VERSION ""

NS_ :

BS_:

BU_: WCM VPM VLM VKM UVM TIM TEST_TOOL_2 TEST_TOOL_1 TCP TCM TCCM3 TCCM STC SRR_SRR SRR_SLR SRR_RR SRR_RF SRR_LR_CR SRR_LF SIB SDM SCL SBZA_R SBZA_L SBM SADS RadioLow RSC RDCM PTM PDR PA NVM MTCM_R MTCM_L MSM_RR MSM_P MSM_LR MSM_D MSB2 MSB1 MRCM_R MRCM_L MFC LRR_HC LRR LIB1 IPC ICS_Info ICCM HVAC_FP_R HVAC_FP_F HUD_CAN HDLM FCM_LC FCM EPS EOCM_HCP2 EOCM_HCP1 EOCM ELM ECP_X1 ECP_MC ECP_E ECM EBCM DMS DEFC DCM CSM CMMb CMMa CGM BSM_MH BSM BCM ARS ARB APA AOS AMP ALC AHS AHL_AFL AGC

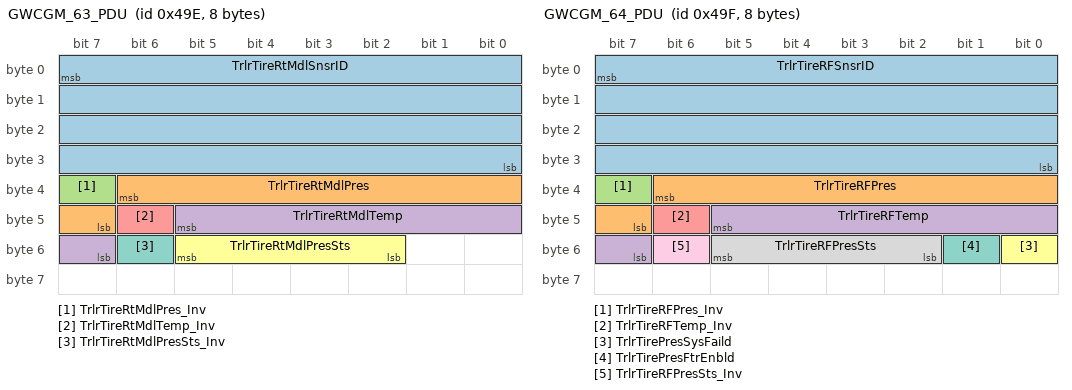
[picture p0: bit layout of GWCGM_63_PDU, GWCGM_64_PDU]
BO_ 1182 GWCGM_63_PDU: 8 CGM
 SG_ TrlrTireRtMdlSnsrID : 7|32@0+ (1,0) [0|4.29497e+009] "" CSM
 SG_ TrlrTireRtMdlPres : 38|8@0+ (4,0) [0|1020] "kPaG" CSM,VKM
 SG_ TrlrTireRtMdlPres_Inv : 39|1@0+ (1,0) [0|1] "" CSM,VKM
 SG_ TrlrTireRtMdlTemp : 45|7@0+ (1,-20) [-20|107] "degC" CSM
 SG_ TrlrTireRtMdlTemp_Inv : 46|1@0+ (1,0) [0|1] "" CSM
 SG_ TrlrTireRtMdlPresSts : 53|4@0+ (1,0) [0|8] "" CSM,VKM
 SG_ TrlrTireRtMdlPresSts_Inv : 54|1@0+ (1,0) [0|1] "" CSM,VKM

BO_ 1183 GWCGM_64_PDU: 8 CGM
 SG_ TrlrTireRFSnsrID : 7|32@0+ (1,0) [0|4.29497e+009] "" CSM
 SG_ TrlrTireRFPres : 38|8@0+ (4,0) [0|1020] "kPaG" CSM,VKM
 SG_ TrlrTireRFPres_Inv : 39|1@0+ (1,0) [0|1] "" CSM,VKM
 SG_ TrlrTireRFTemp : 45|7@0+ (1,-20) [-20|107] "degC" CSM
 SG_ TrlrTireRFTemp_Inv : 46|1@0+ (1,0) [0|1] "" CSM
 SG_ TrlrTirePresSysFaild : 48|1@0+ (1,0) [0|1] "" CSM
 SG_ TrlrTirePresFtrEnbld : 49|1@0+ (1,0) [0|1] "" CSM
 SG_ TrlrTireRFPresSts : 53|4@0+ (1,0) [0|8] "" CSM,VKM
 SG_ TrlrTireRFPresSts_Inv : 54|1@0+ (1,0) [0|1] "" CSM,VKM

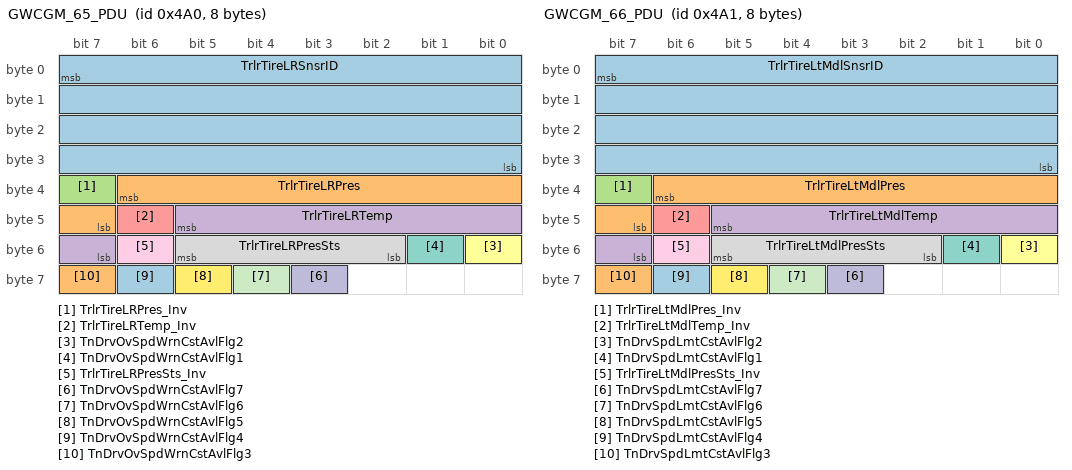
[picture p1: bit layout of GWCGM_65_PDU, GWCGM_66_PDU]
BO_ 1184 GWCGM_65_PDU: 8 CGM
 SG_ TrlrTireLRSnsrID : 7|32@0+ (1,0) [0|4.29497e+009] "" CSM
 SG_ TrlrTireLRPres : 38|8@0+ (4,0) [0|1020] "kPaG" CSM,VKM
 SG_ TrlrTireLRPres_Inv : 39|1@0+ (1,0) [0|1] "" CSM,VKM
 SG_ TrlrTireLRTemp : 45|7@0+ (1,-20) [-20|107] "degC" CSM
 SG_ TrlrTireLRTemp_Inv : 46|1@0+ (1,0) [0|1] "" CSM
 SG_ TnDrvOvSpdWrnCstAvlFlg2 : 48|1@0+ (1,0) [0|1] "" CSM,RadioLow,TCP
 SG_ TnDrvOvSpdWrnCstAvlFlg1 : 49|1@0+ (1,0) [0|1] "" CSM,RadioLow,TCP
 SG_ TrlrTireLRPresSts : 53|4@0+ (1,0) [0|8] "" CSM,VKM
 SG_ TrlrTireLRPresSts_Inv : 54|1@0+ (1,0) [0|1] "" CSM,VKM
 SG_ TnDrvOvSpdWrnCstAvlFlg7 : 59|1@0+ (1,0) [0|1] "" CSM,RadioLow,TCP
 SG_ TnDrvOvSpdWrnCstAvlFlg6 : 60|1@0+ (1,0) [0|1] "" CSM,RadioLow,TCP
 SG_ TnDrvOvSpdWrnCstAvlFlg5 : 61|1@0+ (1,0) [0|1] "" CSM,RadioLow,TCP
 SG_ TnDrvOvSpdWrnCstAvlFlg4 : 62|1@0+ (1,0) [0|1] "" CSM,RadioLow,TCP
 SG_ TnDrvOvSpdWrnCstAvlFlg3 : 63|1@0+ (1,0) [0|1] "" CSM,RadioLow,TCP

BO_ 1185 GWCGM_66_PDU: 8 CGM
 SG_ TrlrTireLtMdlSnsrID : 7|32@0+ (1,0) [0|4.29497e+009] "" CSM
 SG_ TrlrTireLtMdlPres : 38|8@0+ (4,0) [0|1020] "kPaG" CSM,VKM
 SG_ TrlrTireLtMdlPres_Inv : 39|1@0+ (1,0) [0|1] "" CSM,VKM
 SG_ TrlrTireLtMdlTemp : 45|7@0+ (1,-20) [-20|107] "degC" CSM
 SG_ TrlrTireLtMdlTemp_Inv : 46|1@0+ (1,0) [0|1] "" CSM
 SG_ TnDrvSpdLmtCstAvlFlg2 : 48|1@0+ (1,0) [0|1] "" CSM,RadioLow,TCP
 SG_ TnDrvSpdLmtCstAvlFlg1 : 49|1@0+ (1,0) [0|1] "" CSM,RadioLow,TCP
 SG_ TrlrTireLtMdlPresSts : 53|4@0+ (1,0) [0|8] "" CSM,VKM
 SG_ TrlrTireLtMdlPresSts_Inv : 54|1@0+ (1,0) [0|1] "" CSM,VKM
 SG_ TnDrvSpdLmtCstAvlFlg7 : 59|1@0+ (1,0) [0|1] "" CSM,RadioLow
 SG_ TnDrvSpdLmtCstAvlFlg6 : 60|1@0+ (1,0) [0|1] "" CSM,RadioLow,TCP
 SG_ TnDrvSpdLmtCstAvlFlg5 : 61|1@0+ (1,0) [0|1] "" CSM,RadioLow,TCP
 SG_ TnDrvSpdLmtCstAvlFlg4 : 62|1@0+ (1,0) [0|1] "" CSM,RadioLow,TCP
 SG_ TnDrvSpdLmtCstAvlFlg3 : 63|1@0+ (1,0) [0|1] "" CSM,RadioLow,TCP

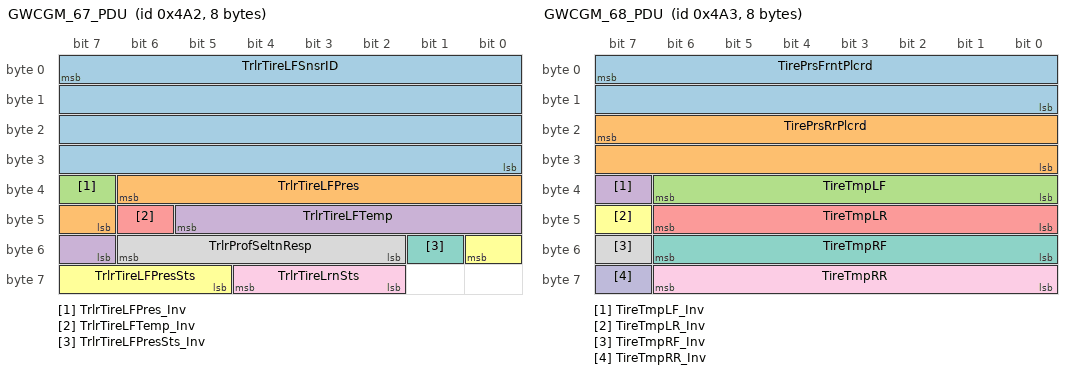
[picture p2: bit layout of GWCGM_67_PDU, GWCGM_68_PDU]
BO_ 1186 GWCGM_67_PDU: 8 CGM
 SG_ TrlrTireLFSnsrID : 7|32@0+ (1,0) [0|4.29497e+009] "" CSM
 SG_ TrlrTireLFPres : 38|8@0+ (4,0) [0|1020] "kPaG" CSM,VKM
 SG_ TrlrTireLFPres_Inv : 39|1@0+ (1,0) [0|1] "" CSM,VKM
 SG_ TrlrTireLFTemp : 45|7@0+ (1,-20) [-20|107] "degC" CSM
 SG_ TrlrTireLFTemp_Inv : 46|1@0+ (1,0) [0|1] "" CSM
 SG_ TrlrTireLFPresSts : 48|4@0+ (1,0) [0|8] "" CSM,VKM
 SG_ TrlrTireLFPresSts_Inv : 49|1@0+ (1,0) [0|1] "" CSM,VKM
 SG_ TrlrProfSeltnResp : 54|5@0+ (1,0) [0|21] "" CSM
 SG_ TrlrTireLrnSts : 60|3@0+ (1,0) [0|4] "" CSM

BO_ 1187 GWCGM_68_PDU: 8 CGM
 SG_ TirePrsFrntPlcrd : 7|16@0+ (0.0625,0) [0|4095.94] "kPaG" TCP
 SG_ TirePrsRrPlcrd : 23|16@0+ (0.0625,0) [0|4095.94] "kPaG" TCP
 SG_ TireTmpLF : 38|7@0+ (1,-20) [-20|107] "deg C" CSM,PDR
 SG_ TireTmpLF_Inv : 39|1@0+ (1,0) [0|1] "" CSM,PDR
 SG_ TireTmpLR : 46|7@0+ (1,-20) [-20|107] "deg C" CSM,PDR
 SG_ TireTmpLR_Inv : 47|1@0+ (1,0) [0|1] "" CSM,PDR
 SG_ TireTmpRF : 54|7@0+ (1,-20) [-20|107] "deg C" CSM,PDR
 SG_ TireTmpRF_Inv : 55|1@0+ (1,0) [0|1] "" CSM,PDR
 SG_ TireTmpRR : 62|7@0+ (1,-20) [-20|107] "deg C" CSM,PDR
 SG_ TireTmpRR_Inv : 63|1@0+ (1,0) [0|1] "" CSM,PDR

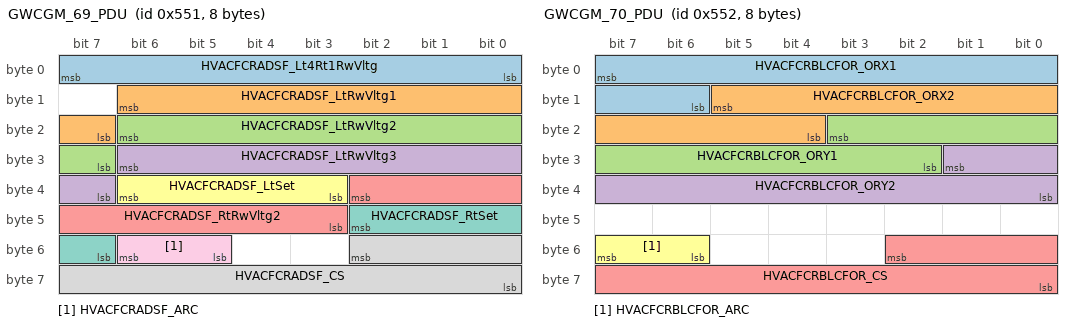
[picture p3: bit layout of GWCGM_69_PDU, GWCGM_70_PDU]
BO_ 1361 GWCGM_69_PDU: 8 HVAC_FP_F
 SG_ HVACFCRADSF_Lt4Rt1RwVltg : 7|8@0+ (0.02,0) [0|5.1] "Volts" Vector__XXX
 SG_ HVACFCRADSF_LtRwVltg1 : 14|8@0+ (0.02,0) [0|5.1] "Volts" Vector__XXX
 SG_ HVACFCRADSF_LtRwVltg2 : 22|8@0+ (0.02,0) [0|5.1] "Volts" Vector__XXX
 SG_ HVACFCRADSF_LtRwVltg3 : 30|8@0+ (0.02,0) [0|5.1] "Volts" Vector__XXX
 SG_ HVACFCRADSF_RtRwVltg2 : 34|8@0+ (0.02,0) [0|5.1] "Volts" Vector__XXX
 SG_ HVACFCRADSF_LtSet : 38|4@0+ (1,0) [0|8] "" Vector__XXX
 SG_ HVACFCRADSF_RtSet : 42|4@0+ (1,0) [0|8] "" Vector__XXX
 SG_ HVACFCRADSF_CS : 50|11@0+ (1,0) [0|2047] "" Vector__XXX
 SG_ HVACFCRADSF_ARC : 54|2@0+ (1,0) [0|3] "Counts" Vector__XXX

BO_ 1362 GWCGM_70_PDU: 8 HVAC_FP_F
 SG_ HVACFCRBLCFOR_ORX1 : 7|10@0+ (1,0) [0|1023] "Counts" Vector__XXX
 SG_ HVACFCRBLCFOR_ORX2 : 13|10@0+ (1,0) [0|1023] "Counts" Vector__XXX
 SG_ HVACFCRBLCFOR_ORY1 : 19|10@0+ (1,0) [0|1023] "Counts" Vector__XXX
 SG_ HVACFCRBLCFOR_ORY2 : 25|10@0+ (1,0) [0|1023] "Counts" Vector__XXX
 SG_ HVACFCRBLCFOR_CS : 50|11@0+ (1,0) [0|2047] "" Vector__XXX
 SG_ HVACFCRBLCFOR_ARC : 55|2@0+ (1,0) [0|3] "Counts" Vector__XXX

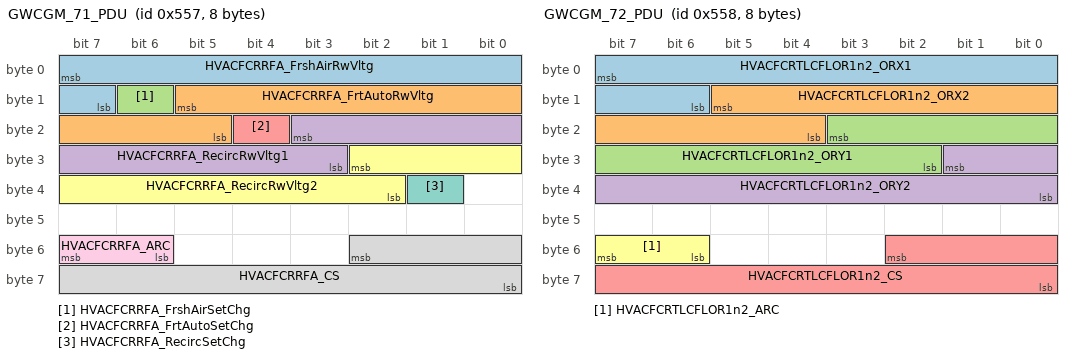
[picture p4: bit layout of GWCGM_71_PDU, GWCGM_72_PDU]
BO_ 1367 GWCGM_71_PDU: 8 HVAC_FP_F
 SG_ HVACFCRRFA_FrshAirRwVltg : 7|9@0+ (0.01,0) [0|5.11] "Volts" Vector__XXX
 SG_ HVACFCRRFA_FrtAutoRwVltg : 13|9@0+ (0.01,0) [0|5.11] "Volts" Vector__XXX
 SG_ HVACFCRRFA_FrshAirSetChg : 14|1@0+ (1,0) [0|1] "" Vector__XXX
 SG_ HVACFCRRFA_RecircRwVltg1 : 19|9@0+ (0.01,0) [0|5.11] "Volts" Vector__XXX
 SG_ HVACFCRRFA_FrtAutoSetChg : 20|1@0+ (1,0) [0|1] "" Vector__XXX
 SG_ HVACFCRRFA_RecircRwVltg2 : 26|9@0+ (0.01,0) [0|5.11] "Volts" Vector__XXX
 SG_ HVACFCRRFA_RecircSetChg : 33|1@0+ (1,0) [0|1] "" Vector__XXX
 SG_ HVACFCRRFA_CS : 50|11@0+ (1,0) [0|2047] "" Vector__XXX
 SG_ HVACFCRRFA_ARC : 55|2@0+ (1,0) [0|3] "Counts" Vector__XXX

BO_ 1368 GWCGM_72_PDU: 8 HVAC_FP_F
 SG_ HVACFCRTLCFLOR1n2_ORX1 : 7|10@0+ (1,0) [0|1023] "Counts" Vector__XXX
 SG_ HVACFCRTLCFLOR1n2_ORX2 : 13|10@0+ (1,0) [0|1023] "Counts" Vector__XXX
 SG_ HVACFCRTLCFLOR1n2_ORY1 : 19|10@0+ (1,0) [0|1023] "Counts" Vector__XXX
 SG_ HVACFCRTLCFLOR1n2_ORY2 : 25|10@0+ (1,0) [0|1023] "Counts" Vector__XXX
 SG_ HVACFCRTLCFLOR1n2_CS : 50|11@0+ (1,0) [0|2047] "" Vector__XXX
 SG_ HVACFCRTLCFLOR1n2_ARC : 55|2@0+ (1,0) [0|3] "Counts" Vector__XXX

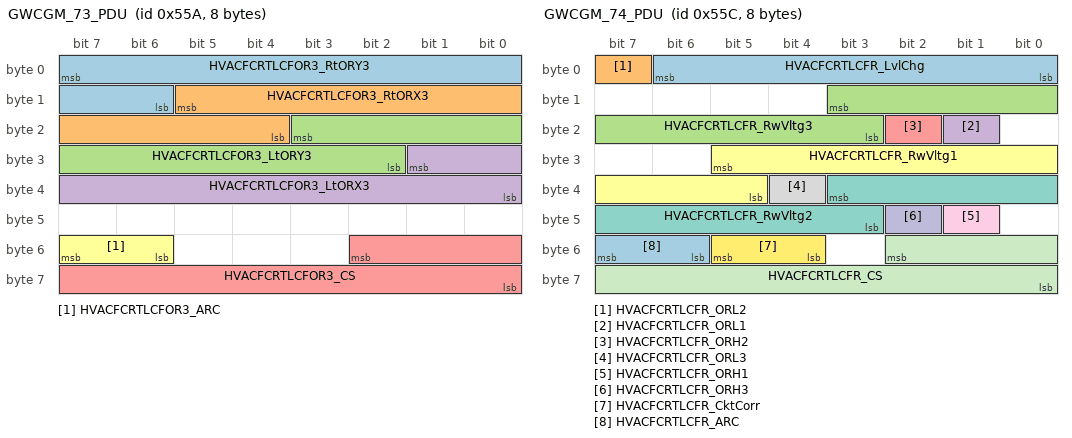
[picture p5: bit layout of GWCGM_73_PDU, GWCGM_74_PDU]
BO_ 1370 GWCGM_73_PDU: 8 HVAC_FP_F
 SG_ HVACFCRTLCFOR3_RtORY3 : 7|10@0+ (1,0) [0|1023] "Counts" Vector__XXX
 SG_ HVACFCRTLCFOR3_RtORX3 : 13|10@0+ (1,0) [0|1023] "Counts" Vector__XXX
 SG_ HVACFCRTLCFOR3_LtORY3 : 19|10@0+ (1,0) [0|1023] "Counts" Vector__XXX
 SG_ HVACFCRTLCFOR3_LtORX3 : 25|10@0+ (1,0) [0|1023] "Counts" Vector__XXX
 SG_ HVACFCRTLCFOR3_CS : 50|11@0+ (1,0) [0|2047] "" Vector__XXX
 SG_ HVACFCRTLCFOR3_ARC : 55|2@0+ (1,0) [0|3] "" Vector__XXX

BO_ 1372 GWCGM_74_PDU: 8 HVAC_FP_F
 SG_ HVACFCRTLCFR_LvlChg : 6|7@0- (1,0) [-64|63] "Counts" Vector__XXX
 SG_ HVACFCRTLCFR_ORL2 : 7|1@0+ (1,0) [0|1] "" Vector__XXX
 SG_ HVACFCRTLCFR_RwVltg3 : 11|9@0+ (0.01,0) [0|5.11] "Volts" Vector__XXX
 SG_ HVACFCRTLCFR_ORL1 : 17|1@0+ (1,0) [0|1] "" Vector__XXX
 SG_ HVACFCRTLCFR_ORH2 : 18|1@0+ (1,0) [0|1] "" Vector__XXX
 SG_ HVACFCRTLCFR_RwVltg1 : 29|9@0+ (0.01,0) [0|5.11] "Volts" Vector__XXX
 SG_ HVACFCRTLCFR_RwVltg2 : 35|9@0+ (0.01,0) [0|5.11] "Volts" Vector__XXX
 SG_ HVACFCRTLCFR_ORL3 : 36|1@0+ (1,0) [0|1] "" Vector__XXX
 SG_ HVACFCRTLCFR_ORH1 : 41|1@0+ (1,0) [0|1] "" Vector__XXX
 SG_ HVACFCRTLCFR_ORH3 : 42|1@0+ (1,0) [0|1] "" Vector__XXX
 SG_ HVACFCRTLCFR_CS : 50|11@0+ (1,0) [0|2047] "" Vector__XXX
 SG_ HVACFCRTLCFR_CktCorr : 53|2@0+ (1,0) [0|2] "" Vector__XXX
 SG_ HVACFCRTLCFR_ARC : 55|2@0+ (1,0) [0|3] "" Vector__XXX

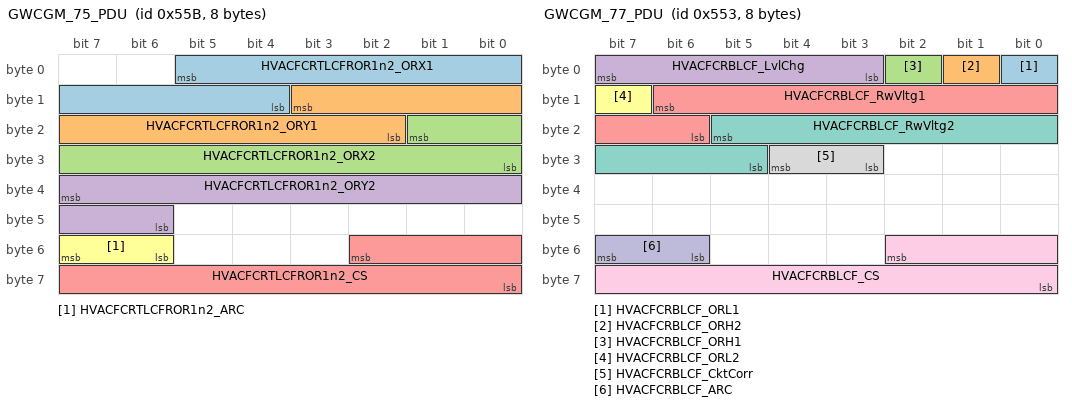
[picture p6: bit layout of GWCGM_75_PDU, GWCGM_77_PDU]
BO_ 1371 GWCGM_75_PDU: 8 HVAC_FP_F
 SG_ HVACFCRTLCFROR1n2_ORX1 : 5|10@0+ (1,0) [0|1023] "Counts" Vector__XXX
 SG_ HVACFCRTLCFROR1n2_ORY1 : 11|10@0+ (1,0) [0|1023] "Counts" Vector__XXX
 SG_ HVACFCRTLCFROR1n2_ORX2 : 17|10@0+ (1,0) [0|1023] "Counts" Vector__XXX
 SG_ HVACFCRTLCFROR1n2_ORY2 : 39|10@0+ (1,0) [0|1023] "Counts" Vector__XXX
 SG_ HVACFCRTLCFROR1n2_CS : 50|11@0+ (1,0) [0|2047] "" Vector__XXX
 SG_ HVACFCRTLCFROR1n2_ARC : 55|2@0+ (1,0) [0|3] "Counts" Vector__XXX

BO_ 1295 GWCGM_76_PDU: 8 HVAC_FP_F
 SG_ HVACFCRACH_CompSetRwVltg : 7|9@0+ (0.01,0) [0|5.11] "Volts" Vector__XXX
 SG_ HVACFCRACH_HtrSetRwVltg : 12|9@0+ (0.01,0) [0|5.11] "Volts" Vector__XXX
 SG_ HVACFCRACH_CompSetChg : 13|1@0+ (1,0) [0|1] "" Vector__XXX
 SG_ HVACFCRACH_HtrSetChg : 14|1@0+ (1,0) [0|1] "" Vector__XXX
 SG_ HVACFCRACH_HtrSet : 17|2@0+ (1,0) [0|2] "" Vector__XXX
 SG_ HVACFCRACH_ARC : 19|2@0+ (1,0) [0|3] "Counts" Vector__XXX
 SG_ HVACFCRL_RwVltg : 31|9@0+ (0.01,0) [0|5.11] "Volts" Vector__XXX
 SG_ RHVSLF_HtdCushBckLvlChgDn : 32|1@0+ (1,0) [0|1] "" Vector__XXX
 SG_ RHVSLF_HtdBckLvlChgDn : 33|1@0+ (1,0) [0|1] "" Vector__XXX
 SG_ RHVSLF_VntLvlChgUp : 34|1@0+ (1,0) [0|1] "" Vector__XXX
 SG_ RHVSLF_VntLvlChgDn : 35|1@0+ (1,0) [0|1] "" Vector__XXX
 SG_ RHVSLF_HtdCushBckLvlChgUp : 36|1@0+ (1,0) [0|1] "" Vector__XXX
 SG_ RHVSLF_HtdBckLvlChgUp : 37|1@0+ (1,0) [0|1] "" Vector__XXX
 SG_ HVACFCRL_SetChg : 38|1@0+ (1,0) [0|1] "" Vector__XXX
 SG_ HtdStBckCushStckSwLF : 40|1@0+ (1,0) [0|1] "" Vector__XXX
 SG_ HVACFrtCtlReqSyncRrSetChg : 41|1@0+ (1,0) [0|1] "" Vector__XXX
 SG_ RHVSRF_VntLvlChgUp : 42|1@0+ (1,0) [0|1] "" Vector__XXX
 SG_ RHVSRF_HtdCushBckLvlChgUp : 43|1@0+ (1,0) [0|1] "" Vector__XXX
 SG_ RHVSRF_HtdCushBckLvlChgDn : 44|1@0+ (1,0) [0|1] "" Vector__XXX
 SG_ RHVSRF_VntLvlChgDn : 45|1@0+ (1,0) [0|1] "" Vector__XXX
 SG_ RHVSRF_HtdBckLvlChgUp : 46|1@0+ (1,0) [0|1] "" Vector__XXX
 SG_ RHVSRF_HtdBckLvlChgDn : 47|1@0+ (1,0) [0|1] "" Vector__XXX
 SG_ VntStStckSwRF : 49|1@0+ (1,0) [0|1] "" Vector__XXX
 SG_ VntStStckSwLF : 50|1@0+ (1,0) [0|1] "" Vector__XXX
 SG_ HtdVntStSwActvRF : 51|1@0+ (1,0) [0|1] "" Vector__XXX
 SG_ HtdVntStSwActvLF : 52|1@0+ (1,0) [0|1] "" Vector__XXX
 SG_ HtdStBckStckSwRF : 53|1@0+ (1,0) [0|1] "" Vector__XXX
 SG_ HtdStBckStckSwLF : 54|1@0+ (1,0) [0|1] "" Vector__XXX
 SG_ HtdStBckCushStckSwRF : 55|1@0+ (1,0) [0|1] "" Vector__XXX

BO_ 1363 GWCGM_77_PDU: 8 HVAC_FP_F
 SG_ HVACFCRBLCF_ORL1 : 0|1@0+ (1,0) [0|1] "" Vector__XXX
 SG_ HVACFCRBLCF_ORH2 : 1|1@0+ (1,0) [0|1] "" Vector__XXX
 SG_ HVACFCRBLCF_ORH1 : 2|1@0+ (1,0) [0|1] "" Vector__XXX
 SG_ HVACFCRBLCF_LvlChg : 7|5@0- (1,0) [-16|15] "Counts" Vector__XXX
 SG_ HVACFCRBLCF_RwVltg1 : 14|9@0+ (0.01,0) [0|5.11] "Volts" Vector__XXX
 SG_ HVACFCRBLCF_ORL2 : 15|1@0+ (1,0) [0|1] "" Vector__XXX
 SG_ HVACFCRBLCF_RwVltg2 : 21|9@0+ (0.01,0) [0|5.11] "Volts" Vector__XXX
 SG_ HVACFCRBLCF_CktCorr : 28|2@0+ (1,0) [0|2] "" Vector__XXX
 SG_ HVACFCRBLCF_CS : 50|11@0+ (1,0) [0|2047] "" Vector__XXX
 SG_ HVACFCRBLCF_ARC : 55|2@0+ (1,0) [0|3] "Counts" Vector__XXX

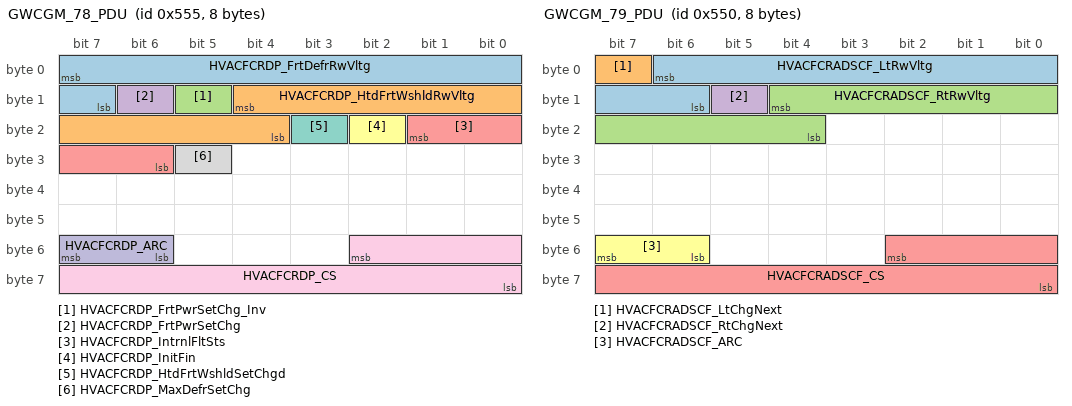
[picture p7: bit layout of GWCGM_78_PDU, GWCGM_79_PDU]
BO_ 1365 GWCGM_78_PDU: 8 HVAC_FP_F
 SG_ HVACFCRDP_FrtDefrRwVltg : 7|9@0+ (0.01,0) [0|5.11] "Volts" Vector__XXX
 SG_ HVACFCRDP_HtdFrtWshldRwVltg : 12|9@0+ (0.01,0) [0|5.11] "Volts" Vector__XXX
 SG_ HVACFCRDP_FrtPwrSetChg_Inv : 13|1@0+ (1,0) [0|1] "" Vector__XXX
 SG_ HVACFCRDP_FrtPwrSetChg : 14|1@0+ (1,0) [0|1] "" Vector__XXX
 SG_ HVACFCRDP_IntrnlFltSts : 17|4@0+ (1,0) [0|15] "" Vector__XXX
 SG_ HVACFCRDP_InitFin : 18|1@0+ (1,0) [0|1] "" Vector__XXX
 SG_ HVACFCRDP_HtdFrtWshldSetChgd : 19|1@0+ (1,0) [0|1] "" Vector__XXX
 SG_ HVACFCRDP_MaxDefrSetChg : 29|1@0+ (1,0) [0|1] "" Vector__XXX
 SG_ HVACFCRDP_CS : 50|11@0+ (1,0) [0|2047] "" Vector__XXX
 SG_ HVACFCRDP_ARC : 55|2@0+ (1,0) [0|3] "Counts" Vector__XXX

BO_ 1360 GWCGM_79_PDU: 8 HVAC_FP_F
 SG_ HVACFCRADSCF_LtRwVltg : 6|9@0+ (0.01,0) [0|5.11] "Volts" Vector__XXX
 SG_ HVACFCRADSCF_LtChgNext : 7|1@0+ (1,0) [0|1] "" Vector__XXX
 SG_ HVACFCRADSCF_RtRwVltg : 12|9@0+ (0.01,0) [0|5.11] "Volts" Vector__XXX
 SG_ HVACFCRADSCF_RtChgNext : 13|1@0+ (1,0) [0|1] "" Vector__XXX
 SG_ HVACFCRADSCF_CS : 50|11@0+ (1,0) [0|2047] "" Vector__XXX
 SG_ HVACFCRADSCF_ARC : 55|2@0+ (1,0) [0|3] "Counts" Vector__XXX

BO_ 1299 GWCGM_80_PDU: 6 HVAC_FP_F
 SG_ HVACFCRBLR_RwVltg2 : 2|9@0+ (0.01,0) [0|5.11] "Volts" Vector__XXX
 SG_ HVACFCRBLR_LvlChg : 7|5@0- (1,0) [-16|15] "" Vector__XXX
 SG_ HVACFCRBLR_Lvl : 8|4@0+ (1,0) [0|15] "" Vector__XXX
 SG_ HVACFCRBLR_LvlActv : 9|1@0+ (1,0) [0|1] "" Vector__XXX
 SG_ HVACFCRBLR_RwVltg1 : 20|9@0+ (0.01,0) [0|5.11] "Volts" Vector__XXX

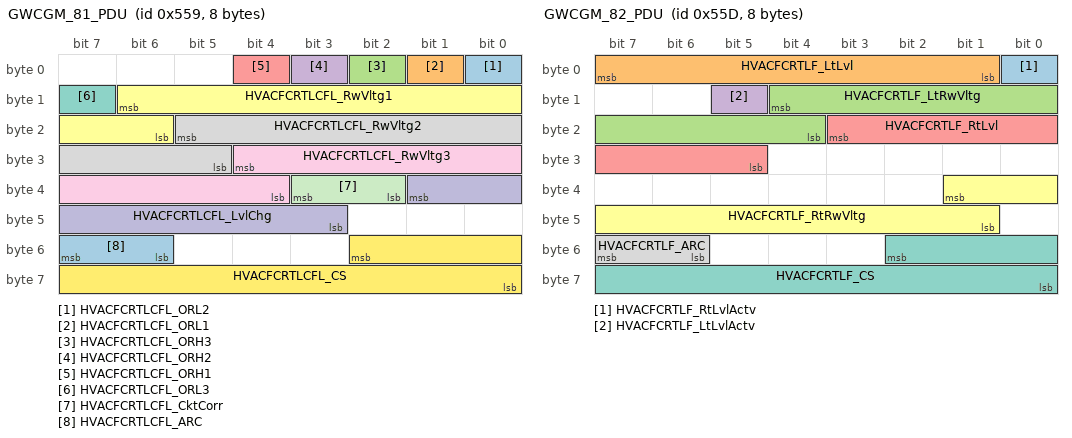
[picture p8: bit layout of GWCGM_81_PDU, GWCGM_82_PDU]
BO_ 1369 GWCGM_81_PDU: 8 HVAC_FP_F
 SG_ HVACFCRTLCFL_ORL2 : 0|1@0+ (1,0) [0|1] "" Vector__XXX
 SG_ HVACFCRTLCFL_ORL1 : 1|1@0+ (1,0) [0|1] "" Vector__XXX
 SG_ HVACFCRTLCFL_ORH3 : 2|1@0+ (1,0) [0|1] "" Vector__XXX
 SG_ HVACFCRTLCFL_ORH2 : 3|1@0+ (1,0) [0|1] "" Vector__XXX
 SG_ HVACFCRTLCFL_ORH1 : 4|1@0+ (1,0) [0|1] "" Vector__XXX
 SG_ HVACFCRTLCFL_RwVltg1 : 14|9@0+ (0.01,0) [0|5.11] "Volts" Vector__XXX
 SG_ HVACFCRTLCFL_ORL3 : 15|1@0+ (1,0) [0|1] "" Vector__XXX
 SG_ HVACFCRTLCFL_RwVltg2 : 21|9@0+ (0.01,0) [0|5.11] "Volts" Vector__XXX
 SG_ HVACFCRTLCFL_RwVltg3 : 28|9@0+ (0.01,0) [0|5.11] "Volts" Vector__XXX
 SG_ HVACFCRTLCFL_LvlChg : 33|7@0- (1,0) [-64|63] "Counts" Vector__XXX
 SG_ HVACFCRTLCFL_CktCorr : 35|2@0+ (1,0) [0|2] "" Vector__XXX
 SG_ HVACFCRTLCFL_CS : 50|11@0+ (1,0) [0|2047] "" Vector__XXX
 SG_ HVACFCRTLCFL_ARC : 55|2@0+ (1,0) [0|3] "Counts" Vector__XXX

BO_ 1373 GWCGM_82_PDU: 8 HVAC_FP_F
 SG_ HVACFCRTLF_RtLvlActv : 0|1@0+ (1,0) [0|1] "" Vector__XXX
 SG_ HVACFCRTLF_LtLvl : 7|7@0+ (1,-16) [-16|111] "Counts" Vector__XXX
 SG_ HVACFCRTLF_LtRwVltg : 12|9@0+ (0.01,0) [0|5.11] "Volts" Vector__XXX
 SG_ HVACFCRTLF_LtLvlActv : 13|1@0+ (1,0) [0|1] "" Vector__XXX
 SG_ HVACFCRTLF_RtLvl : 19|7@0+ (1,-16) [-16|111] "Counts" Vector__XXX
 SG_ HVACFCRTLF_RtRwVltg : 33|9@0+ (0.01,0) [0|5.11] "Volts" Vector__XXX
 SG_ HVACFCRTLF_CS : 50|11@0+ (1,0) [0|2047] "" Vector__XXX
 SG_ HVACFCRTLF_ARC : 55|2@0+ (1,0) [0|3] "Counts" Vector__XXX

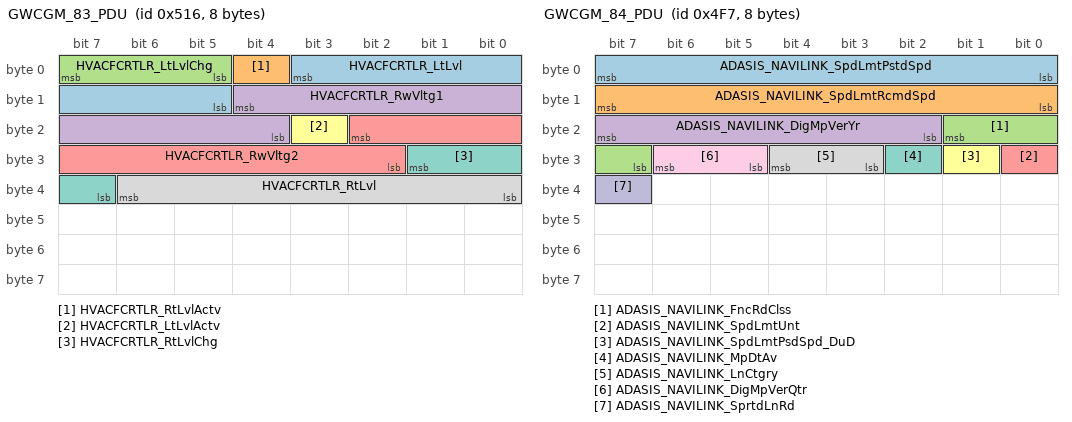
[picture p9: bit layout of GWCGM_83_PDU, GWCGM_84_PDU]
BO_ 1302 GWCGM_83_PDU: 8 HVAC_FP_F
 SG_ HVACFCRTLR_LtLvl : 3|7@0+ (1,-16) [-16|111] "" Vector__XXX
 SG_ HVACFCRTLR_RtLvlActv : 4|1@0+ (1,0) [0|1] "" Vector__XXX
 SG_ HVACFCRTLR_LtLvlChg : 7|3@0- (1,0) [-4|3] "" Vector__XXX
 SG_ HVACFCRTLR_RwVltg1 : 12|9@0+ (0.01,0) [0|5.11] "Volts" Vector__XXX
 SG_ HVACFCRTLR_RwVltg2 : 18|9@0+ (0.01,0) [0|5.11] "Volts" Vector__XXX
 SG_ HVACFCRTLR_LtLvlActv : 19|1@0+ (1,0) [0|1] "" Vector__XXX
 SG_ HVACFCRTLR_RtLvlChg : 25|3@0- (1,0) [-4|3] "" Vector__XXX
 SG_ HVACFCRTLR_RtLvl : 38|7@0+ (1,-16) [-16|111] "" Vector__XXX

BO_ 1271 GWCGM_84_PDU: 8 CSM
 SG_ ADASIS_NAVILINK_SpdLmtPstdSpd : 7|8@0+ (1,0) [0|255] "" IPC
 SG_ ADASIS_NAVILINK_SpdLmtRcmdSpd : 15|8@0+ (1,0) [0|255] "" IPC
 SG_ ADASIS_NAVILINK_FncRdClss : 17|3@0+ (1,0) [0|7] "" Vector__XXX
 SG_ ADASIS_NAVILINK_DigMpVerYr : 23|6@0+ (1,0) [0|63] "" Vector__XXX
 SG_ ADASIS_NAVILINK_SpdLmtUnt : 24|1@0+ (1,0) [0|1] "" IPC
 SG_ ADASIS_NAVILINK_SpdLmtPsdSpd_DuD : 25|1@0+ (1,0) [0|1] "" IPC
 SG_ ADASIS_NAVILINK_MpDtAv : 26|1@0+ (1,0) [0|1] "" Vector__XXX
 SG_ ADASIS_NAVILINK_LnCtgry : 28|2@0+ (1,0) [0|3] "" Vector__XXX
 SG_ ADASIS_NAVILINK_DigMpVerQtr : 30|2@0+ (1,0) [0|3] "" Vector__XXX
 SG_ ADASIS_NAVILINK_SprtdLnRd : 39|1@0+ (1,0) [0|1] "" Vector__XXX

BO_ 1376 GWCGM_85_PDU: 6 CGM
 SG_ VehIdNmDig1 : 7|8@0+ (1,0) [0|255] "" CSM,RadioLow,TCP

BO_ 1399 GWCGM_86_PDU: 6 IPC
 SG_ VehStbEnhCurrStReq : 1|2@0+ (1,0) [0|2] "" Vector__XXX
 SG_ VehStbCompMdCurrStReq : 3|2@0+ (1,0) [0|2] "" Vector__XXX
 SG_ TCStmpDsblReqConf : 5|2@0+ (1,0) [0|2] "" Vector__XXX
 SG_ TCSCurrStReq : 7|2@0+ (1,0) [0|2] "" Vector__XXX

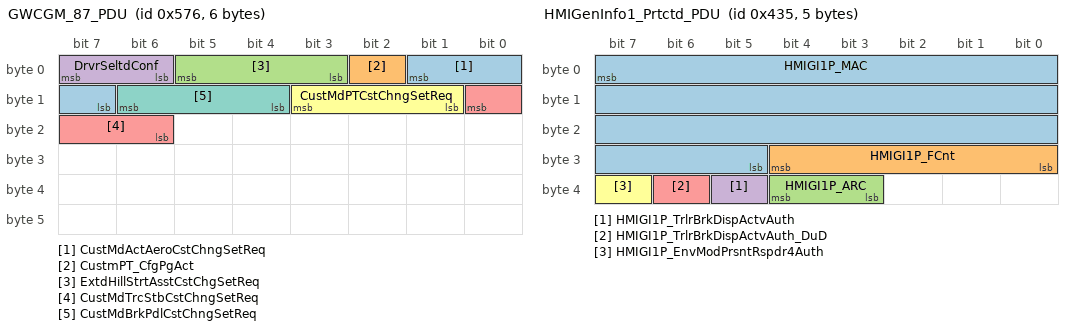
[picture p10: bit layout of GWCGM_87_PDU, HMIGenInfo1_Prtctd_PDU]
BO_ 1398 GWCGM_87_PDU: 6 CSM
 SG_ CustMdActAeroCstChngSetReq : 1|3@0+ (1,0) [0|7] "" Vector__XXX
 SG_ CustmPT_CfgPgAct : 2|1@0+ (1,0) [0|1] "" Vector__XXX
 SG_ ExtdHillStrtAsstCstChgSetReq : 5|3@0+ (1,0) [0|7] "" Vector__XXX
 SG_ DrvrSeltdConf : 7|2@0+ (1,0) [0|3] "" Vector__XXX
 SG_ CustMdTrcStbCstChngSetReq : 8|3@0+ (1,0) [0|7] "" Vector__XXX
 SG_ CustMdPTCstChngSetReq : 11|3@0+ (1,0) [0|7] "" Vector__XXX
 SG_ CustMdBrkPdlCstChngSetReq : 14|3@0+ (1,0) [0|7] "" Vector__XXX

BO_ 1375 GWCGM_88_PDU: 6 CGM
 SG_ BatVltOBD : 6|8@0+ (0.1,3) [3|28.5] "volts" CSM,IPC
 SG_ BatVltOBD_Inv : 7|1@0+ (1,0) [0|1] "" CSM,IPC

BO_ 1400 GWCGM_89_PDU: 6 IPC
 SG_ PTExPrtclFltrMnlRgnRq : 5|1@0+ (1,0) [0|1] "" CGM,CSM
 SG_ CustmStbCtlRdctReqConf : 7|2@0+ (1,0) [0|2] "" CGM

BO_ 1383 GWCGM_90_PDU: 8 CGM
 SG_ OTARC_RejCrdntnECP_MC : 0|1@0+ (1,0) [0|1] "" HVAC_FP_F
 SG_ OTARC_RejCrdntnBSM_MH : 1|1@0+ (1,0) [0|1] "" HVAC_FP_F
 SG_ OTARC_RejCrdntnECP_X2 : 2|1@0+ (1,0) [0|1] "" HVAC_FP_F
 SG_ OTARC_RejCrdntnECP_X1 : 3|1@0+ (1,0) [0|1] "" HVAC_FP_F
 SG_ OTARC_RejCrdntnECM : 4|1@0+ (1,0) [0|1] "" HVAC_FP_F
 SG_ OTARC_RejCrdntnEBCM : 5|1@0+ (1,0) [0|1] "" HVAC_FP_F
 SG_ OTARC_RejCrdntnBSM : 6|1@0+ (1,0) [0|1] "" HVAC_FP_F
 SG_ OTARC_RejCrdntnBCM : 7|1@0+ (1,0) [0|1] "" HVAC_FP_F
 SG_ OTARC_RejCrdntnECU_19 : 8|1@0+ (1,0) [0|1] "" HVAC_FP_F
 SG_ OTARC_RejCrdntnECU_18 : 9|1@0+ (1,0) [0|1] "" HVAC_FP_F
 SG_ OTARC_RejCrdntnECU_17 : 10|1@0+ (1,0) [0|1] "" HVAC_FP_F
 SG_ OTARC_RejCrdntnECU_16 : 11|1@0+ (1,0) [0|1] "" HVAC_FP_F
 SG_ OTARC_RejCrdntnECU_15 : 12|1@0+ (1,0) [0|1] "" HVAC_FP_F
 SG_ OTARC_RejCrdntnECU_14 : 13|1@0+ (1,0) [0|1] "" HVAC_FP_F
 SG_ OTARC_RejCrdntnECU_13 : 14|1@0+ (1,0) [0|1] "" HVAC_FP_F
 SG_ OTARC_RejCrdntnECP_S : 15|1@0+ (1,0) [0|1] "" HVAC_FP_F
 SG_ OTARC_RejCrdntnECU_27 : 16|1@0+ (1,0) [0|1] "" HVAC_FP_F
 SG_ OTARC_RejCrdntnECU_26 : 17|1@0+ (1,0) [0|1] "" HVAC_FP_F
 SG_ OTARC_RejCrdntnECU_25 : 18|1@0+ (1,0) [0|1] "" HVAC_FP_F
 SG_ OTARC_RejCrdntnECU_24 : 19|1@0+ (1,0) [0|1] "" HVAC_FP_F
 SG_ OTARC_RejCrdntnECU_23 : 20|1@0+ (1,0) [0|1] "" HVAC_FP_F
 SG_ OTARC_RejCrdntnECU_22 : 21|1@0+ (1,0) [0|1] "" HVAC_FP_F
 SG_ OTARC_RejCrdntnECU_21 : 22|1@0+ (1,0) [0|1] "" HVAC_FP_F
 SG_ OTARC_RejCrdntnECU_20 : 23|1@0+ (1,0) [0|1] "" HVAC_FP_F
 SG_ OTARC_RejCrdntnTCM : 24|1@0+ (1,0) [0|1] "" HVAC_FP_F
 SG_ OTARC_RejCrdntnICCM : 25|1@0+ (1,0) [0|1] "" HVAC_FP_F
 SG_ OTARC_RejCrdntnFICM : 26|1@0+ (1,0) [0|1] "" HVAC_FP_F
 SG_ OTARC_RejCrdntnECU_32 : 27|1@0+ (1,0) [0|1] "" HVAC_FP_F
 SG_ OTARC_RejCrdntnECU_31 : 28|1@0+ (1,0) [0|1] "" HVAC_FP_F
 SG_ OTARC_RejCrdntnECU_30 : 29|1@0+ (1,0) [0|1] "" HVAC_FP_F
 SG_ OTARC_RejCrdntnECU_29 : 30|1@0+ (1,0) [0|1] "" HVAC_FP_F
 SG_ OTARC_RejCrdntnECU_28 : 31|1@0+ (1,0) [0|1] "" HVAC_FP_F

BO_ 514 GWCGM_93_PDU: 6 CGM
 SG_ PrplDispEngPwr : 7|13@0+ (0.5,-325) [-325|3770.5] "" CSM,PDR

BO_ 1080 HMIGenInfo1_PCSM_PDU: 8 IPC
 SG_ HMIGenInfo1_PCSM : 0|64@1+ (1,0) [0|1.84467e+019] "" Vector__XXX

BO_ 1077 HMIGenInfo1_Prtctd_PDU: 5 IPC
 SG_ HMIGI1P_MAC : 7|27@0+ (1,0) [0|1.34218e+008] "" Vector__XXX
 SG_ HMIGI1P_FCnt : 28|5@0+ (1,0) [0|31] "" Vector__XXX
 SG_ HMIGI1P_ARC : 36|2@0+ (1,0) [0|3] "" Vector__XXX
 SG_ HMIGI1P_TrlrBrkDispActvAuth : 37|1@0+ (1,0) [0|1] "" Vector__XXX
 SG_ HMIGI1P_TrlrBrkDispActvAuth_DuD : 38|1@0+ (1,0) [0|1] "" Vector__XXX
 SG_ HMIGI1P_EnvModPrsntRspdr4Auth : 39|1@0+ (1,0) [0|1] "" Vector__XXX

BO_ 1421 HMIGenInfo2_PCSM_PDU: 8 IPC
 SG_ HMIGenInfo2_PCSM : 0|64@1+ (1,0) [0|1.84467e+019] "" Vector__XXX

BO_ 623 HMIGenInfo2_Prtctd_PDU: 5 IPC
 SG_ HMIGI2P_MAC : 7|27@0+ (1,0) [0|1.34218e+008] "" Vector__XXX
 SG_ HMIGI2P_FCnt : 28|5@0+ (1,0) [0|31] "" Vector__XXX
 SG_ HMIGI2P_ARC : 37|2@0+ (1,0) [0|3] "" Vector__XXX
 SG_ HMIGI2P_LnFllwgInterFltDtdAuth : 38|1@0+ (1,0) [0|1] "" Vector__XXX
 SG_ HMIGI2P_IPCFlrIndOnAuth : 39|1@0+ (1,0) [0|1] "" Vector__XXX

BO_ 1081 HMIInds1_PCSM_PDU: 8 IPC
 SG_ HMIInds1_PCSM : 0|64@1+ (1,0) [0|1.84467e+019] "" Vector__XXX

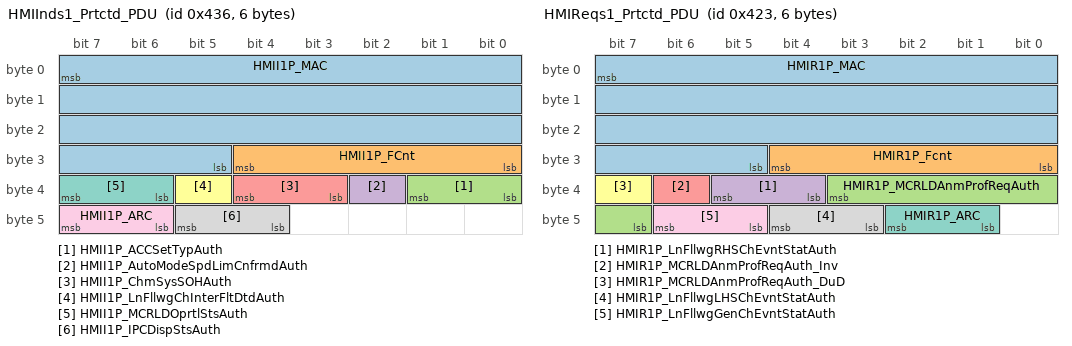
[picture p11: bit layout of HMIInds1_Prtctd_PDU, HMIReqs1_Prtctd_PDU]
BO_ 1078 HMIInds1_Prtctd_PDU: 6 IPC
 SG_ HMII1P_MAC : 7|27@0+ (1,0) [0|1.34218e+008] "" Vector__XXX
 SG_ HMII1P_FCnt : 28|5@0+ (1,0) [0|31] "" Vector__XXX
 SG_ HMII1P_ACCSetTypAuth : 33|2@0+ (1,0) [0|1] "" CSM,TCP
 SG_ HMII1P_AutoModeSpdLimCnfrmdAuth : 34|1@0+ (1,0) [0|1] "" CSM
 SG_ HMII1P_ChmSysSOHAuth : 36|2@0+ (1,0) [0|2] "" Vector__XXX
 SG_ HMII1P_LnFllwgChInterFltDtdAuth : 37|1@0+ (1,0) [0|1] "" Vector__XXX
 SG_ HMII1P_MCRLDOprtlStsAuth : 39|2@0+ (1,0) [0|2] "" Vector__XXX
 SG_ HMII1P_IPCDispStsAuth : 45|2@0+ (1,0) [0|2] "" Vector__XXX
 SG_ HMII1P_ARC : 47|2@0+ (1,0) [0|3] "" Vector__XXX

BO_ 1064 HMIReqs1_PCSM_PDU: 8 CGM
 SG_ HMIReqs1_PCSM : 0|64@1+ (1,0) [0|1.84467e+019] "" IPC

BO_ 1059 HMIReqs1_Prtctd_PDU: 6 CGM
 SG_ HMIR1P_MAC : 7|27@0+ (1,0) [0|1.34218e+008] "" IPC
 SG_ HMIR1P_Fcnt : 28|5@0+ (1,0) [0|31] "" IPC
 SG_ HMIR1P_MCRLDAnmProfReqAuth : 35|5@0+ (1,0) [0|31] "" IPC
 SG_ HMIR1P_LnFllwgRHSChEvntStatAuth : 37|2@0+ (1,0) [0|2] "" AMP,CSM,IPC
 SG_ HMIR1P_MCRLDAnmProfReqAuth_Inv : 38|1@0+ (1,0) [0|1] "" IPC
 SG_ HMIR1P_MCRLDAnmProfReqAuth_DuD : 39|1@0+ (1,0) [0|1] "" IPC
 SG_ HMIR1P_ARC : 42|2@0+ (1,0) [0|3] "" IPC
 SG_ HMIR1P_LnFllwgLHSChEvntStatAuth : 44|2@0+ (1,0) [0|2] "" AMP,CSM,IPC
 SG_ HMIR1P_LnFllwgGenChEvntStatAuth : 46|2@0+ (1,0) [0|2] "" AMP,CSM,IPC

BO_ 1364 HVACFrtCtlReqBlwLvlFrt_PDU: 8 HVAC_FP_F
 SG_ HVACFCRBLF_RwVltg : 2|9@0+ (0.01,0) [0|5.11] "Volts" Vector__XXX
 SG_ HVACFCRBLF_LvlActv : 3|1@0+ (1,0) [0|1] "" Vector__XXX
 SG_ HVACFCRBLF_Lvl : 7|4@0+ (1,0) [0|15] "Counts" Vector__XXX
 SG_ HVACFCRBLF_CS : 50|11@0+ (1,0) [0|2047] "" Vector__XXX
 SG_ HVACFCRBLF_ARC : 55|2@0+ (1,0) [0|3] "Counts" Vector__XXX

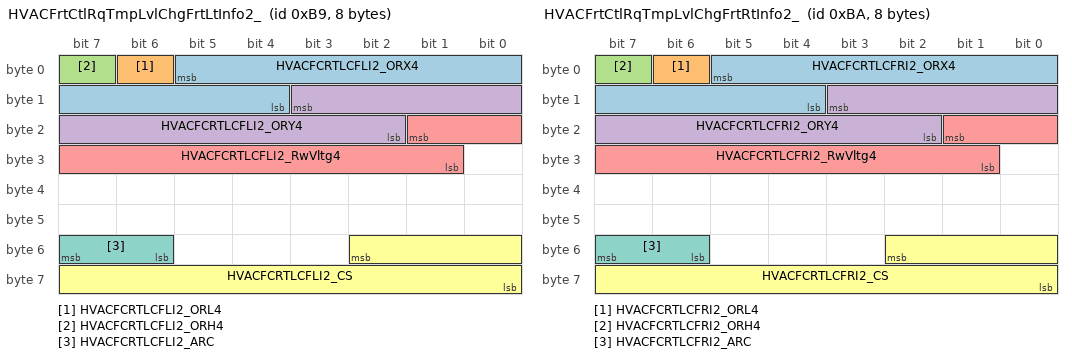
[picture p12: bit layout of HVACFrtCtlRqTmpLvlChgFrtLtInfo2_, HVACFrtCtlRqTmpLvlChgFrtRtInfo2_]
BO_ 185 HVACFrtCtlRqTmpLvlChgFrtLtInfo2_: 8 HVAC_FP_F
 SG_ HVACFCRTLCFLI2_ORX4 : 5|10@0+ (1,0) [0|1023] "Counts" Vector__XXX
 SG_ HVACFCRTLCFLI2_ORL4 : 6|1@0+ (1,0) [0|1] "" Vector__XXX
 SG_ HVACFCRTLCFLI2_ORH4 : 7|1@0+ (1,0) [0|1] "" Vector__XXX
 SG_ HVACFCRTLCFLI2_ORY4 : 11|10@0+ (1,0) [0|1023] "Counts" Vector__XXX
 SG_ HVACFCRTLCFLI2_RwVltg4 : 17|9@0+ (0.01,0) [0|5.11] "Volts" Vector__XXX
 SG_ HVACFCRTLCFLI2_CS : 50|11@0+ (1,0) [0|2047] "" Vector__XXX
 SG_ HVACFCRTLCFLI2_ARC : 55|2@0+ (1,0) [0|3] "" Vector__XXX

BO_ 186 HVACFrtCtlRqTmpLvlChgFrtRtInfo2_: 8 HVAC_FP_F
 SG_ HVACFCRTLCFRI2_ORX4 : 5|10@0+ (1,0) [0|1023] "Counts" Vector__XXX
 SG_ HVACFCRTLCFRI2_ORL4 : 6|1@0+ (1,0) [0|1] "" Vector__XXX
 SG_ HVACFCRTLCFRI2_ORH4 : 7|1@0+ (1,0) [0|1] "" Vector__XXX
 SG_ HVACFCRTLCFRI2_ORY4 : 11|10@0+ (1,0) [0|1023] "Counts" Vector__XXX
 SG_ HVACFCRTLCFRI2_RwVltg4 : 17|9@0+ (0.01,0) [0|5.11] "Volts" Vector__XXX
 SG_ HVACFCRTLCFRI2_CS : 50|11@0+ (1,0) [0|2047] "" Vector__XXX
 SG_ HVACFCRTLCFRI2_ARC : 55|2@0+ (1,0) [0|3] "" Vector__XXX

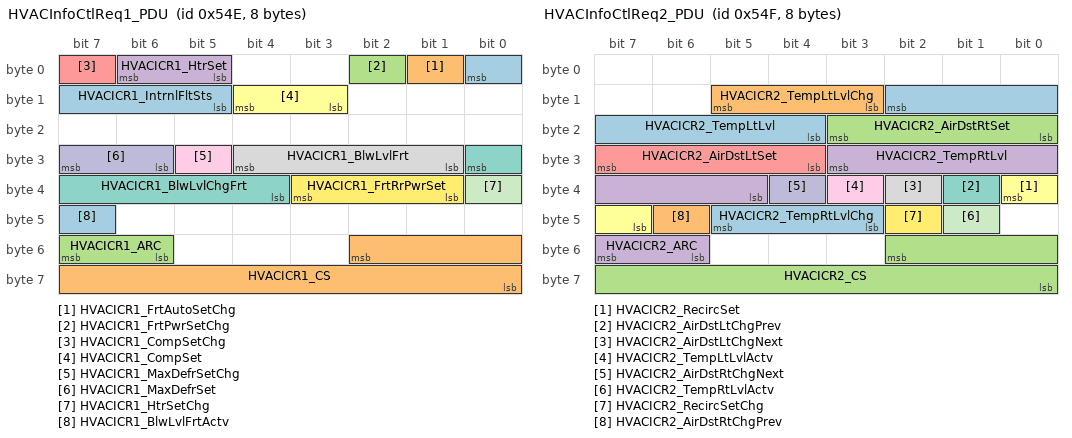
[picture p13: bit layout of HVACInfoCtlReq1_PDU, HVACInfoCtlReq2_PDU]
BO_ 1358 HVACInfoCtlReq1_PDU: 8 CSM
 SG_ HVACICR1_IntrnlFltSts : 0|4@0+ (1,0) [0|15] "" Vector__XXX
 SG_ HVACICR1_FrtAutoSetChg : 1|1@0+ (1,0) [0|1] "" Vector__XXX
 SG_ HVACICR1_FrtPwrSetChg : 2|1@0+ (1,0) [0|1] "" Vector__XXX
 SG_ HVACICR1_HtrSet : 6|2@0+ (1,0) [0|2] "" Vector__XXX
 SG_ HVACICR1_CompSetChg : 7|1@0+ (1,0) [0|1] "" Vector__XXX
 SG_ HVACICR1_CompSet : 12|2@0+ (1,0) [0|3] "" Vector__XXX
 SG_ HVACICR1_BlwLvlChgFrt : 24|5@0- (1,0) [-16|15] "Counts" Vector__XXX
 SG_ HVACICR1_BlwLvlFrt : 28|4@0+ (1,0) [0|15] "Counts" Vector__XXX
 SG_ HVACICR1_MaxDefrSetChg : 29|1@0+ (1,0) [0|1] "" Vector__XXX
 SG_ HVACICR1_MaxDefrSet : 31|2@0+ (1,0) [0|2] "" Vector__XXX
 SG_ HVACICR1_HtrSetChg : 32|1@0+ (1,0) [0|1] "" Vector__XXX
 SG_ HVACICR1_FrtRrPwrSet : 35|3@0+ (1,0) [0|4] "" Vector__XXX
 SG_ HVACICR1_BlwLvlFrtActv : 47|1@0+ (1,0) [0|1] "" Vector__XXX
 SG_ HVACICR1_CS : 50|11@0+ (1,0) [0|2047] "" Vector__XXX
 SG_ HVACICR1_ARC : 55|2@0+ (1,0) [0|3] "" Vector__XXX

BO_ 1359 HVACInfoCtlReq2_PDU: 8 CSM
 SG_ HVACICR2_TempLtLvl : 10|7@0+ (1,-16) [-16|111] "Counts" Vector__XXX
 SG_ HVACICR2_TempLtLvlChg : 13|3@0- (1,0) [-4|3] "Counts" Vector__XXX
 SG_ HVACICR2_AirDstRtSet : 19|4@0+ (1,0) [0|8] "" Vector__XXX
 SG_ HVACICR2_TempRtLvl : 27|7@0+ (1,-16) [-16|111] "Counts" Vector__XXX
 SG_ HVACICR2_AirDstLtSet : 31|4@0+ (1,0) [0|8] "" Vector__XXX
 SG_ HVACICR2_RecircSet : 32|2@0+ (1,0) [0|2] "" Vector__XXX
 SG_ HVACICR2_AirDstLtChgPrev : 33|1@0+ (1,0) [0|1] "" Vector__XXX
 SG_ HVACICR2_AirDstLtChgNext : 34|1@0+ (1,0) [0|1] "" Vector__XXX
 SG_ HVACICR2_TempLtLvlActv : 35|1@0+ (1,0) [0|1] "" Vector__XXX
 SG_ HVACICR2_AirDstRtChgNext : 36|1@0+ (1,0) [0|1] "" Vector__XXX
 SG_ HVACICR2_TempRtLvlActv : 41|1@0+ (1,0) [0|1] "" Vector__XXX
 SG_ HVACICR2_RecircSetChg : 42|1@0+ (1,0) [0|1] "" Vector__XXX
 SG_ HVACICR2_TempRtLvlChg : 45|3@0- (1,0) [-4|3] "Counts" Vector__XXX
 SG_ HVACICR2_AirDstRtChgPrev : 46|1@0+ (1,0) [0|1] "" Vector__XXX
 SG_ HVACICR2_CS : 50|11@0+ (1,0) [0|2047] "" Vector__XXX
 SG_ HVACICR2_ARC : 55|2@0+ (1,0) [0|3] "" Vector__XXX

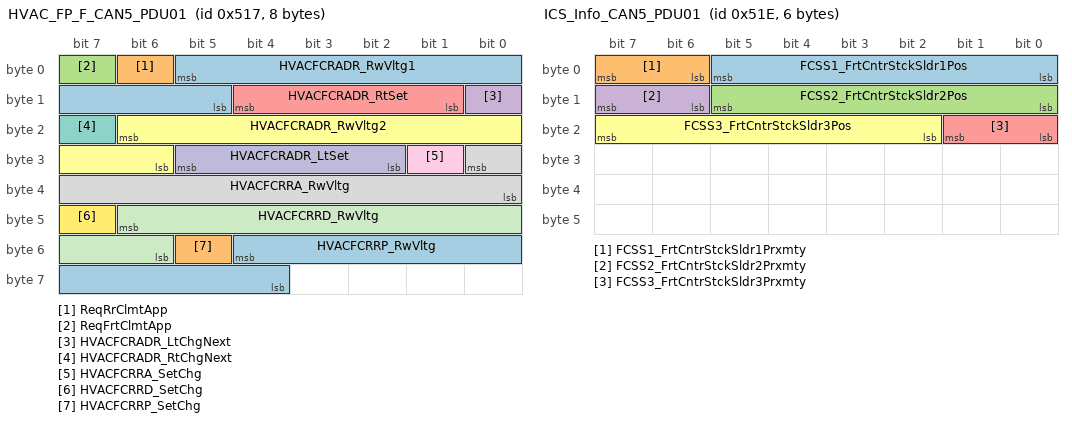
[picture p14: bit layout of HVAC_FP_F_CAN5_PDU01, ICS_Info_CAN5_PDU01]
BO_ 1303 HVAC_FP_F_CAN5_PDU01: 8 HVAC_FP_F
 SG_ HVACFCRADR_RwVltg1 : 5|9@0+ (0.01,0) [0|5.11] "Volts" CGM
 SG_ ReqRrClmtApp : 6|1@0+ (1,0) [0|1] "" CSM,RadioLow
 SG_ ReqFrtClmtApp : 7|1@0+ (1,0) [0|1] "" CSM,RadioLow
 SG_ HVACFCRADR_LtChgNext : 8|1@0+ (1,0) [0|1] "" CGM
 SG_ HVACFCRADR_RtSet : 12|4@0+ (1,0) [0|8] "" CGM
 SG_ HVACFCRADR_RwVltg2 : 22|9@0+ (0.01,0) [0|5.11] "Volts" CGM
 SG_ HVACFCRADR_RtChgNext : 23|1@0+ (1,0) [0|1] "" CGM
 SG_ HVACFCRRA_RwVltg : 24|9@0+ (0.01,0) [0|5.11] "Volts" CGM
 SG_ HVACFCRRA_SetChg : 25|1@0+ (1,0) [0|1] "" CGM
 SG_ HVACFCRADR_LtSet : 29|4@0+ (1,0) [0|8] "" CGM
 SG_ HVACFCRRD_RwVltg : 46|9@0+ (0.01,0) [0|5.11] "Volts" CGM
 SG_ HVACFCRRD_SetChg : 47|1@0+ (1,0) [0|1] "" CGM
 SG_ HVACFCRRP_RwVltg : 52|9@0+ (0.01,0) [0|5.11] "Volts" CGM
 SG_ HVACFCRRP_SetChg : 53|1@0+ (1,0) [0|1] "" CGM

BO_ 1354 HVAC_FP_F_CAN5_PDU02: 6 HVAC_FP_F
 SG_ HVACFCRSA_RwVltg : 7|9@0+ (0.01,0) [0|5.11] "Volts" CGM
 SG_ HVACFCRSA_SetChg : 14|1@0+ (1,0) [0|1] "" CGM

BO_ 1352 HVAC_FP_F_CAN5_PDU03: 6 HVAC_FP_F
 SG_ HtdStrgWhlSwActv_HVAC_FP_F : 3|1@0+ (1,0) [0|1] "" CGM
 SG_ ManHtdStrgWhlReqd_HVAC_FP_F : 4|1@0+ (1,0) [0|1] "" CGM
 SG_ ManHtdStrgWhlReqd_HVAC_FP_F_Inv : 5|1@0+ (1,0) [0|1] "" CGM
 SG_ HtdStrgWhlStkSw_HVAC_FP_F : 6|1@0+ (1,0) [0|1] "" CGM
 SG_ HtdStrgWhlStkSw_HVAC_FP_F_Inv : 7|1@0+ (1,0) [0|1] "" CGM

BO_ 1397 HVAC_FP_R_CAN5_PDU01: 6 HVAC_FP_R
 SG_ RHVSRR_HtdBckLvlChgUp : 0|1@0+ (1,0) [0|1] "" CGM
 SG_ RHVSRR_HtdBckLvlChgDn : 1|1@0+ (1,0) [0|1] "" CGM
 SG_ RHVSLR_VntLvlChgUp : 2|1@0+ (1,0) [0|1] "" CGM
 SG_ RHVSLR_VntLvlChgDn : 3|1@0+ (1,0) [0|1] "" CGM
 SG_ RHVSLR_HtdCushBckLvlChgUp : 4|1@0+ (1,0) [0|1] "" CGM
 SG_ RHVSLR_HtdCushBckLvlChgDn : 5|1@0+ (1,0) [0|1] "" CGM
 SG_ RHVSLR_HtdBckLvlChgUp : 6|1@0+ (1,0) [0|1] "" CGM
 SG_ RHVSLR_HtdBckLvlChgDn : 7|1@0+ (1,0) [0|1] "" CGM
 SG_ HtdStBckStckSwRR : 8|1@0+ (1,0) [0|1] "" CGM
 SG_ HtdStBckStckSwLR : 9|1@0+ (1,0) [0|1] "" CGM
 SG_ HtdStBckCushStckSwRR : 10|1@0+ (1,0) [0|1] "" CGM
 SG_ HtdStBckCushStckSwLR : 11|1@0+ (1,0) [0|1] "" CGM
 SG_ RHVSRR_VntLvlChgUp : 12|1@0+ (1,0) [0|1] "" CGM
 SG_ RHVSRR_VntLvlChgDn : 13|1@0+ (1,0) [0|1] "" CGM
 SG_ RHVSRR_HtdCushBckLvlChgUp : 14|1@0+ (1,0) [0|1] "" CGM
 SG_ RHVSRR_HtdCushBckLvlChgDn : 15|1@0+ (1,0) [0|1] "" CGM
 SG_ VntStStckSwRR : 20|1@0+ (1,0) [0|1] "" CGM
 SG_ VntStStckSwLR : 21|1@0+ (1,0) [0|1] "" CGM
 SG_ HtdVntStSwActvRR : 22|1@0+ (1,0) [0|1] "" CGM
 SG_ HtdVntStSwActvLR : 23|1@0+ (1,0) [0|1] "" CGM

BO_ 1310 ICS_Info_CAN5_PDU01: 6 ICS_Info
 SG_ FCSS1_FrtCntrStckSldr1Pos : 5|6@0+ (1.5873,0) [0|99.9999] "%" CSM,TCP
 SG_ FCSS1_FrtCntrStckSldr1Prxmty : 7|2@0+ (1,0) [0|3] "" CSM,TCP
 SG_ FCSS2_FrtCntrStckSldr2Pos : 13|6@0+ (1.5873,0) [0|99.9999] "%" CSM,TCP
 SG_ FCSS2_FrtCntrStckSldr2Prxmty : 15|2@0+ (1,0) [0|3] "" CSM,TCP
 SG_ FCSS3_FrtCntrStckSldr3Prxmty : 17|2@0+ (1,0) [0|3] "" CSM,TCP
 SG_ FCSS3_FrtCntrStckSldr3Pos : 23|6@0+ (1.5873,0) [0|99.9999] "%" CSM,TCP

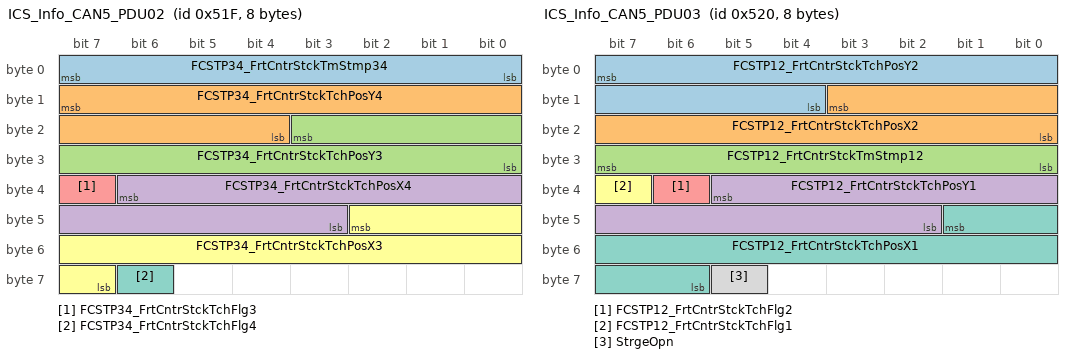
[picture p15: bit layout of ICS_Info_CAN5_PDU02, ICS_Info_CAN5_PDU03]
BO_ 1311 ICS_Info_CAN5_PDU02: 8 ICS_Info
 SG_ FCSTP34_FrtCntrStckTmStmp34 : 7|8@0+ (1,0) [0|255] "msec" CSM,PDR,TCP
 SG_ FCSTP34_FrtCntrStckTchPosY4 : 15|12@0+ (0.0244141,0) [0|99.9756] "%" CSM,PDR,TCP
 SG_ FCSTP34_FrtCntrStckTchPosY3 : 19|12@0+ (0.0244141,0) [0|99.9756] "%" CSM,PDR,TCP
 SG_ FCSTP34_FrtCntrStckTchPosX4 : 38|12@0+ (0.0244141,0) [0|99.9756] "%" CSM,PDR,TCP
 SG_ FCSTP34_FrtCntrStckTchFlg3 : 39|1@0+ (1,0) [0|1] "" CSM,PDR,TCP
 SG_ FCSTP34_FrtCntrStckTchPosX3 : 42|12@0+ (0.0244141,0) [0|99.9756] "%" CSM,PDR,TCP
 SG_ FCSTP34_FrtCntrStckTchFlg4 : 62|1@0+ (1,0) [0|1] "" CSM,PDR,TCP

BO_ 1312 ICS_Info_CAN5_PDU03: 8 ICS_Info
 SG_ FCSTP12_FrtCntrStckTchPosY2 : 7|12@0+ (0.0244141,0) [0|99.9756] "%" CSM,PDR,TCP
 SG_ FCSTP12_FrtCntrStckTchPosX2 : 11|12@0+ (0.0244141,0) [0|99.9756] "%" CSM,PDR,TCP
 SG_ FCSTP12_FrtCntrStckTmStmp12 : 31|8@0+ (1,0) [0|255] "msec" CSM,PDR,TCP
 SG_ FCSTP12_FrtCntrStckTchPosY1 : 37|12@0+ (0.0244141,0) [0|99.9756] "%" CSM,PDR,TCP
 SG_ FCSTP12_FrtCntrStckTchFlg2 : 38|1@0+ (1,0) [0|1] "" CSM,PDR,TCP
 SG_ FCSTP12_FrtCntrStckTchFlg1 : 39|1@0+ (1,0) [0|1] "" CSM,PDR,TCP
 SG_ FCSTP12_FrtCntrStckTchPosX1 : 41|12@0+ (0.0244141,0) [0|99.9756] "%" CSM,PDR,TCP
 SG_ StrgeOpn : 61|1@0+ (1,0) [0|1] "" CSM,RadioLow

BO_ 1313 ICS_Info_CAN5_PDU04: 6 ICS_Info
 SG_ FrtCntrStckPriVidInLckd : 6|1@0+ (1,0) [0|1] "" CSM,PDR,TCP
 SG_ FrtCntrStckLVMVidInLckd : 7|1@0+ (1,0) [0|1] "" CSM,PDR,TCP

BO_ 358 ICS_Info_NM_PDU_On_CAN_5_Cluster: 8 ICS_Info
 SG_ ISignal_ICS_Info_CAN_5_Cluster : 23|48@0+ (1,0) [0|281474976710655] "" AGC,AMP,CGM,CSM,HUD_CAN,HVAC_FP_F,HVAC_FP_R,IPC,PDR,MFC,RSC,RadioLow,TCP,VKM,WCM

BO_ 1418 IPC_CAN5_PDU01: 6 IPC
 SG_ SD88_PV : 4|2@0+ (1,0) [0|3] "" CGM
 SG_ SD88_ARC : 6|2@0+ (1,0) [0|3] "" CGM
 SG_ PwrtrnExhPrtclFiltManRegnReq : 7|1@0+ (1,0) [0|1] "" CGM

BO_ 1316 IPC_CAN5_PDU02: 6 IPC
 SG_ VehFlRngCalc : 6|17@0+ (0.015625,0) [0|2047.98] "" CSM,RadioLow,TCP,VKM
 SG_ VehFlRngCalc_Inv : 7|1@0+ (1,0) [0|1] "" CSM,RadioLow,TCP,VKM
 SG_ FuelEconShrtTrmAvg : 20|8@0+ (0.1,0) [0|25.5] "km/L" CGM
 SG_ FuelLvlLoIndOn : 21|1@0+ (1,0) [0|1] "" CGM,CSM,RadioLow,VKM
 SG_ PTExPrtclFltrMnlRgnDispPrsnt : 28|1@0+ (1,0) [0|1] "" CGM

BO_ 1317 IPC_CAN5_PDU03: 8 IPC
 SG_ FllwgDstIndTmDstSel : 56|1@0+ (1,0) [0|1] "" TCP

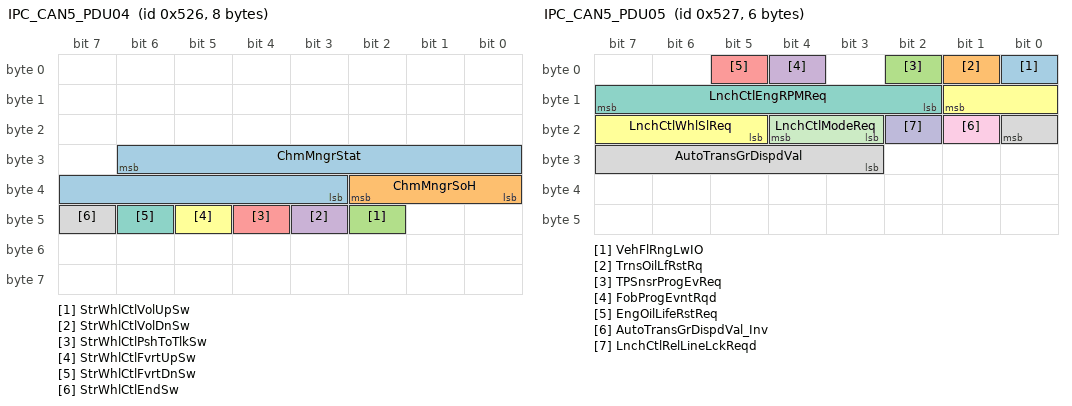
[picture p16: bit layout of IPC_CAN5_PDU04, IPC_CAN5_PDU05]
BO_ 1318 IPC_CAN5_PDU04: 8 IPC
 SG_ ChmMngrStat : 30|12@0+ (1,0) [0|4095] "" CGM,CSM
 SG_ ChmMngrSoH : 34|3@0+ (1,0) [0|7] "" CSM,RadioLow
 SG_ StrWhlCtlVolUpSw : 42|1@0+ (1,0) [0|1] "" CGM,CSM,RadioLow
 SG_ StrWhlCtlVolDnSw : 43|1@0+ (1,0) [0|1] "" CGM,CSM,RadioLow
 SG_ StrWhlCtlPshToTlkSw : 44|1@0+ (1,0) [0|1] "" CGM,CSM,RadioLow
 SG_ StrWhlCtlFvrtUpSw : 45|1@0+ (1,0) [0|1] "" CGM,CSM,RadioLow
 SG_ StrWhlCtlFvrtDnSw : 46|1@0+ (1,0) [0|1] "" CGM,CSM,RadioLow
 SG_ StrWhlCtlEndSw : 47|1@0+ (1,0) [0|1] "" CGM,CSM,RadioLow

BO_ 1319 IPC_CAN5_PDU05: 6 IPC
 SG_ VehFlRngLwIO : 0|1@0+ (1,0) [0|1] "" CSM,RadioLow,VKM
 SG_ TrnsOilLfRstRq : 1|1@0+ (1,0) [0|1] "" CGM
 SG_ TPSnsrProgEvReq : 2|1@0+ (1,0) [0|1] "" CGM
 SG_ FobProgEvntRqd : 4|1@0+ (1,0) [0|1] "" CGM
 SG_ EngOilLifeRstReq : 5|1@0+ (1,0) [0|1] "" CGM
 SG_ LnchCtlWhlSlReq : 9|5@0+ (1,0) [0|21] "" CGM
 SG_ LnchCtlEngRPMReq : 15|6@0+ (1,0) [0|38] "" CGM
 SG_ AutoTransGrDispdVal : 16|6@0+ (1,0) [0|61] "" CSM
 SG_ AutoTransGrDispdVal_Inv : 17|1@0+ (1,0) [0|1] "" CSM
 SG_ LnchCtlRelLineLckReqd : 18|1@0+ (1,0) [0|1] "" CGM
 SG_ LnchCtlModeReq : 20|2@0+ (1,0) [0|3] "" CGM

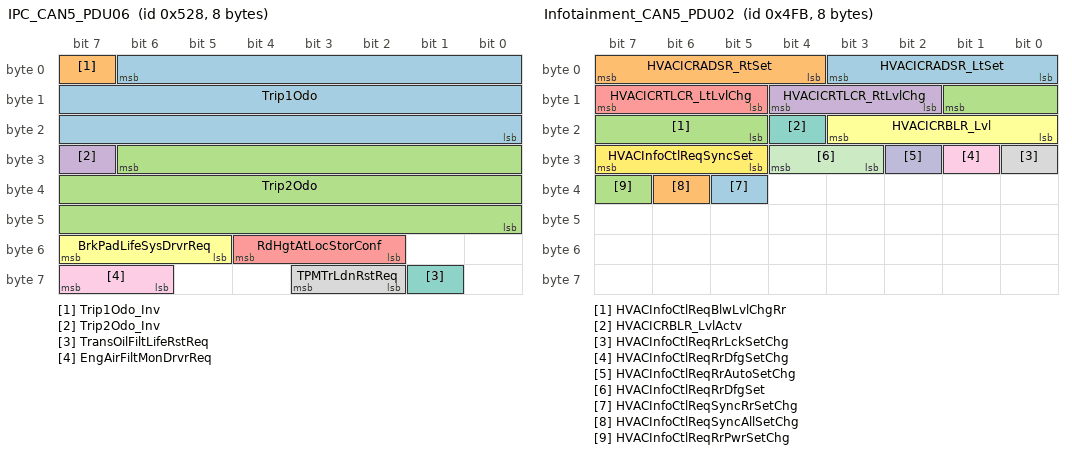
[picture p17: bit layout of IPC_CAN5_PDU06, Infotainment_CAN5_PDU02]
BO_ 1320 IPC_CAN5_PDU06: 8 IPC
 SG_ Trip1Odo : 6|23@0+ (0.015625,0) [0|131072] "Km" CSM,TCP,VKM
 SG_ Trip1Odo_Inv : 7|1@0+ (1,0) [0|1] "" CSM,VKM
 SG_ Trip2Odo : 30|23@0+ (0.015625,0) [0|131072] "km" CSM,TCP,VKM
 SG_ Trip2Odo_Inv : 31|1@0+ (1,0) [0|1] "" CSM,VKM
 SG_ RdHgtAtLocStorConf : 52|3@0+ (1,0) [0|4] "" CGM
 SG_ BrkPadLifeSysDrvrReq : 55|3@0+ (1,0) [0|4] "" CGM
 SG_ TransOilFiltLifeRstReq : 57|1@0+ (1,0) [0|1] "" CGM
 SG_ TPMTrLdnRstReq : 59|2@0+ (1,0) [0|3] "" CGM
 SG_ EngAirFiltMonDrvrReq : 63|2@0+ (1,0) [0|3] "" CGM

BO_ 1321 IPC_CAN5_PDU07: 6 IPC
 SG_ IPC_RunCrnkInpActv_Inv : 0|1@0+ (1,0) [0|1] "" CSM,RadioLow
 SG_ HUD_RclCmpt : 2|2@0+ (1,0) [0|2] "" CGM
 SG_ DispMeasSysExtnd : 4|2@0+ (1,0) [0|3] "" CGM,CSM,PDR,RadioLow,TCP,VKM
 SG_ ClstrAnmStat : 7|3@0+ (1,0) [0|4] "" CSM,RadioLow
 SG_ DispMeasSys : 8|1@0+ (1,0) [0|1] "" CGM,CSM,PDR,RadioLow
 SG_ ClstrHMI_Rdy : 9|1@0+ (1,0) [0|1] "" CSM,RadioLow
 SG_ APARghtSftBtnStatIPC : 10|1@0+ (1,0) [0|1] "" CGM
 SG_ APALftSftBtnStatIPC : 11|1@0+ (1,0) [0|1] "" CGM
 SG_ APAFcStatIPC : 12|1@0+ (1,0) [0|1] "" CGM
 SG_ IPC_RunCrnkInpActv : 15|1@0+ (1,0) [0|1] "" CSM,RadioLow,TCP
 SG_ PAMutDrvrReq : 16|2@0+ (1,0) [0|2] "" CGM
 SG_ HUD_CustSelActvStat_Inv : 17|1@0+ (1,0) [0|1] "" CGM
 SG_ TSMWrngPopUpSts : 18|1@0+ (1,0) [0|1] "" CGM
 SG_ TSMSgnNtfnWrnDispd : 19|1@0+ (1,0) [0|1] "" CGM
 SG_ TSMPageDispActv : 20|1@0+ (1,0) [0|1] "" CGM
 SG_ TSMCustRstReq : 21|1@0+ (1,0) [0|1] "" CGM
 SG_ StkHUD_CustSelStat : 22|1@0+ (1,0) [0|1] "" CGM
 SG_ HUD_CustSelActvStat : 23|1@0+ (1,0) [0|1] "" CGM
 SG_ StrgWhlCtlInCarVcCommCtlSw : 25|1@0+ (1,0) [0|1] "" CGM,CSM,RadioLow
 SG_ NtVsnVidCntrstUserReq : 27|2@0+ (1,0) [0|3] "" CGM
 SG_ NtVsnVidBrghtnsUserReq : 29|2@0+ (1,0) [0|3] "" CGM
 SG_ FuelFiltLifeRstReqd : 30|1@0+ (1,0) [0|1] "" CGM,TCP

BO_ 613 IPC_CAN5_PDU08: 6 IPC
 SG_ JmpStrtReqd : 7|1@0+ (1,0) [0|1] "" CGM

BO_ 352 IPC_NM_PDU_On_CAN_5_Cluster: 8 IPC
 SG_ ISignal_IPC_CAN_5_Cluster : 23|48@0+ (1,0) [0|281474976710655] "" AGC,AMP,CGM,CSM,HUD_CAN,HVAC_FP_F,HVAC_FP_R,ICS_Info,PDR,MFC,RSC,RadioLow,TCP,VKM,WCM

BO_ 1273 Infotainment_CAN5_PDU01: 6 CSM
 SG_ CldrDay : 0|5@0+ (1,0) [0|31] "day" CGM,ICS_Info,IPC,PDR
 SG_ BklghtngCnfg : 11|2@0+ (1,0) [0|2] "" MFC

BO_ 1275 Infotainment_CAN5_PDU02: 8 CSM
 SG_ HVACICRADSR_LtSet : 3|4@0+ (1,0) [0|8] "" CGM
 SG_ HVACICRADSR_RtSet : 7|4@0+ (1,0) [0|8] "" CGM
 SG_ HVACInfoCtlReqBlwLvlChgRr : 9|5@0- (1,0) [-16|15] "" CGM
 SG_ HVACICRTLCR_RtLvlChg : 12|3@0- (1,0) [-4|3] "" CGM
 SG_ HVACICRTLCR_LtLvlChg : 15|3@0- (1,0) [-4|3] "" CGM
 SG_ HVACICRBLR_Lvl : 19|4@0+ (1,0) [0|15] "" CGM
 SG_ HVACICRBLR_LvlActv : 20|1@0+ (1,0) [0|1] "" CGM
 SG_ HVACInfoCtlReqRrLckSetChg : 24|1@0+ (1,0) [0|1] "" CGM
 SG_ HVACInfoCtlReqRrDfgSetChg : 25|1@0+ (1,0) [0|1] "" CGM
 SG_ HVACInfoCtlReqRrAutoSetChg : 26|1@0+ (1,0) [0|1] "" CGM
 SG_ HVACInfoCtlReqRrDfgSet : 28|2@0+ (1,0) [0|2] "" CGM
 SG_ HVACInfoCtlReqSyncSet : 31|3@0+ (1,0) [0|4] "" CGM
 SG_ HVACInfoCtlReqSyncRrSetChg : 37|1@0+ (1,0) [0|1] "" CGM
 SG_ HVACInfoCtlReqSyncAllSetChg : 38|1@0+ (1,0) [0|1] "" CGM
 SG_ HVACInfoCtlReqRrPwrSetChg : 39|1@0+ (1,0) [0|1] "" CGM

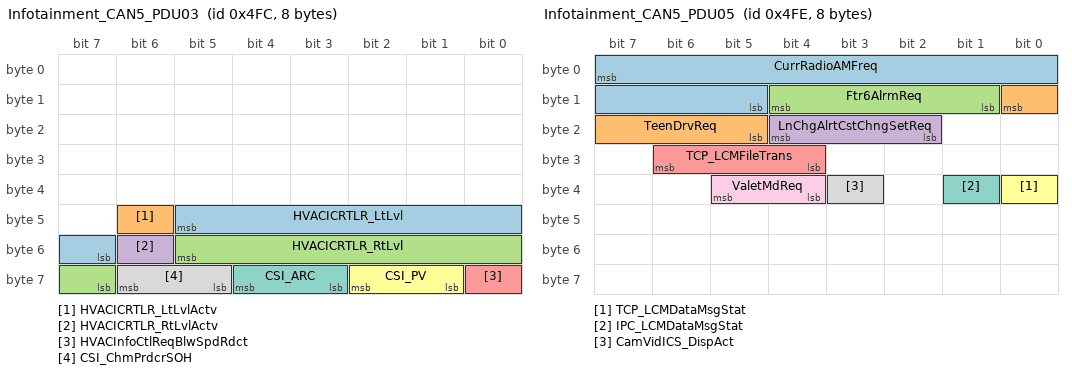
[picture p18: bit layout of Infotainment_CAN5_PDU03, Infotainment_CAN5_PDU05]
BO_ 1276 Infotainment_CAN5_PDU03: 8 CSM
 SG_ HVACICRTLR_LtLvl : 45|7@0+ (1,-16) [-16|111] "" CGM
 SG_ HVACICRTLR_LtLvlActv : 46|1@0+ (1,0) [0|1] "" CGM
 SG_ HVACICRTLR_RtLvl : 53|7@0+ (1,-16) [-16|111] "" CGM
 SG_ HVACICRTLR_RtLvlActv : 54|1@0+ (1,0) [0|1] "" CGM
 SG_ HVACInfoCtlReqBlwSpdRdct : 56|1@0+ (1,0) [0|1] "" CGM
 SG_ CSI_PV : 58|2@0+ (1,0) [0|3] "" IPC
 SG_ CSI_ARC : 60|2@0+ (1,0) [0|3] "" IPC
 SG_ CSI_ChmPrdcrSOH : 62|2@0+ (1,0) [0|2] "" IPC

BO_ 1277 Infotainment_CAN5_PDU04: 8 CSM
 SG_ ChmPrdcrStat : 53|12@0+ (1,0) [0|4095] "msec" AMP,IPC
 SG_ HVACICRADSCR_LtChgNext : 56|1@0+ (1,0) [0|1] "" CGM
 SG_ HVACICRADSCR_RtChgNext : 57|1@0+ (1,0) [0|1] "" CGM

BO_ 1278 Infotainment_CAN5_PDU05: 8 CSM
 SG_ CurrRadioAMFreq : 7|11@0+ (1,0) [0|2047] "KHz" CGM
 SG_ TeenDrvReq : 8|4@0+ (1,0) [0|8] "" CGM,TCP
 SG_ Ftr6AlrmReq : 12|4@0+ (1,0) [0|2] "" CGM
 SG_ LnChgAlrtCstChngSetReq : 20|3@0+ (1,0) [0|7] "" CGM
 SG_ TCP_LCMFileTrans : 30|3@0+ (1,0) [0|4] "" TCP
 SG_ TCP_LCMDataMsgStat : 32|1@0+ (1,0) [0|1] "" TCP
 SG_ IPC_LCMDataMsgStat : 33|1@0+ (1,0) [0|1] "" IPC
 SG_ CamVidICS_DispAct : 35|1@0+ (1,0) [0|1] "" CGM
 SG_ ValetMdReq : 37|2@0+ (1,0) [0|2] "" CGM

BO_ 1279 Infotainment_CAN5_PDU06: 8 CSM
 SG_ Ftr6AlrmTm : 7|24@0+ (1,0) [0|1.67772e+007] "Sec" CGM
 SG_ TeenDrvPinCd : 31|16@0+ (1,0) [0|65535] "" CGM,TCP
 SG_ ValetPIN : 47|14@0+ (1,0) [0|16383] "" CGM
 SG_ LngSelExt : 49|7@0+ (1,0) [0|41] "" CGM,IPC,PDR,TCP
 SG_ IPC_LCMFileTrans : 58|3@0+ (1,0) [0|4] "" IPC

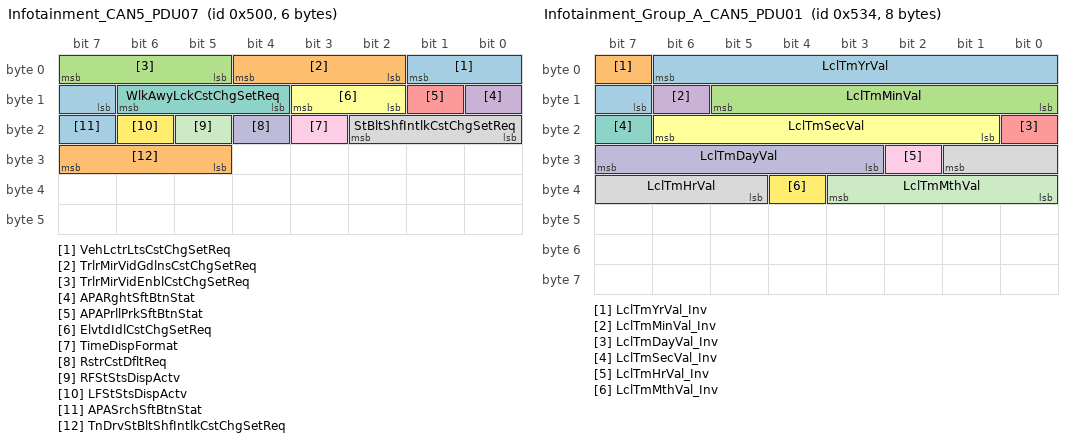
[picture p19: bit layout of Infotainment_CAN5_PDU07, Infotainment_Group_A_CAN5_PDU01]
BO_ 1280 Infotainment_CAN5_PDU07: 6 CSM
 SG_ VehLctrLtsCstChgSetReq : 1|3@0+ (1,0) [0|7] "" CGM
 SG_ TrlrMirVidGdlnsCstChgSetReq : 4|3@0+ (1,0) [0|2] "" CGM
 SG_ TrlrMirVidEnblCstChgSetReq : 7|3@0+ (1,0) [0|2] "" CGM
 SG_ APARghtSftBtnStat : 8|1@0+ (1,0) [0|1] "" CGM
 SG_ APAPrllPrkSftBtnStat : 9|1@0+ (1,0) [0|1] "" CGM
 SG_ ElvtdIdlCstChgSetReq : 11|2@0+ (1,0) [0|2] "" CGM
 SG_ WlkAwyLckCstChgSetReq : 14|3@0+ (1,0) [0|7] "" CGM
 SG_ StBltShfIntlkCstChgSetReq : 18|3@0+ (1,0) [0|7] "" CGM
 SG_ TimeDispFormat : 19|1@0+ (1,0) [0|1] "" CGM,ICS_Info,IPC,PDR
 SG_ RstrCstDfltReq : 20|1@0+ (1,0) [0|1] "" CGM,WCM
 SG_ RFStStsDispActv : 21|1@0+ (1,0) [0|1] "" CGM
 SG_ LFStStsDispActv : 22|1@0+ (1,0) [0|1] "" CGM
 SG_ APASrchSftBtnStat : 23|1@0+ (1,0) [0|1] "" CGM
 SG_ TnDrvStBltShfIntlkCstChgSetReq : 31|3@0+ (1,0) [0|7] "" CGM

BO_ 1281 Infotainment_CAN5_PDU08: 8 CSM
 SG_ RlkRtUlkDrCstChSetReq : 1|3@0+ (1,0) [0|7] "" CGM
 SG_ RevTltMrCstChgSetReq : 4|3@0+ (1,0) [0|7] "" CGM
 SG_ RemWndOpCstChgSetReq : 7|3@0+ (1,0) [0|7] "" CGM
 SG_ RnSnsCstChgSetReq : 8|3@0+ (1,0) [0|7] "" CGM
 SG_ RmtStrtHtdStCstChgSetReq : 11|3@0+ (1,0) [0|7] "" CGM
 SG_ RmtStrtCoolStCstChgSetReq : 14|3@0+ (1,0) [0|7] "" CGM
 SG_ RnngBrdManDplyCstChgSetReq : 18|3@0+ (1,0) [0|6] "" CGM
 SG_ RnngBrdAutoDplyCstChgSetReq : 21|3@0+ (1,0) [0|6] "" CGM
 SG_ RrPCMRspTypCstChgSetReq : 25|3@0+ (1,0) [0|7] "" CGM
 SG_ RrDfgStUpCstChgSetReq : 28|3@0+ (1,0) [0|7] "" CGM
 SG_ RrCrsTrfcAlrtCstChngSetReq : 31|3@0+ (1,0) [0|7] "" CGM
 SG_ RtLkFdbkCstChgSetReq : 32|3@0+ (1,0) [0|7] "" CGM
 SG_ RrVwPrkAstSymCstChgSetReq : 35|3@0+ (1,0) [0|7] "" CGM
 SG_ RrStRmndrEnblDsblCstChgSetReq : 38|3@0+ (1,0) [0|2] "" CGM
 SG_ SBZAlrtCstChngSetReq : 42|3@0+ (1,0) [0|7] "" CGM
 SG_ RtUlkLtFbCstChgSetReq : 45|3@0+ (1,0) [0|7] "" CGM
 SG_ StBltTghtngCstChgSetReq : 49|3@0+ (1,0) [0|7] "" CGM
 SG_ SrrndVwLghtCstChgSetReq : 52|3@0+ (1,0) [0|7] "" CGM
 SG_ SelUlkCstChgSetReq : 55|3@0+ (1,0) [0|7] "" CGM
 SG_ APALftSftBtnStat : 56|1@0+ (1,0) [0|1] "" CGM
 SG_ TrffcLgtAsstCstChgSetReq : 59|3@0+ (1,0) [0|7] "" CGM
 SG_ TnDrvSpdLmtCstChgStReq : 62|3@0+ (1,0) [0|7] "" CGM

BO_ 1282 Infotainment_CAN5_PDU09: 8 CSM
 SG_ LvlgSysAlgnMdCstChgSetReq : 1|3@0+ (1,0) [0|2] "" CGM
 SG_ LtRtHnTrCstChgSetReq : 4|3@0+ (1,0) [0|7] "" CGM
 SG_ LDCLCstChgSetReq : 7|3@0+ (1,0) [0|7] "" CGM
 SG_ OpDrAtLOCstChgSetReq : 8|3@0+ (1,0) [0|7] "" CGM
 SG_ LvlgSysServMdCstChgSetReq : 11|3@0+ (1,0) [0|2] "" CGM
 SG_ LvlgSysEntEgrsMdCstChgSetReq : 14|3@0+ (1,0) [0|2] "" CGM
 SG_ PlltnCtrlCstChgSetReq : 18|3@0+ (1,0) [0|7] "" CGM
 SG_ PhnLtInVehCstChgSetReq : 21|3@0+ (1,0) [0|7] "" WCM
 SG_ PrsnlMdActAeroCstChngSetReq : 25|3@0+ (1,0) [0|7] "" CGM
 SG_ PrkAsstTrHtchPsntCstChgSetReq : 28|3@0+ (1,0) [0|7] "" CGM
 SG_ PrkAsstOnOffCstChgSetReq : 31|3@0+ (1,0) [0|3] "" CGM
 SG_ PrsnlMdRideHghtCstChngSetReq : 32|3@0+ (1,0) [0|7] "" CGM
 SG_ PrsnlMdDrvlCstChngSetReq : 35|3@0+ (1,0) [0|7] "" CGM,TCP
 SG_ PrsnlMdBrkPdlCstChngSetReq : 38|3@0+ (1,0) [0|7] "" CGM
 SG_ PrsnlMdSpnCstChngSetReq : 42|3@0+ (1,0) [0|7] "" CGM,TCP
 SG_ PrsnlMdSndCstChngSetReq : 45|3@0+ (1,0) [0|7] "" CGM
 SG_ PsvUnlckCstChgSetReq : 52|3@0+ (1,0) [0|7] "" CGM
 SG_ PrsnlMdStrCstChngSetReq : 55|3@0+ (1,0) [0|7] "" CGM,TCP
 SG_ APAFcStatCSM : 56|1@0+ (1,0) [0|1] "" CGM
 SG_ RemLftVehRmCstChgSetReq : 59|3@0+ (1,0) [0|7] "" CGM
 SG_ RemInVehRmCstChgSetReq : 62|3@0+ (1,0) [0|7] "" CGM

BO_ 1283 Infotainment_CAN5_PDU10: 8 CSM
 SG_ CustMdDrvlCstChngSetReq : 4|3@0+ (1,0) [0|7] "" CGM,TCP
 SG_ CustMdSpnCstChngSetReq : 8|3@0+ (1,0) [0|7] "" CGM,TCP
 SG_ CustMdSndCstChngSetReq : 11|3@0+ (1,0) [0|7] "" CGM
 SG_ CustMdRideHghtCstChngSetReq : 14|3@0+ (1,0) [0|7] "" CGM
 SG_ CustMdStrCstChngSetReq : 21|3@0+ (1,0) [0|7] "" CGM,TCP
 SG_ EsyExtCstChgSetReq : 25|3@0+ (1,0) [0|7] "" CGM
 SG_ DrvrAlrtTypCstChgStReq : 28|3@0+ (1,0) [0|7] "" CGM
 SG_ DayTmTlLtsCstChgSetReq : 31|3@0+ (1,0) [0|7] "" CGM
 SG_ FrntPCMRspTypCstChgSetReq : 32|3@0+ (1,0) [0|7] "" CGM
 SG_ ExitLghtngCstChgSetReq : 38|3@0+ (1,0) [0|7] "" CGM
 SG_ FrwdImpMtgnOpSlctCstChgSetReq : 42|3@0+ (1,0) [0|7] "" CGM
 SG_ FrtRdHgtGPSCstChngSetReq : 45|3@0+ (1,0) [0|7] "" CGM
 SG_ HFRCCstChgSetReq : 49|3@0+ (1,0) [0|7] "" CGM
 SG_ GoNotfrCstChgSetReq : 52|3@0+ (1,0) [0|7] "" CGM
 SG_ GlrFrHgBmRspTypCstChgSetReq : 55|3@0+ (1,0) [0|7] "" CGM
 SG_ APAExtPrkSftBtnStat : 56|1@0+ (1,0) [0|1] "" CGM
 SG_ JckKnfDtnCstChgSetReq : 59|3@0+ (1,0) [0|2] "" CGM
 SG_ IonzrCtrlCstChgSetReq : 62|3@0+ (1,0) [0|7] "" CGM

BO_ 1284 Infotainment_CAN5_PDU11: 8 CSM
 SG_ TAC_AudConctOutcm : 3|4@0+ (1,0) [0|15] "" CGM,TCP
 SG_ TAC_AudChConctStat : 7|4@0+ (1,0) [0|15] "" CGM,TCP
 SG_ TDOSWCCSR_ChgSetReq : 8|3@0+ (1,0) [0|7] "" CGM
 SG_ TDOSWCCSR_DecSwAct : 9|1@0+ (1,0) [0|1] "" CGM
 SG_ TDOSWCCSR_IncSwAct : 10|1@0+ (1,0) [0|1] "" CGM
 SG_ InfoSysStat : 15|5@0+ (1,0) [0|17] "" AGC,AMP,HUD_CAN,HVAC_FP_F,HVAC_FP_R,ICS_Info,IPC,PDR,MFC,RSC,TCP,WCM
 SG_ AirQltySensCstChgSetReq : 18|3@0+ (1,0) [0|7] "" CGM
 SG_ AdpLghtRspTypCstChgSetReq : 21|3@0+ (1,0) [0|7] "" CGM
 SG_ AutoAirDstCstChgSetReq : 25|3@0+ (1,0) [0|7] "" CGM
 SG_ AutUnlckCstChgSetReq : 28|3@0+ (1,0) [0|7] "" CGM
 SG_ AutDrvLckCstChgSetReq : 31|3@0+ (1,0) [0|7] "" CGM
 SG_ AutoFanCstChgSetReq : 32|3@0+ (1,0) [0|7] "" CGM
 SG_ AutoDfgCstChgSetReq : 35|3@0+ (1,0) [0|7] "" CGM
 SG_ AutoCoolStCstChgSetReq : 38|3@0+ (1,0) [0|7] "" CGM
 SG_ AutoMemRclCstChgSetReq : 42|3@0+ (1,0) [0|7] "" CGM
 SG_ AutoHtdStCstChgSetReq : 45|3@0+ (1,0) [0|7] "" CGM
 SG_ ClstrDspAnmReq : 49|3@0+ (1,0) [0|4] "" IPC
 SG_ AutoRrWpCstChgSetReq : 52|3@0+ (1,0) [0|7] "" CGM
 SG_ AutoMrFldCstChgSetReq : 55|3@0+ (1,0) [0|7] "" CGM
 SG_ APACrssBckInSftBtnStat : 56|1@0+ (1,0) [0|1] "" CGM
 SG_ CrgBedVwAutoLgtCstChgSetReq : 62|3@0+ (1,0) [0|2] "" CGM

BO_ 615 Infotainment_CAN5_PDU12: 8 CSM
 SG_ InfoAuxBrightnessLvl : 7|16@0+ (0.001526,0) [0|100.006] "%" ICS_Info,MFC
 SG_ InfoBklghtBrightnessLvl : 23|16@0+ (0.001526,0) [0|100.006] "%" ICS_Info,MFC
 SG_ InfoDispBrightnessLvl : 39|16@0+ (0.001526,0) [0|100.006] "%" ICS_Info,MFC
 SG_ IntAmbBrghtnsCtrlSetReq : 55|3@0+ (1,0) [0|7] "" CGM

BO_ 1332 Infotainment_Group_A_CAN5_PDU01: 8 TCP
 SG_ LclTmYrVal : 6|8@0+ (1,2000) [2000|2255] "year" CGM,CSM,RadioLow
 SG_ LclTmYrVal_Inv : 7|1@0+ (1,0) [0|1] "" CSM,RadioLow
 SG_ LclTmMinVal : 13|6@0+ (1,0) [0|63] "minutes" CGM,CSM,RadioLow
 SG_ LclTmMinVal_Inv : 14|1@0+ (1,0) [0|1] "" CSM,RadioLow
 SG_ LclTmDayVal_Inv : 16|1@0+ (1,0) [0|1] "" CSM,RadioLow
 SG_ LclTmSecVal : 22|6@0+ (1,0) [0|63] "seconds" CGM,CSM,RadioLow
 SG_ LclTmSecVal_Inv : 23|1@0+ (1,0) [0|1] "" CSM,RadioLow
 SG_ LclTmHrVal : 25|5@0+ (1,0) [0|31] "hours" CGM,CSM,RadioLow
 SG_ LclTmHrVal_Inv : 26|1@0+ (1,0) [0|1] "" CSM,RadioLow
 SG_ LclTmDayVal : 31|5@0+ (1,0) [0|31] "day" CGM,CSM,RadioLow
 SG_ LclTmMthVal : 35|4@0+ (1,0) [0|12] "" CGM,CSM,RadioLow
 SG_ LclTmMthVal_Inv : 36|1@0+ (1,0) [0|1] "" CSM,RadioLow

BO_ 1308 Infotainment_Group_B_CAN5_PDU01: 8 ICS_Info
 SG_ FrtCntrStckEncdr4 : 7|8@0- (1,0) [-128|127] "count" CSM,TCP
 SG_ FrtCntrStckEncdr5 : 15|8@0- (1,0) [-128|127] "count" CSM,TCP
 SG_ FrtCntrStckMenuEncdr : 23|8@0- (1,0) [-128|127] "count" CSM,TCP
 SG_ FrtCntrStckTuneEncdr : 31|8@0- (1,0) [-128|127] "count" CSM,TCP
 SG_ FrtCntrStckVolEncdr : 39|8@0- (1,0) [-128|127] "count" CSM,TCP
 SG_ FrtCntrStckFvrtUpSw : 40|1@0+ (1,0) [0|1] "" CSM,TCP
 SG_ FrtCntrStckFvrtDnSw : 41|1@0+ (1,0) [0|1] "" CSM,TCP
 SG_ FrtCntrStckEjectSw : 42|1@0+ (1,0) [0|1] "" CSM,TCP
 SG_ FrtCntrStckDiscAuxSw : 43|1@0+ (1,0) [0|1] "" CSM,TCP
 SG_ FrtCntrStckBndSw : 44|1@0+ (1,0) [0|1] "" CSM,TCP
 SG_ FrtCntrStckBnchBtnID_VirtSw : 45|1@0+ (1,0) [0|1] "" CSM
 SG_ FrtCntrStckBackSw : 46|1@0+ (1,0) [0|1] "" CSM,TCP
 SG_ FrtCntrStckAllRelSw : 47|1@0+ (1,0) [0|1] "" CSM,TCP
 SG_ FrtCntrStckSw24 : 48|1@0+ (1,0) [0|1] "" CSM,TCP
 SG_ FrtCntrStckSw23 : 49|1@0+ (1,0) [0|1] "" CSM,TCP
 SG_ FrtCntrStckStrgeUnlckSw : 50|1@0+ (1,0) [0|1] "" CSM
 SG_ FrtCntrStckPwrSw : 51|1@0+ (1,0) [0|1] "" CSM,TCP
 SG_ FrtCntrStckPrevSw : 52|1@0+ (1,0) [0|1] "" CSM,TCP
 SG_ FrtCntrStckNextSw : 53|1@0+ (1,0) [0|1] "" CSM,TCP
 SG_ FrtCntrStckMenuSw : 54|1@0+ (1,0) [0|1] "" CSM,TCP
 SG_ FrtCntrStckHomeSw : 55|1@0+ (1,0) [0|1] "" CSM,TCP
 SG_ FrtCntrStckSw32 : 56|1@0+ (1,0) [0|1] "" CSM,TCP
 SG_ FrtCntrStckSw31 : 57|1@0+ (1,0) [0|1] "" CSM,TCP
 SG_ FrtCntrStckSw30 : 58|1@0+ (1,0) [0|1] "" CSM,TCP
 SG_ FrtCntrStckSw29 : 59|1@0+ (1,0) [0|1] "" CSM,TCP
 SG_ FrtCntrStckSw28 : 60|1@0+ (1,0) [0|1] "" CSM,TCP
 SG_ FrtCntrStckSw27 : 61|1@0+ (1,0) [0|1] "" CSM,TCP
 SG_ FrtCntrStckSw26 : 62|1@0+ (1,0) [0|1] "" CSM,TCP
 SG_ FrtCntrStckSw25 : 63|1@0+ (1,0) [0|1] "" CSM,TCP

BA_DEF_ SG_  "SignalType" STRING ;
BA_DEF_ SG_  "SignalLongName" STRING ;
BA_DEF_ BO_  "GenMsgCycleTime" INT 0 10000;
BA_DEF_ BO_  "GenMsgSendType" ENUM "cyclicX","spontanX","cyclicIfActiveX","spontanWithDelay","cyclicAndSpontanX","cyclicAndSpontanWithDelay","spontanWithRepetition","cyclicIfActiveAndSpontanWD";
BA_DEF_DEF_  "SignalType" "";
BA_DEF_DEF_  "SignalLongName" "";
BA_DEF_DEF_  "GenMsgCycleTime" 0;
BA_DEF_DEF_  "GenMsgSendType" "cyclicX";
BA_ "GenMsgCycleTime" BO_ 1182 1000;
BA_ "GenMsgCycleTime" BO_ 1183 1000;
BA_ "GenMsgCycleTime" BO_ 1184 1000;
BA_ "GenMsgCycleTime" BO_ 1185 1000;
BA_ "GenMsgCycleTime" BO_ 1186 1000;
BA_ "GenMsgCycleTime" BO_ 1187 1000;
BA_ "GenMsgCycleTime" BO_ 1361 1000;
BA_ "GenMsgCycleTime" BO_ 1362 1000;
BA_ "GenMsgCycleTime" BO_ 1367 1000;
BA_ "GenMsgCycleTime" BO_ 1368 1000;
BA_ "GenMsgCycleTime" BO_ 1370 1000;
BA_ "GenMsgCycleTime" BO_ 1372 1000;
BA_ "GenMsgCycleTime" BO_ 1371 1000;
BA_ "GenMsgCycleTime" BO_ 1295 1000;
BA_ "GenMsgCycleTime" BO_ 1363 1000;
BA_ "GenMsgCycleTime" BO_ 1365 1000;
BA_ "GenMsgCycleTime" BO_ 1360 1000;
BA_ "GenMsgCycleTime" BO_ 1299 1000;
BA_ "GenMsgCycleTime" BO_ 1369 1000;
BA_ "GenMsgCycleTime" BO_ 1373 1000;
BA_ "GenMsgCycleTime" BO_ 1302 1000;
BA_ "GenMsgCycleTime" BO_ 1271 1000;
BA_ "GenMsgCycleTime" BO_ 1376 1000;
BA_ "GenMsgCycleTime" BO_ 1399 1000;
BA_ "GenMsgCycleTime" BO_ 1398 1000;
BA_ "GenMsgCycleTime" BO_ 1375 1000;
BA_ "GenMsgCycleTime" BO_ 1400 1000;
BA_ "GenMsgCycleTime" BO_ 1383 1000;
BA_ "GenMsgCycleTime" BO_ 514 100;
BA_ "GenMsgCycleTime" BO_ 1077 100;
BA_ "GenMsgCycleTime" BO_ 623 100;
BA_ "GenMsgCycleTime" BO_ 1081 3500;
BA_ "GenMsgCycleTime" BO_ 1078 1000;
BA_ "GenMsgCycleTime" BO_ 1064 3500;
BA_ "GenMsgCycleTime" BO_ 1059 1000;
BA_ "GenMsgCycleTime" BO_ 1364 1000;
BA_ "GenMsgCycleTime" BO_ 185 1000;
BA_ "GenMsgCycleTime" BO_ 186 1000;
BA_ "GenMsgCycleTime" BO_ 1358 1000;
BA_ "GenMsgCycleTime" BO_ 1359 1000;
BA_ "GenMsgCycleTime" BO_ 1303 1000;
BA_ "GenMsgCycleTime" BO_ 1354 1000;
BA_ "GenMsgCycleTime" BO_ 1352 1000;
BA_ "GenMsgCycleTime" BO_ 1397 1000;
BA_ "GenMsgCycleTime" BO_ 1310 1000;
BA_ "GenMsgCycleTime" BO_ 1311 1000;
BA_ "GenMsgCycleTime" BO_ 1312 1000;
BA_ "GenMsgCycleTime" BO_ 1313 1000;
BA_ "GenMsgCycleTime" BO_ 1418 1000;
BA_ "GenMsgCycleTime" BO_ 1316 1000;
BA_ "GenMsgCycleTime" BO_ 1317 1000;
BA_ "GenMsgCycleTime" BO_ 1318 1000;
BA_ "GenMsgCycleTime" BO_ 1319 1000;
BA_ "GenMsgCycleTime" BO_ 1320 1000;
BA_ "GenMsgCycleTime" BO_ 1321 1000;
BA_ "GenMsgCycleTime" BO_ 613 100;
BA_ "GenMsgCycleTime" BO_ 1273 1000;
BA_ "GenMsgCycleTime" BO_ 1275 1000;
BA_ "GenMsgCycleTime" BO_ 1276 1000;
BA_ "GenMsgCycleTime" BO_ 1277 1000;
BA_ "GenMsgCycleTime" BO_ 1278 1000;
BA_ "GenMsgCycleTime" BO_ 1279 1000;
BA_ "GenMsgCycleTime" BO_ 1280 1000;
BA_ "GenMsgCycleTime" BO_ 1281 1000;
BA_ "GenMsgCycleTime" BO_ 1282 1000;
BA_ "GenMsgCycleTime" BO_ 1283 1000;
BA_ "GenMsgCycleTime" BO_ 1284 1000;
BA_ "GenMsgCycleTime" BO_ 615 250;
BA_ "GenMsgCycleTime" BO_ 1332 1000;
BA_ "GenMsgCycleTime" BO_ 1308 1000;
BA_ "SignalLongName" SG_ 1182 TrlrTireRtMdlSnsrID "Trailer Tire Right Middle Sensor Identifier";
BA_ "SignalLongName" SG_ 1182 TrlrTireRtMdlPres "Trailer Tire Right Middle Pressure";
BA_ "SignalType" SG_ 1182 TrlrTireRtMdlPres_Inv "ENM";
BA_ "SignalLongName" SG_ 1182 TrlrTireRtMdlPres_Inv "Trailer Tire Right Middle Pressure Invalid";
BA_ "SignalLongName" SG_ 1182 TrlrTireRtMdlTemp "Trailer Tire Right Middle Temperature";
BA_ "SignalType" SG_ 1182 TrlrTireRtMdlTemp_Inv "ENM";
BA_ "SignalLongName" SG_ 1182 TrlrTireRtMdlTemp_Inv "Trailer Tire Right Middle Temperature Invalid";
BA_ "SignalType" SG_ 1182 TrlrTireRtMdlPresSts "ENM";
BA_ "SignalLongName" SG_ 1182 TrlrTireRtMdlPresSts "Trailer Tire Right Middle Pressure Status";
BA_ "SignalType" SG_ 1182 TrlrTireRtMdlPresSts_Inv "ENM";
BA_ "SignalLongName" SG_ 1182 TrlrTireRtMdlPresSts_Inv "Trailer Tire Right Middle Pressure Status Invalid";
BA_ "SignalLongName" SG_ 1183 TrlrTireRFSnsrID "Trailer Tire Right Front Sensor Identifier";
BA_ "SignalLongName" SG_ 1183 TrlrTireRFPres "Trailer Tire Right Front Pressure";
BA_ "SignalType" SG_ 1183 TrlrTireRFPres_Inv "ENM";
BA_ "SignalLongName" SG_ 1183 TrlrTireRFPres_Inv "Trailer Tire Right Front Pressure Invalid";
BA_ "SignalLongName" SG_ 1183 TrlrTireRFTemp "Trailer Tire Right Front Temperature";
BA_ "SignalType" SG_ 1183 TrlrTireRFTemp_Inv "ENM";
BA_ "SignalLongName" SG_ 1183 TrlrTireRFTemp_Inv "Trailer Tire Right Front Temperature Invalid";
BA_ "SignalType" SG_ 1183 TrlrTirePresSysFaild "ENM";
BA_ "SignalLongName" SG_ 1183 TrlrTirePresSysFaild "Trailer Tire Pressure System Failed";
BA_ "SignalType" SG_ 1183 TrlrTirePresFtrEnbld "ENM";
BA_ "SignalLongName" SG_ 1183 TrlrTirePresFtrEnbld "Trailer Tire Pressure Feature Enabled";
BA_ "SignalType" SG_ 1183 TrlrTireRFPresSts "ENM";
BA_ "SignalLongName" SG_ 1183 TrlrTireRFPresSts "Trailer Tire Right Front Pressure Status";
BA_ "SignalType" SG_ 1183 TrlrTireRFPresSts_Inv "ENM";
BA_ "SignalLongName" SG_ 1183 TrlrTireRFPresSts_Inv "Trailer Tire Right Front Pressure Status Invalid";
BA_ "SignalLongName" SG_ 1184 TrlrTireLRSnsrID "Trailer Tire Left Rear Sensor Identifier";
BA_ "SignalLongName" SG_ 1184 TrlrTireLRPres "Trailer Tire Left Rear Pressure";
BA_ "SignalType" SG_ 1184 TrlrTireLRPres_Inv "ENM";
BA_ "SignalLongName" SG_ 1184 TrlrTireLRPres_Inv "Trailer Tire Left Rear Pressure Invalid";
BA_ "SignalLongName" SG_ 1184 TrlrTireLRTemp "Trailer Tire Left Rear Temperature";
BA_ "SignalType" SG_ 1184 TrlrTireLRTemp_Inv "ENM";
BA_ "SignalLongName" SG_ 1184 TrlrTireLRTemp_Inv "Trailer Tire Left Rear Temperature Invalid";
BA_ "SignalType" SG_ 1184 TnDrvOvSpdWrnCstAvlFlg2 "ENM";
BA_ "SignalLongName" SG_ 1184 TnDrvOvSpdWrnCstAvlFlg2 "Teen Driver Overspeed Warning Customization Availability Flag 2";
BA_ "SignalType" SG_ 1184 TnDrvOvSpdWrnCstAvlFlg1 "ENM";
BA_ "SignalLongName" SG_ 1184 TnDrvOvSpdWrnCstAvlFlg1 "Teen Driver Overspeed Warning Customization Availability Flag 1";
BA_ "SignalType" SG_ 1184 TrlrTireLRPresSts "ENM";
BA_ "SignalLongName" SG_ 1184 TrlrTireLRPresSts "Trailer Tire Left Rear Pressure Status";
BA_ "SignalType" SG_ 1184 TrlrTireLRPresSts_Inv "ENM";
BA_ "SignalLongName" SG_ 1184 TrlrTireLRPresSts_Inv "Trailer Tire Left Rear Pressure Status Invalid";
BA_ "SignalType" SG_ 1184 TnDrvOvSpdWrnCstAvlFlg7 "ENM";
BA_ "SignalLongName" SG_ 1184 TnDrvOvSpdWrnCstAvlFlg7 "Teen Driver Overspeed Warning Customization Availability Flag 7";
BA_ "SignalType" SG_ 1184 TnDrvOvSpdWrnCstAvlFlg6 "ENM";
BA_ "SignalLongName" SG_ 1184 TnDrvOvSpdWrnCstAvlFlg6 "Teen Driver Overspeed Warning Customization Availability Flag 6";
BA_ "SignalType" SG_ 1184 TnDrvOvSpdWrnCstAvlFlg5 "ENM";
BA_ "SignalLongName" SG_ 1184 TnDrvOvSpdWrnCstAvlFlg5 "Teen Driver Overspeed Warning Customization Availability Flag 5";
BA_ "SignalType" SG_ 1184 TnDrvOvSpdWrnCstAvlFlg4 "ENM";
BA_ "SignalLongName" SG_ 1184 TnDrvOvSpdWrnCstAvlFlg4 "Teen Driver Overspeed Warning Customization Availability Flag 4";
BA_ "SignalType" SG_ 1184 TnDrvOvSpdWrnCstAvlFlg3 "ENM";
BA_ "SignalLongName" SG_ 1184 TnDrvOvSpdWrnCstAvlFlg3 "Teen Driver Overspeed Warning Customization Availability Flag 3";
BA_ "SignalLongName" SG_ 1185 TrlrTireLtMdlSnsrID "Trailer Tire Left Middle Sensor Identifier";
BA_ "SignalLongName" SG_ 1185 TrlrTireLtMdlPres "Trailer Tire Left Middle Pressure";
BA_ "SignalType" SG_ 1185 TrlrTireLtMdlPres_Inv "ENM";
BA_ "SignalLongName" SG_ 1185 TrlrTireLtMdlPres_Inv "Trailer Tire Left Middle Pressure Invalid";
BA_ "SignalLongName" SG_ 1185 TrlrTireLtMdlTemp "Trailer Tire Left Middle Temperature";
BA_ "SignalType" SG_ 1185 TrlrTireLtMdlTemp_Inv "ENM";
BA_ "SignalLongName" SG_ 1185 TrlrTireLtMdlTemp_Inv "Trailer Tire Left Middle Temperature Invalid";
BA_ "SignalType" SG_ 1185 TnDrvSpdLmtCstAvlFlg2 "ENM";
BA_ "SignalLongName" SG_ 1185 TnDrvSpdLmtCstAvlFlg2 "Teen Driver Speed Limit Customization Availability Flag 2";
BA_ "SignalType" SG_ 1185 TnDrvSpdLmtCstAvlFlg1 "ENM";
BA_ "SignalLongName" SG_ 1185 TnDrvSpdLmtCstAvlFlg1 "Teen Driver Speed Limit Customization Availability Flag 1";
BA_ "SignalType" SG_ 1185 TrlrTireLtMdlPresSts "ENM";
BA_ "SignalLongName" SG_ 1185 TrlrTireLtMdlPresSts "Trailer Tire Left Middle Pressure Status";
BA_ "SignalType" SG_ 1185 TrlrTireLtMdlPresSts_Inv "ENM";
BA_ "SignalLongName" SG_ 1185 TrlrTireLtMdlPresSts_Inv "Trailer Tire Left Middle Pressure Status Invalid";
BA_ "SignalType" SG_ 1185 TnDrvSpdLmtCstAvlFlg7 "ENM";
BA_ "SignalLongName" SG_ 1185 TnDrvSpdLmtCstAvlFlg7 "Teen Driver Speed Limit Customization Availability Flag 7";
BA_ "SignalType" SG_ 1185 TnDrvSpdLmtCstAvlFlg6 "ENM";
BA_ "SignalLongName" SG_ 1185 TnDrvSpdLmtCstAvlFlg6 "Teen Driver Speed Limit Customization Availability Flag 6";
BA_ "SignalType" SG_ 1185 TnDrvSpdLmtCstAvlFlg5 "ENM";
BA_ "SignalLongName" SG_ 1185 TnDrvSpdLmtCstAvlFlg5 "Teen Driver Speed Limit Customization Availability Flag 5";
BA_ "SignalType" SG_ 1185 TnDrvSpdLmtCstAvlFlg4 "ENM";
BA_ "SignalLongName" SG_ 1185 TnDrvSpdLmtCstAvlFlg4 "Teen Driver Speed Limit Customization Availability Flag 4";
BA_ "SignalType" SG_ 1185 TnDrvSpdLmtCstAvlFlg3 "ENM";
BA_ "SignalLongName" SG_ 1185 TnDrvSpdLmtCstAvlFlg3 "Teen Driver Speed Limit Customization Availability Flag 3";
BA_ "SignalLongName" SG_ 1186 TrlrTireLFSnsrID "Trailer Tire Left Front Sensor Identifier";
BA_ "SignalLongName" SG_ 1186 TrlrTireLFPres "Trailer Tire Left Front Pressure";
BA_ "SignalType" SG_ 1186 TrlrTireLFPres_Inv "ENM";
BA_ "SignalLongName" SG_ 1186 TrlrTireLFPres_Inv "Trailer Tire Left Front Pressure Invalid";
BA_ "SignalLongName" SG_ 1186 TrlrTireLFTemp "Trailer Tire Left Front Temperature";
BA_ "SignalType" SG_ 1186 TrlrTireLFTemp_Inv "ENM";
BA_ "SignalLongName" SG_ 1186 TrlrTireLFTemp_Inv "Trailer Tire Left Front Temperature Invalid";
BA_ "SignalType" SG_ 1186 TrlrTireLFPresSts "ENM";
BA_ "SignalLongName" SG_ 1186 TrlrTireLFPresSts "Trailer Tire Left Front Pressure Status";
BA_ "SignalType" SG_ 1186 TrlrTireLFPresSts_Inv "ENM";
BA_ "SignalLongName" SG_ 1186 TrlrTireLFPresSts_Inv "Trailer Tire Left Front Pressure Status Invalid";
BA_ "SignalType" SG_ 1186 TrlrProfSeltnResp "ENM";
BA_ "SignalLongName" SG_ 1186 TrlrProfSeltnResp "Trailer Profile Selection Response";
BA_ "SignalType" SG_ 1186 TrlrTireLrnSts "ENM";
BA_ "SignalLongName" SG_ 1186 TrlrTireLrnSts "Trailer Tire Learn Status";
BA_ "SignalLongName" SG_ 1187 TirePrsFrntPlcrd "Tire Pressure Front Placard";
BA_ "SignalLongName" SG_ 1187 TirePrsRrPlcrd "Tire Pressure Rear Placard";
BA_ "SignalLongName" SG_ 1187 TireTmpLF "Tire Temperature (LF)";
BA_ "SignalType" SG_ 1187 TireTmpLF_Inv "ENM";
BA_ "SignalLongName" SG_ 1187 TireTmpLF_Inv "Tire Temperature (LF) Invalid";
BA_ "SignalLongName" SG_ 1187 TireTmpLR "Tire Temperature (LR)";
BA_ "SignalType" SG_ 1187 TireTmpLR_Inv "ENM";
BA_ "SignalLongName" SG_ 1187 TireTmpLR_Inv "Tire Temperature (LR) Invalid";
BA_ "SignalLongName" SG_ 1187 TireTmpRF "Tire Temperature (RF)";
BA_ "SignalType" SG_ 1187 TireTmpRF_Inv "ENM";
BA_ "SignalLongName" SG_ 1187 TireTmpRF_Inv "Tire Temperature (RF) Invalid";
BA_ "SignalLongName" SG_ 1187 TireTmpRR "Tire Temperature (RR)";
BA_ "SignalType" SG_ 1187 TireTmpRR_Inv "ENM";
BA_ "SignalLongName" SG_ 1187 TireTmpRR_Inv "Tire Temperature (RR) Invalid";
BA_ "SignalLongName" SG_ 1361 HVACFCRADSF_Lt4Rt1RwVltg "HVAC Front Controls Request Air Distribution Setting Front : Left Raw Voltage 4 / Right Raw Voltage 1";
BA_ "SignalLongName" SG_ 1361 HVACFCRADSF_LtRwVltg1 "HVAC Front Controls Request Air Distribution Setting Front : Left Raw Voltage 1";
BA_ "SignalLongName" SG_ 1361 HVACFCRADSF_LtRwVltg2 "HVAC Front Controls Request Air Distribution Setting Front : Left Raw Voltage 2";
BA_ "SignalLongName" SG_ 1361 HVACFCRADSF_LtRwVltg3 "HVAC Front Controls Request Air Distribution Setting Front : Left Raw Voltage 3";
BA_ "SignalLongName" SG_ 1361 HVACFCRADSF_RtRwVltg2 "HVAC Front Controls Request Air Distribution Setting Front : Right Raw Voltage 2";
BA_ "SignalType" SG_ 1361 HVACFCRADSF_LtSet "ENM";
BA_ "SignalLongName" SG_ 1361 HVACFCRADSF_LtSet "HVAC Front Controls Request Air Distribution Setting Front : Left Setting";
BA_ "SignalType" SG_ 1361 HVACFCRADSF_RtSet "ENM";
BA_ "SignalLongName" SG_ 1361 HVACFCRADSF_RtSet "HVAC Front Controls Request Air Distribution Setting Front : Right Setting";
BA_ "SignalLongName" SG_ 1361 HVACFCRADSF_CS "HVAC Front Controls Request Air Distribution Setting Front : Checksum";
BA_ "SignalLongName" SG_ 1361 HVACFCRADSF_ARC "HVAC Front Controls Request Air Distribution Setting Front : Alive Rolling Count";
BA_ "SignalLongName" SG_ 1362 HVACFCRBLCFOR_ORX1 "HVAC Front Controls Request Blower Level Change Front Out of Range : Out of Range X 1";
BA_ "SignalLongName" SG_ 1362 HVACFCRBLCFOR_ORX2 "HVAC Front Controls Request Blower Level Change Front Out of Range : Out of Range X 2";
BA_ "SignalLongName" SG_ 1362 HVACFCRBLCFOR_ORY1 "HVAC Front Controls Request Blower Level Change Front Out of Range : Out of Range Y 1";
BA_ "SignalLongName" SG_ 1362 HVACFCRBLCFOR_ORY2 "HVAC Front Controls Request Blower Level Change Front Out of Range : Out of Range Y 2";
BA_ "SignalLongName" SG_ 1362 HVACFCRBLCFOR_CS "HVAC Front Controls Request Blower Level Change Front Out of Range : Checksum";
BA_ "SignalLongName" SG_ 1362 HVACFCRBLCFOR_ARC "HVAC Front Controls Request Blower Level Change Front Out of Range : Alive Rolling Count";
BA_ "SignalLongName" SG_ 1367 HVACFCRRFA_FrshAirRwVltg "HVAC Front Controls Request Recirculation and Front Auto : Fresh Air Raw Voltage";
BA_ "SignalLongName" SG_ 1367 HVACFCRRFA_FrtAutoRwVltg "HVAC Front Controls Request Recirculation and Front Auto : Front Auto Raw Voltage";
BA_ "SignalType" SG_ 1367 HVACFCRRFA_FrshAirSetChg "ENM";
BA_ "SignalLongName" SG_ 1367 HVACFCRRFA_FrshAirSetChg "HVAC Front Controls Request Recirculation and Front Auto : Fresh Air Setting Change";
BA_ "SignalLongName" SG_ 1367 HVACFCRRFA_RecircRwVltg1 "HVAC Front Controls Request Recirculation and Front Auto : Recirculation Raw Voltage 1";
BA_ "SignalType" SG_ 1367 HVACFCRRFA_FrtAutoSetChg "ENM";
BA_ "SignalLongName" SG_ 1367 HVACFCRRFA_FrtAutoSetChg "HVAC Front Controls Request Recirculation and Front Auto : Front Auto Setting Change";
BA_ "SignalLongName" SG_ 1367 HVACFCRRFA_RecircRwVltg2 "HVAC Front Controls Request Recirculation and Front Auto : Recirculation Raw Voltage 2";
BA_ "SignalType" SG_ 1367 HVACFCRRFA_RecircSetChg "ENM";
BA_ "SignalLongName" SG_ 1367 HVACFCRRFA_RecircSetChg "HVAC Front Controls Request Recirculation and Front Auto : Recirculation Setting Change";
BA_ "SignalLongName" SG_ 1367 HVACFCRRFA_CS "HVAC Front Controls Request Recirculation and Front Auto : Checksum";
BA_ "SignalLongName" SG_ 1367 HVACFCRRFA_ARC "HVAC Front Controls Request Recirculation and Front Auto : Alive Rolling Count";
BA_ "SignalLongName" SG_ 1368 HVACFCRTLCFLOR1n2_ORX1 "HVAC Front Controls Request Temperature Level Change Front Left Out of Range 1 and 2 : Out of Range X 1";
BA_ "SignalLongName" SG_ 1368 HVACFCRTLCFLOR1n2_ORX2 "HVAC Front Controls Request Temperature Level Change Front Left Out of Range 1 and 2 : Out of Range X 2";
BA_ "SignalLongName" SG_ 1368 HVACFCRTLCFLOR1n2_ORY1 "HVAC Front Controls Request Temperature Level Change Front Left Out of Range 1 and 2 : Out of Range Y 1";
BA_ "SignalLongName" SG_ 1368 HVACFCRTLCFLOR1n2_ORY2 "HVAC Front Controls Request Temperature Level Change Front Left Out of Range 1 and 2 : Out of Range Y 2";
BA_ "SignalLongName" SG_ 1368 HVACFCRTLCFLOR1n2_CS "HVAC Front Controls Request Temperature Level Change Front Left Out of Range 1 and 2 : Checksum";
BA_ "SignalLongName" SG_ 1368 HVACFCRTLCFLOR1n2_ARC "HVAC Front Controls Request Temperature Level Change Front Left Out of Range 1 and 2 : Alive Rolling Count";
BA_ "SignalLongName" SG_ 1370 HVACFCRTLCFOR3_RtORY3 "HVAC Front Controls Request Temperature Level Change Front Out of Range 3 : Right Out of Range Y 3";
BA_ "SignalLongName" SG_ 1370 HVACFCRTLCFOR3_RtORX3 "HVAC Front Controls Request Temperature Level Change Front Out of Range 3 : Right Out of Range X 3";
BA_ "SignalLongName" SG_ 1370 HVACFCRTLCFOR3_LtORY3 "HVAC Front Controls Request Temperature Level Change Front Out of Range 3 : Left Out of Range Y 3";
BA_ "SignalLongName" SG_ 1370 HVACFCRTLCFOR3_LtORX3 "HVAC Front Controls Request Temperature Level Change Front Out of Range 3 : Left Out of Range X 3";
BA_ "SignalLongName" SG_ 1370 HVACFCRTLCFOR3_CS "HVAC Front Controls Request Temperature Level Change Front Out of Range 3 : Checksum";
BA_ "SignalLongName" SG_ 1370 HVACFCRTLCFOR3_ARC "HVAC Front Controls Request Temperature Level Change Front Out of Range 3 : Alive Rolling Count";
BA_ "SignalLongName" SG_ 1372 HVACFCRTLCFR_LvlChg "HVAC Front Controls Request Temperature Level Change Front Right : Level Change";
BA_ "SignalType" SG_ 1372 HVACFCRTLCFR_ORL2 "ENM";
BA_ "SignalLongName" SG_ 1372 HVACFCRTLCFR_ORL2 "HVAC Front Controls Request Temperature Level Change Front Right : Out of Range Low 2";
BA_ "SignalLongName" SG_ 1372 HVACFCRTLCFR_RwVltg3 "HVAC Front Controls Request Temperature Level Change Front Right : Raw Voltage 3";
BA_ "SignalType" SG_ 1372 HVACFCRTLCFR_ORL1 "ENM";
BA_ "SignalLongName" SG_ 1372 HVACFCRTLCFR_ORL1 "HVAC Front Controls Request Temperature Level Change Front Right : Out of Range Low 1";
BA_ "SignalType" SG_ 1372 HVACFCRTLCFR_ORH2 "ENM";
BA_ "SignalLongName" SG_ 1372 HVACFCRTLCFR_ORH2 "HVAC Front Controls Request Temperature Level Change Front Right : Out of Range High 2";
BA_ "SignalLongName" SG_ 1372 HVACFCRTLCFR_RwVltg1 "HVAC Front Controls Request Temperature Level Change Front Right : Raw Voltage 1";
BA_ "SignalLongName" SG_ 1372 HVACFCRTLCFR_RwVltg2 "HVAC Front Controls Request Temperature Level Change Front Right : Raw Voltage 2";
BA_ "SignalType" SG_ 1372 HVACFCRTLCFR_ORL3 "ENM";
BA_ "SignalLongName" SG_ 1372 HVACFCRTLCFR_ORL3 "HVAC Front Controls Request Temperature Level Change Front Right : Out of Range Low 3";
BA_ "SignalType" SG_ 1372 HVACFCRTLCFR_ORH1 "ENM";
BA_ "SignalLongName" SG_ 1372 HVACFCRTLCFR_ORH1 "HVAC Front Controls Request Temperature Level Change Front Right : Out of Range High 1";
BA_ "SignalType" SG_ 1372 HVACFCRTLCFR_ORH3 "ENM";
BA_ "SignalLongName" SG_ 1372 HVACFCRTLCFR_ORH3 "HVAC Front Controls Request Temperature Level Change Front Right : Out of Range High 3";
BA_ "SignalLongName" SG_ 1372 HVACFCRTLCFR_CS "HVAC Front Controls Request Temperature Level Change Front Right : Checksum";
BA_ "SignalType" SG_ 1372 HVACFCRTLCFR_CktCorr "ENM";
BA_ "SignalLongName" SG_ 1372 HVACFCRTLCFR_CktCorr "HVAC Front Controls Request Temperature Level Change Front Right : Circuit Correlation";
BA_ "SignalLongName" SG_ 1372 HVACFCRTLCFR_ARC "HVAC Front Controls Request Temperature Level Change Front Right : Alive Rolling Count";
BA_ "SignalLongName" SG_ 1371 HVACFCRTLCFROR1n2_ORX1 "HVAC Front Controls Request Temperature Level Change Front Right Out of Range 1 and 2 : Out of Range X 1";
BA_ "SignalLongName" SG_ 1371 HVACFCRTLCFROR1n2_ORY1 "HVAC Front Controls Request Temperature Level Change Front Right Out of Range 1 and 2 : Out of Range Y 1";
BA_ "SignalLongName" SG_ 1371 HVACFCRTLCFROR1n2_ORX2 "HVAC Front Controls Request Temperature Level Change Front Right Out of Range 1 and 2 : Out of Range X 2";
BA_ "SignalLongName" SG_ 1371 HVACFCRTLCFROR1n2_ORY2 "HVAC Front Controls Request Temperature Level Change Front Right Out of Range 1 and 2 : Out of Range Y 2";
BA_ "SignalLongName" SG_ 1371 HVACFCRTLCFROR1n2_CS "HVAC Front Controls Request Temperature Level Change Front Right Out of Range 1 and 2 : Checksum";
BA_ "SignalLongName" SG_ 1371 HVACFCRTLCFROR1n2_ARC "HVAC Front Controls Request Temperature Level Change Front Right Out of Range 1 and 2 : Alive Rolling Count";
BA_ "SignalLongName" SG_ 1295 HVACFCRACH_CompSetRwVltg "HVAC Front Controls Request AC and Heat : Compressor Setting Raw Voltage";
BA_ "SignalLongName" SG_ 1295 HVACFCRACH_HtrSetRwVltg "HVAC Front Controls Request AC and Heat : Heater Setting Raw Voltage";
BA_ "SignalType" SG_ 1295 HVACFCRACH_CompSetChg "ENM";
BA_ "SignalLongName" SG_ 1295 HVACFCRACH_CompSetChg "HVAC Front Controls Request AC and Heat : Compressor Setting Change";
BA_ "SignalType" SG_ 1295 HVACFCRACH_HtrSetChg "ENM";
BA_ "SignalLongName" SG_ 1295 HVACFCRACH_HtrSetChg "HVAC Front Controls Request AC and Heat : Heater Setting Change";
BA_ "SignalType" SG_ 1295 HVACFCRACH_HtrSet "ENM";
BA_ "SignalLongName" SG_ 1295 HVACFCRACH_HtrSet "HVAC Front Controls Request AC and Heat : Heater Setting";
BA_ "SignalLongName" SG_ 1295 HVACFCRACH_ARC "HVAC Front Controls Request AC and Heat : Alive Rolling Count";
BA_ "SignalLongName" SG_ 1295 HVACFCRL_RwVltg "HVAC Front Controls Rear Lock : Raw Voltage";
BA_ "SignalType" SG_ 1295 RHVSLF_HtdCushBckLvlChgDn "ENM";
BA_ "SignalLongName" SG_ 1295 RHVSLF_HtdCushBckLvlChgDn "Request Heated Vented Seat Left Front : Heated Cushion and Back Level Change Down";
BA_ "SignalType" SG_ 1295 RHVSLF_HtdBckLvlChgDn "ENM";
BA_ "SignalLongName" SG_ 1295 RHVSLF_HtdBckLvlChgDn "Request Heated Vented Seat Left Front : Heated Back Level Change Down";
BA_ "SignalType" SG_ 1295 RHVSLF_VntLvlChgUp "ENM";
BA_ "SignalLongName" SG_ 1295 RHVSLF_VntLvlChgUp "Request Heated Vented Seat Left Front : Vented Level Change Up";
BA_ "SignalType" SG_ 1295 RHVSLF_VntLvlChgDn "ENM";
BA_ "SignalLongName" SG_ 1295 RHVSLF_VntLvlChgDn "Request Heated Vented Seat Left Front : Vented Level Change Down";
BA_ "SignalType" SG_ 1295 RHVSLF_HtdCushBckLvlChgUp "ENM";
BA_ "SignalLongName" SG_ 1295 RHVSLF_HtdCushBckLvlChgUp "Request Heated Vented Seat Left Front : Heated Cushion and Back Level Change Up";
BA_ "SignalType" SG_ 1295 RHVSLF_HtdBckLvlChgUp "ENM";
BA_ "SignalLongName" SG_ 1295 RHVSLF_HtdBckLvlChgUp "Request Heated Vented Seat Left Front : Heated Back Level Change Up";
BA_ "SignalType" SG_ 1295 HVACFCRL_SetChg "ENM";
BA_ "SignalLongName" SG_ 1295 HVACFCRL_SetChg "HVAC Front Controls Rear Lock : Setting Change";
BA_ "SignalType" SG_ 1295 HtdStBckCushStckSwLF "ENM";
BA_ "SignalLongName" SG_ 1295 HtdStBckCushStckSwLF "Heated Seat Back and Cushion Stuck Switch Left Front";
BA_ "SignalType" SG_ 1295 HVACFrtCtlReqSyncRrSetChg "ENM";
BA_ "SignalLongName" SG_ 1295 HVACFrtCtlReqSyncRrSetChg "HVAC Front Controls Request Sync Rear Setting Change";
BA_ "SignalType" SG_ 1295 RHVSRF_VntLvlChgUp "ENM";
BA_ "SignalLongName" SG_ 1295 RHVSRF_VntLvlChgUp "Request Heated Vented Seat Right Front : Vented Level Change Up";
BA_ "SignalType" SG_ 1295 RHVSRF_HtdCushBckLvlChgUp "ENM";
BA_ "SignalLongName" SG_ 1295 RHVSRF_HtdCushBckLvlChgUp "Request Heated Vented Seat Right Front : Heated Cushion and Back Level Change Up";
BA_ "SignalType" SG_ 1295 RHVSRF_HtdCushBckLvlChgDn "ENM";
BA_ "SignalLongName" SG_ 1295 RHVSRF_HtdCushBckLvlChgDn "Request Heated Vented Seat Right Front : Heated Cushion and Back Level Change Down";
BA_ "SignalType" SG_ 1295 RHVSRF_VntLvlChgDn "ENM";
BA_ "SignalLongName" SG_ 1295 RHVSRF_VntLvlChgDn "Request Heated Vented Seat Right Front : Vented Level Change Down";
BA_ "SignalType" SG_ 1295 RHVSRF_HtdBckLvlChgUp "ENM";
BA_ "SignalLongName" SG_ 1295 RHVSRF_HtdBckLvlChgUp "Request Heated Vented Seat Right Front : Heated Back Level Change Up";
BA_ "SignalType" SG_ 1295 RHVSRF_HtdBckLvlChgDn "ENM";
BA_ "SignalLongName" SG_ 1295 RHVSRF_HtdBckLvlChgDn "Request Heated Vented Seat Right Front : Heated Back Level Change Down";
BA_ "SignalType" SG_ 1295 VntStStckSwRF "ENM";
BA_ "SignalLongName" SG_ 1295 VntStStckSwRF "Vented Seat Stuck Switch Right Front";
BA_ "SignalType" SG_ 1295 VntStStckSwLF "ENM";
BA_ "SignalLongName" SG_ 1295 VntStStckSwLF "Vented Seat Stuck Switch Left Front";
BA_ "SignalType" SG_ 1295 HtdVntStSwActvRF "ENM";
BA_ "SignalLongName" SG_ 1295 HtdVntStSwActvRF "Heated Vented Seat Switch Active Right Front";
BA_ "SignalType" SG_ 1295 HtdVntStSwActvLF "ENM";
BA_ "SignalLongName" SG_ 1295 HtdVntStSwActvLF "Heated Vented Seat Switch Active Left Front";
BA_ "SignalType" SG_ 1295 HtdStBckStckSwRF "ENM";
BA_ "SignalLongName" SG_ 1295 HtdStBckStckSwRF "Heated Seat Back Stuck Switch Right Front";
BA_ "SignalType" SG_ 1295 HtdStBckStckSwLF "ENM";
BA_ "SignalLongName" SG_ 1295 HtdStBckStckSwLF "Heated Seat Back Stuck Switch Left Front";
BA_ "SignalType" SG_ 1295 HtdStBckCushStckSwRF "ENM";
BA_ "SignalLongName" SG_ 1295 HtdStBckCushStckSwRF "Heated Seat Back and Cushion Stuck Switch Right Front";
BA_ "SignalType" SG_ 1363 HVACFCRBLCF_ORL1 "ENM";
BA_ "SignalLongName" SG_ 1363 HVACFCRBLCF_ORL1 "HVAC Front Controls Request Blower Level Change Front : Out of Range Low 1";
BA_ "SignalType" SG_ 1363 HVACFCRBLCF_ORH2 "ENM";
BA_ "SignalLongName" SG_ 1363 HVACFCRBLCF_ORH2 "HVAC Front Controls Request Blower Level Change Front : Out of Range High 2";
BA_ "SignalType" SG_ 1363 HVACFCRBLCF_ORH1 "ENM";
BA_ "SignalLongName" SG_ 1363 HVACFCRBLCF_ORH1 "HVAC Front Controls Request Blower Level Change Front : Out of Range High 1";
BA_ "SignalLongName" SG_ 1363 HVACFCRBLCF_LvlChg "HVAC Front Controls Request Blower Level Change Front : Level Change";
BA_ "SignalLongName" SG_ 1363 HVACFCRBLCF_RwVltg1 "HVAC Front Controls Request Blower Level Change Front : Raw Voltage 1";
BA_ "SignalType" SG_ 1363 HVACFCRBLCF_ORL2 "ENM";
BA_ "SignalLongName" SG_ 1363 HVACFCRBLCF_ORL2 "HVAC Front Controls Request Blower Level Change Front : Out of Range Low 2";
BA_ "SignalLongName" SG_ 1363 HVACFCRBLCF_RwVltg2 "HVAC Front Controls Request Blower Level Change Front : Raw Voltage 2";
BA_ "SignalType" SG_ 1363 HVACFCRBLCF_CktCorr "ENM";
BA_ "SignalLongName" SG_ 1363 HVACFCRBLCF_CktCorr "HVAC Front Controls Request Blower Level Change Front : Circuit Correlation";
BA_ "SignalLongName" SG_ 1363 HVACFCRBLCF_CS "HVAC Front Controls Request Blower Level Change Front : Checksum";
BA_ "SignalLongName" SG_ 1363 HVACFCRBLCF_ARC "HVAC Front Controls Request Blower Level Change Front : Alive Rolling Count";
BA_ "SignalLongName" SG_ 1365 HVACFCRDP_FrtDefrRwVltg "HVAC Front Controls Request Defrost and Power : Front Defrost Raw Voltage";
BA_ "SignalLongName" SG_ 1365 HVACFCRDP_HtdFrtWshldRwVltg "HVAC Front Controls Request Defrost and Power : Heated Front Windshield Raw Voltage";
BA_ "SignalType" SG_ 1365 HVACFCRDP_FrtPwrSetChg_Inv "ENM";
BA_ "SignalLongName" SG_ 1365 HVACFCRDP_FrtPwrSetChg_Inv "HVAC Front Controls Request Defrost and Power : Front Power Setting Change Invalid";
BA_ "SignalType" SG_ 1365 HVACFCRDP_FrtPwrSetChg "ENM";
BA_ "SignalLongName" SG_ 1365 HVACFCRDP_FrtPwrSetChg "HVAC Front Controls Request Defrost and Power : Front Power Setting Change";
BA_ "SignalType" SG_ 1365 HVACFCRDP_IntrnlFltSts "ENM";
BA_ "SignalLongName" SG_ 1365 HVACFCRDP_IntrnlFltSts "HVAC Front Controls Request Defrost and Power : Internal Fault Status";
BA_ "SignalType" SG_ 1365 HVACFCRDP_InitFin "ENM";
BA_ "SignalLongName" SG_ 1365 HVACFCRDP_InitFin "HVAC Front Controls Request Defrost and Power : Initialization Finished";
BA_ "SignalType" SG_ 1365 HVACFCRDP_HtdFrtWshldSetChgd "ENM";
BA_ "SignalLongName" SG_ 1365 HVACFCRDP_HtdFrtWshldSetChgd "HVAC Front Controls Request Defrost and Power : Heated Front Windshield Setting Changed";
BA_ "SignalType" SG_ 1365 HVACFCRDP_MaxDefrSetChg "ENM";
BA_ "SignalLongName" SG_ 1365 HVACFCRDP_MaxDefrSetChg "HVAC Front Controls Request Defrost and Power : Max Defrost Setting Change";
BA_ "SignalLongName" SG_ 1365 HVACFCRDP_CS "HVAC Front Controls Request Defrost and Power : Checksum";
BA_ "SignalLongName" SG_ 1365 HVACFCRDP_ARC "HVAC Front Controls Request Defrost and Power : Alive Rolling Count";
BA_ "SignalLongName" SG_ 1360 HVACFCRADSCF_LtRwVltg "HVAC Front Controls Request Air Distribution Setting Change Front : Left Raw Voltage";
BA_ "SignalType" SG_ 1360 HVACFCRADSCF_LtChgNext "ENM";
BA_ "SignalLongName" SG_ 1360 HVACFCRADSCF_LtChgNext "HVAC Front Controls Request Air Distribution Setting Change Front : Left Change Next";
BA_ "SignalLongName" SG_ 1360 HVACFCRADSCF_RtRwVltg "HVAC Front Controls Request Air Distribution Setting Change Front : Right Raw Voltage";
BA_ "SignalType" SG_ 1360 HVACFCRADSCF_RtChgNext "ENM";
BA_ "SignalLongName" SG_ 1360 HVACFCRADSCF_RtChgNext "HVAC Front Controls Request Air Distribution Setting Change Front : Right Change Next";
BA_ "SignalLongName" SG_ 1360 HVACFCRADSCF_CS "HVAC Front Controls Request Air Distribution Setting Change Front : Checksum";
BA_ "SignalLongName" SG_ 1360 HVACFCRADSCF_ARC "HVAC Front Controls Request Air Distribution Setting Change Front : Alive Rolling Count";
BA_ "SignalLongName" SG_ 1299 HVACFCRBLR_RwVltg2 "HVAC Front Controls Request Blower Level Rear : Raw Voltage 2";
BA_ "SignalLongName" SG_ 1299 HVACFCRBLR_LvlChg "HVAC Front Controls Request Blower Level Rear : Level Change";
BA_ "SignalLongName" SG_ 1299 HVACFCRBLR_Lvl "HVAC Front Controls Request Blower Level Rear : Level";
BA_ "SignalType" SG_ 1299 HVACFCRBLR_LvlActv "ENM";
BA_ "SignalLongName" SG_ 1299 HVACFCRBLR_LvlActv "HVAC Front Controls Request Blower Level Rear : Level Active";
BA_ "SignalLongName" SG_ 1299 HVACFCRBLR_RwVltg1 "HVAC Front Controls Request Blower Level Rear : Raw Voltage 1";
BA_ "SignalType" SG_ 1369 HVACFCRTLCFL_ORL2 "ENM";
BA_ "SignalLongName" SG_ 1369 HVACFCRTLCFL_ORL2 "HVAC Front Controls Request Temperature Level Change Front Left : Out of Range Low 2";
BA_ "SignalType" SG_ 1369 HVACFCRTLCFL_ORL1 "ENM";
BA_ "SignalLongName" SG_ 1369 HVACFCRTLCFL_ORL1 "HVAC Front Controls Request Temperature Level Change Front Left : Out of Range Low 1";
BA_ "SignalType" SG_ 1369 HVACFCRTLCFL_ORH3 "ENM";
BA_ "SignalLongName" SG_ 1369 HVACFCRTLCFL_ORH3 "HVAC Front Controls Request Temperature Level Change Front Left : Out of Range High 3";
BA_ "SignalType" SG_ 1369 HVACFCRTLCFL_ORH2 "ENM";
BA_ "SignalLongName" SG_ 1369 HVACFCRTLCFL_ORH2 "HVAC Front Controls Request Temperature Level Change Front Left : Out of Range High 2";
BA_ "SignalType" SG_ 1369 HVACFCRTLCFL_ORH1 "ENM";
BA_ "SignalLongName" SG_ 1369 HVACFCRTLCFL_ORH1 "HVAC Front Controls Request Temperature Level Change Front Left : Out of Range High 1";
BA_ "SignalLongName" SG_ 1369 HVACFCRTLCFL_RwVltg1 "HVAC Front Controls Request Temperature Level Change Front Left : Raw Voltage 1";
BA_ "SignalType" SG_ 1369 HVACFCRTLCFL_ORL3 "ENM";
BA_ "SignalLongName" SG_ 1369 HVACFCRTLCFL_ORL3 "HVAC Front Controls Request Temperature Level Change Front Left : Out of Range Low 3";
BA_ "SignalLongName" SG_ 1369 HVACFCRTLCFL_RwVltg2 "HVAC Front Controls Request Temperature Level Change Front Left : Raw Voltage 2";
BA_ "SignalLongName" SG_ 1369 HVACFCRTLCFL_RwVltg3 "HVAC Front Controls Request Temperature Level Change Front Left : Raw Voltage 3";
BA_ "SignalLongName" SG_ 1369 HVACFCRTLCFL_LvlChg "HVAC Front Controls Request Temperature Level Change Front Left : Left Level Change";
BA_ "SignalType" SG_ 1369 HVACFCRTLCFL_CktCorr "ENM";
BA_ "SignalLongName" SG_ 1369 HVACFCRTLCFL_CktCorr "HVAC Front Controls Request Temperature Level Change Front Left : Circuit Correlation";
BA_ "SignalLongName" SG_ 1369 HVACFCRTLCFL_CS "HVAC Front Controls Request Temperature Level Change Front Left : Checksum";
BA_ "SignalLongName" SG_ 1369 HVACFCRTLCFL_ARC "HVAC Front Controls Request Temperature Level Change Front Left : Alive Rolling Count";
BA_ "SignalType" SG_ 1373 HVACFCRTLF_RtLvlActv "ENM";
BA_ "SignalLongName" SG_ 1373 HVACFCRTLF_RtLvlActv "HVAC Front Controls Request Temperature Level Front : Right Level Active";
BA_ "SignalLongName" SG_ 1373 HVACFCRTLF_LtLvl "HVAC Front Controls Request Temperature Level Front : Left Level";
BA_ "SignalLongName" SG_ 1373 HVACFCRTLF_LtRwVltg "HVAC Front Controls Request Temperature Level Front : Left Raw Voltage";
BA_ "SignalType" SG_ 1373 HVACFCRTLF_LtLvlActv "ENM";
BA_ "SignalLongName" SG_ 1373 HVACFCRTLF_LtLvlActv "HVAC Front Controls Request Temperature Level Front : Left Level Active";
BA_ "SignalLongName" SG_ 1373 HVACFCRTLF_RtLvl "HVAC Front Controls Request Temperature Level Front : Right Level";
BA_ "SignalLongName" SG_ 1373 HVACFCRTLF_RtRwVltg "HVAC Front Controls Request Temperature Level Front : Right Raw Voltage";
BA_ "SignalLongName" SG_ 1373 HVACFCRTLF_CS "HVAC Front Controls Request Temperature Level Front : Checksum";
BA_ "SignalLongName" SG_ 1373 HVACFCRTLF_ARC "HVAC Front Controls Request Temperature Level Front : Alive Rolling Count";
BA_ "SignalLongName" SG_ 1302 HVACFCRTLR_LtLvl "HVAC Front Controls Request Temperature Level Rear : Left Level";
BA_ "SignalType" SG_ 1302 HVACFCRTLR_RtLvlActv "ENM";
BA_ "SignalLongName" SG_ 1302 HVACFCRTLR_RtLvlActv "HVAC Front Controls Request Temperature Level Rear : Right Level Active";
BA_ "SignalLongName" SG_ 1302 HVACFCRTLR_LtLvlChg "HVAC Front Controls Request Temperature Level Rear : Left Level Change";
BA_ "SignalLongName" SG_ 1302 HVACFCRTLR_RwVltg1 "HVAC Front Controls Request Temperature Level Rear : Raw Voltage 1";
BA_ "SignalLongName" SG_ 1302 HVACFCRTLR_RwVltg2 "HVAC Front Controls Request Temperature Level Rear : Raw Voltage 2";
BA_ "SignalType" SG_ 1302 HVACFCRTLR_LtLvlActv "ENM";
BA_ "SignalLongName" SG_ 1302 HVACFCRTLR_LtLvlActv "HVAC Front Controls Request Temperature Level Rear : Left Level Active";
BA_ "SignalLongName" SG_ 1302 HVACFCRTLR_RtLvlChg "HVAC Front Controls Request Temperature Level Rear : Right Level Change";
BA_ "SignalLongName" SG_ 1302 HVACFCRTLR_RtLvl "HVAC Front Controls Request Temperature Level Rear : Right Level";
BA_ "SignalLongName" SG_ 1271 ADASIS_NAVILINK_SpdLmtPstdSpd "ADASIS NAVILINK Speed Limit Posted Speed";
BA_ "SignalLongName" SG_ 1271 ADASIS_NAVILINK_SpdLmtRcmdSpd "ADASIS NAVILINK Speed Limit Recommended Speed";
BA_ "SignalType" SG_ 1271 ADASIS_NAVILINK_FncRdClss "ENM";
BA_ "SignalLongName" SG_ 1271 ADASIS_NAVILINK_FncRdClss "ADASIS NAVILINK Functional Road Class";
BA_ "SignalType" SG_ 1271 ADASIS_NAVILINK_DigMpVerYr "ENM";
BA_ "SignalLongName" SG_ 1271 ADASIS_NAVILINK_DigMpVerYr "ADASIS NAVILINK Digital Map Version Year";
BA_ "SignalType" SG_ 1271 ADASIS_NAVILINK_SpdLmtUnt "ENM";
BA_ "SignalLongName" SG_ 1271 ADASIS_NAVILINK_SpdLmtUnt "ADASIS NAVILINK Speed Limit Unit";
BA_ "SignalType" SG_ 1271 ADASIS_NAVILINK_SpdLmtPsdSpd_DuD "ENM";
BA_ "SignalLongName" SG_ 1271 ADASIS_NAVILINK_SpdLmtPsdSpd_DuD "ADASIS NAVILINK Speed Limit Posted Speed Don't Use Data";
BA_ "SignalType" SG_ 1271 ADASIS_NAVILINK_MpDtAv "ENM";
BA_ "SignalLongName" SG_ 1271 ADASIS_NAVILINK_MpDtAv "ADASIS NAVILINK Map data availability";
BA_ "SignalType" SG_ 1271 ADASIS_NAVILINK_LnCtgry "ENM";
BA_ "SignalLongName" SG_ 1271 ADASIS_NAVILINK_LnCtgry "ADASIS NAVILINK Lane Category";
BA_ "SignalType" SG_ 1271 ADASIS_NAVILINK_DigMpVerQtr "ENM";
BA_ "SignalLongName" SG_ 1271 ADASIS_NAVILINK_DigMpVerQtr "ADASIS NAVILINK Digital Map Version Quarter";
BA_ "SignalType" SG_ 1271 ADASIS_NAVILINK_SprtdLnRd "ENM";
BA_ "SignalLongName" SG_ 1271 ADASIS_NAVILINK_SprtdLnRd "ADASIS NAVILINK Separated Lane Road";
BA_ "SignalLongName" SG_ 1376 VehIdNmDig1 "Vehicle Identification Number Digit 1";
BA_ "SignalType" SG_ 1399 VehStbEnhCurrStReq "ENM";
BA_ "SignalLongName" SG_ 1399 VehStbEnhCurrStReq "VehicleStabilityEnhancementCurrentStateRequest";
BA_ "SignalType" SG_ 1399 VehStbCompMdCurrStReq "ENM";
BA_ "SignalLongName" SG_ 1399 VehStbCompMdCurrStReq "VehicleStabilityCompetitiveModeCurrentStateRequest";
BA_ "SignalType" SG_ 1399 TCStmpDsblReqConf "ENM";
BA_ "SignalLongName" SG_ 1399 TCStmpDsblReqConf "TractionControlSystemTemporaryDisableRequestConfirmation";
BA_ "SignalType" SG_ 1399 TCSCurrStReq "ENM";
BA_ "SignalLongName" SG_ 1399 TCSCurrStReq "Traction Control System Current State Request";
BA_ "SignalType" SG_ 1398 CustMdActAeroCstChngSetReq "ENM";
BA_ "SignalLongName" SG_ 1398 CustMdActAeroCstChngSetReq "Custom Mode Active Aero Customization Change Setting Request";
BA_ "SignalType" SG_ 1398 CustmPT_CfgPgAct "ENM";
BA_ "SignalLongName" SG_ 1398 CustmPT_CfgPgAct "Custom Powertrain Configuration Page Active";
BA_ "SignalType" SG_ 1398 ExtdHillStrtAsstCstChgSetReq "ENM";
BA_ "SignalLongName" SG_ 1398 ExtdHillStrtAsstCstChgSetReq "Extended Hill Start Assist Customization Change Setting Request";
BA_ "SignalType" SG_ 1398 DrvrSeltdConf "ENM";
BA_ "SignalLongName" SG_ 1398 DrvrSeltdConf "Driver Selected Confirmation";
BA_ "SignalType" SG_ 1398 CustMdTrcStbCstChngSetReq "ENM";
BA_ "SignalLongName" SG_ 1398 CustMdTrcStbCstChngSetReq "Custom Mode Traction Stability Customization Change Setting Request";
BA_ "SignalType" SG_ 1398 CustMdPTCstChngSetReq "ENM";
BA_ "SignalLongName" SG_ 1398 CustMdPTCstChngSetReq "Custom Mode Powertrain Customization Change Setting Request";
BA_ "SignalType" SG_ 1398 CustMdBrkPdlCstChngSetReq "ENM";
BA_ "SignalLongName" SG_ 1398 CustMdBrkPdlCstChngSetReq "Custom Mode Brake Pedal Customization Change Setting Request";
BA_ "SignalLongName" SG_ 1375 BatVltOBD "Battery Voltage On Board Diagnostics";
BA_ "SignalType" SG_ 1375 BatVltOBD_Inv "ENM";
BA_ "SignalLongName" SG_ 1375 BatVltOBD_Inv "Battery Voltage On Board Diagnostics Invalid";
BA_ "SignalType" SG_ 1400 PTExPrtclFltrMnlRgnRq "ENM";
BA_ "SignalLongName" SG_ 1400 PTExPrtclFltrMnlRgnRq "Powertrain Exhaust Particle Filter Manual Regeneration Request";
BA_ "SignalType" SG_ 1400 CustmStbCtlRdctReqConf "ENM";
BA_ "SignalLongName" SG_ 1400 CustmStbCtlRdctReqConf "Custom Stability Control Reduction Request Confirmation";
BA_ "SignalType" SG_ 1383 OTARC_RejCrdntnECP_MC "ENM";
BA_ "SignalLongName" SG_ 1383 OTARC_RejCrdntnECP_MC "Over The Air Reject Coordination : Reject Coordination ECP_MC";
BA_ "SignalType" SG_ 1383 OTARC_RejCrdntnBSM_MH "ENM";
BA_ "SignalLongName" SG_ 1383 OTARC_RejCrdntnBSM_MH "Over The Air Reject Coordination : Reject Coordination BSM_MH";
BA_ "SignalType" SG_ 1383 OTARC_RejCrdntnECP_X2 "ENM";
BA_ "SignalLongName" SG_ 1383 OTARC_RejCrdntnECP_X2 "Over The Air Reject Coordination : Reject Coordination ECP_X2";
BA_ "SignalType" SG_ 1383 OTARC_RejCrdntnECP_X1 "ENM";
BA_ "SignalLongName" SG_ 1383 OTARC_RejCrdntnECP_X1 "Over The Air Reject Coordination : Reject Coordination ECP_X1";
BA_ "SignalType" SG_ 1383 OTARC_RejCrdntnECM "ENM";
BA_ "SignalLongName" SG_ 1383 OTARC_RejCrdntnECM "Over The Air Reject Coordination : Reject Coordination ECM";
BA_ "SignalType" SG_ 1383 OTARC_RejCrdntnEBCM "ENM";
BA_ "SignalLongName" SG_ 1383 OTARC_RejCrdntnEBCM "Over The Air Reject Coordination : Reject Coordination EBCM";
BA_ "SignalType" SG_ 1383 OTARC_RejCrdntnBSM "ENM";
BA_ "SignalLongName" SG_ 1383 OTARC_RejCrdntnBSM "Over The Air Reject Coordination : Reject Coordination BSM";
BA_ "SignalType" SG_ 1383 OTARC_RejCrdntnBCM "ENM";
BA_ "SignalLongName" SG_ 1383 OTARC_RejCrdntnBCM "Over The Air Reject Coordination : Reject Coordination BCM";
BA_ "SignalType" SG_ 1383 OTARC_RejCrdntnECU_19 "ENM";
BA_ "SignalLongName" SG_ 1383 OTARC_RejCrdntnECU_19 "Over The Air Reject Coordination : Reject Coordination ECU_19";
BA_ "SignalType" SG_ 1383 OTARC_RejCrdntnECU_18 "ENM";
BA_ "SignalLongName" SG_ 1383 OTARC_RejCrdntnECU_18 "Over The Air Reject Coordination : Reject Coordination ECU_18";
BA_ "SignalType" SG_ 1383 OTARC_RejCrdntnECU_17 "ENM";
BA_ "SignalLongName" SG_ 1383 OTARC_RejCrdntnECU_17 "Over The Air Reject Coordination : Reject Coordination ECU_17";
BA_ "SignalType" SG_ 1383 OTARC_RejCrdntnECU_16 "ENM";
BA_ "SignalLongName" SG_ 1383 OTARC_RejCrdntnECU_16 "Over The Air Reject Coordination : Reject Coordination ECU_16";
BA_ "SignalType" SG_ 1383 OTARC_RejCrdntnECU_15 "ENM";
BA_ "SignalLongName" SG_ 1383 OTARC_RejCrdntnECU_15 "Over The Air Reject Coordination : Reject Coordination ECU_15";
BA_ "SignalType" SG_ 1383 OTARC_RejCrdntnECU_14 "ENM";
BA_ "SignalLongName" SG_ 1383 OTARC_RejCrdntnECU_14 "Over The Air Reject Coordination : Reject Coordination ECU_14";
BA_ "SignalType" SG_ 1383 OTARC_RejCrdntnECU_13 "ENM";
BA_ "SignalLongName" SG_ 1383 OTARC_RejCrdntnECU_13 "Over The Air Reject Coordination : Reject Coordination ECU_13";
BA_ "SignalType" SG_ 1383 OTARC_RejCrdntnECP_S "ENM";
BA_ "SignalLongName" SG_ 1383 OTARC_RejCrdntnECP_S "Over The Air Reject Coordination : Reject Coordination ECP_S";
BA_ "SignalType" SG_ 1383 OTARC_RejCrdntnECU_27 "ENM";
BA_ "SignalLongName" SG_ 1383 OTARC_RejCrdntnECU_27 "Over The Air Reject Coordination : Reject Coordination ECU_27";
BA_ "SignalType" SG_ 1383 OTARC_RejCrdntnECU_26 "ENM";
BA_ "SignalLongName" SG_ 1383 OTARC_RejCrdntnECU_26 "Over The Air Reject Coordination : Reject Coordination ECU_26";
BA_ "SignalType" SG_ 1383 OTARC_RejCrdntnECU_25 "ENM";
BA_ "SignalLongName" SG_ 1383 OTARC_RejCrdntnECU_25 "Over The Air Reject Coordination : Reject Coordination ECU_25";
BA_ "SignalType" SG_ 1383 OTARC_RejCrdntnECU_24 "ENM";
BA_ "SignalLongName" SG_ 1383 OTARC_RejCrdntnECU_24 "Over The Air Reject Coordination : Reject Coordination ECU_24";
BA_ "SignalType" SG_ 1383 OTARC_RejCrdntnECU_23 "ENM";
BA_ "SignalLongName" SG_ 1383 OTARC_RejCrdntnECU_23 "Over The Air Reject Coordination : Reject Coordination ECU_23";
BA_ "SignalType" SG_ 1383 OTARC_RejCrdntnECU_22 "ENM";
BA_ "SignalLongName" SG_ 1383 OTARC_RejCrdntnECU_22 "Over The Air Reject Coordination : Reject Coordination ECU_22";
BA_ "SignalType" SG_ 1383 OTARC_RejCrdntnECU_21 "ENM";
BA_ "SignalLongName" SG_ 1383 OTARC_RejCrdntnECU_21 "Over The Air Reject Coordination : Reject Coordination ECU_21";
BA_ "SignalType" SG_ 1383 OTARC_RejCrdntnECU_20 "ENM";
BA_ "SignalLongName" SG_ 1383 OTARC_RejCrdntnECU_20 "Over The Air Reject Coordination : Reject Coordination ECU_20";
BA_ "SignalType" SG_ 1383 OTARC_RejCrdntnTCM "ENM";
BA_ "SignalLongName" SG_ 1383 OTARC_RejCrdntnTCM "Over The Air Reject Coordination : Reject Coordination TCM";
BA_ "SignalType" SG_ 1383 OTARC_RejCrdntnICCM "ENM";
BA_ "SignalLongName" SG_ 1383 OTARC_RejCrdntnICCM "Over The Air Reject Coordination : Reject Coordination ICCM";
BA_ "SignalType" SG_ 1383 OTARC_RejCrdntnFICM "ENM";
BA_ "SignalLongName" SG_ 1383 OTARC_RejCrdntnFICM "Over The Air Reject Coordination : Reject Coordination FICM";
BA_ "SignalType" SG_ 1383 OTARC_RejCrdntnECU_32 "ENM";
BA_ "SignalLongName" SG_ 1383 OTARC_RejCrdntnECU_32 "Over The Air Reject Coordination : Reject Coordination ECU_32";
BA_ "SignalType" SG_ 1383 OTARC_RejCrdntnECU_31 "ENM";
BA_ "SignalLongName" SG_ 1383 OTARC_RejCrdntnECU_31 "Over The Air Reject Coordination : Reject Coordination ECU_31";
BA_ "SignalType" SG_ 1383 OTARC_RejCrdntnECU_30 "ENM";
BA_ "SignalLongName" SG_ 1383 OTARC_RejCrdntnECU_30 "Over The Air Reject Coordination : Reject Coordination ECU_30";
BA_ "SignalType" SG_ 1383 OTARC_RejCrdntnECU_29 "ENM";
BA_ "SignalLongName" SG_ 1383 OTARC_RejCrdntnECU_29 "Over The Air Reject Coordination : Reject Coordination ECU_29";
BA_ "SignalType" SG_ 1383 OTARC_RejCrdntnECU_28 "ENM";
BA_ "SignalLongName" SG_ 1383 OTARC_RejCrdntnECU_28 "Over The Air Reject Coordination : Reject Coordination ECU_28";
BA_ "SignalLongName" SG_ 514 PrplDispEngPwr "Propulsion Display Engine Power";
BA_ "SignalLongName" SG_ 1080 HMIGenInfo1_PCSM "HMI General Information 1 Protected Counter Sync Message";
BA_ "SignalLongName" SG_ 1077 HMIGI1P_MAC "HMI General Information 1 Protected : MAC";
BA_ "SignalLongName" SG_ 1077 HMIGI1P_FCnt "HMI General Information 1 Protected : Freshness Counter";
BA_ "SignalLongName" SG_ 1077 HMIGI1P_ARC "HMI General Information 1 Protected : Alive Rolling Count";
BA_ "SignalType" SG_ 1077 HMIGI1P_TrlrBrkDispActvAuth "ENM";
BA_ "SignalLongName" SG_ 1077 HMIGI1P_TrlrBrkDispActvAuth "HMI General Information 1 Protected : Trailer Brake Display Active Authenticated";
BA_ "SignalType" SG_ 1077 HMIGI1P_TrlrBrkDispActvAuth_DuD "ENM";
BA_ "SignalLongName" SG_ 1077 HMIGI1P_TrlrBrkDispActvAuth_DuD "HMI General Information 1 Protected : Trailer Brake Display Active Authenticated Don't Use Data";
BA_ "SignalType" SG_ 1077 HMIGI1P_EnvModPrsntRspdr4Auth "ENM";
BA_ "SignalLongName" SG_ 1077 HMIGI1P_EnvModPrsntRspdr4Auth "HMI General Information 1 Protected : Environment Module Present Responder #4 Authenticated";
BA_ "SignalLongName" SG_ 1421 HMIGenInfo2_PCSM "HMI General Information 2 Protected Counter Sync Message";
BA_ "SignalLongName" SG_ 623 HMIGI2P_MAC "HMI General Information 2 Protected : MAC";
BA_ "SignalLongName" SG_ 623 HMIGI2P_FCnt "HMI General Information 2 Protected : Freshness Counter";
BA_ "SignalLongName" SG_ 623 HMIGI2P_ARC "HMI General Information 2 Protected : Alive Rolling Count";
BA_ "SignalType" SG_ 623 HMIGI2P_LnFllwgInterFltDtdAuth "ENM";
BA_ "SignalLongName" SG_ 623 HMIGI2P_LnFllwgInterFltDtdAuth "HMI General Information 2 Protected : Lane Following Interface Fault Detected Authenticated";
BA_ "SignalType" SG_ 623 HMIGI2P_IPCFlrIndOnAuth "ENM";
BA_ "SignalLongName" SG_ 623 HMIGI2P_IPCFlrIndOnAuth "HMI General Information 2 Protected : Instrument Panel Cluster Failure Indication On Authenticated";
BA_ "SignalLongName" SG_ 1081 HMIInds1_PCSM "HMI Indications 1 Protected Counter Sync Message";
BA_ "SignalLongName" SG_ 1078 HMII1P_MAC "HMI Indications 1 Protected : MAC";
BA_ "SignalLongName" SG_ 1078 HMII1P_FCnt "HMI Indications 1 Protected : Freshness Counter";
BA_ "SignalType" SG_ 1078 HMII1P_ACCSetTypAuth "ENM";
BA_ "SignalLongName" SG_ 1078 HMII1P_ACCSetTypAuth "HMI Indications 1 Protected : Adaptive Cruise Control Setting Type Authenticated";
BA_ "SignalType" SG_ 1078 HMII1P_AutoModeSpdLimCnfrmdAuth "ENM";
BA_ "SignalLongName" SG_ 1078 HMII1P_AutoModeSpdLimCnfrmdAuth "HMI Indications 1 Protected : Auto Mode Speed Limit Confirmed Authenticated";
BA_ "SignalType" SG_ 1078 HMII1P_ChmSysSOHAuth "ENM";
BA_ "SignalLongName" SG_ 1078 HMII1P_ChmSysSOHAuth "HMI Indications 1 Protected : Chime System State of Health Authenticated";
BA_ "SignalType" SG_ 1078 HMII1P_LnFllwgChInterFltDtdAuth "ENM";
BA_ "SignalLongName" SG_ 1078 HMII1P_LnFllwgChInterFltDtdAuth "HMI Indications 1 Protected : Lane Following Chime Interface Fault Detected Authenticated";
BA_ "SignalType" SG_ 1078 HMII1P_MCRLDOprtlStsAuth "ENM";
BA_ "SignalLongName" SG_ 1078 HMII1P_MCRLDOprtlStsAuth "HMI Indications 1 Protected : Multi Color Reflective Light Display Operational Status Authenticated";
BA_ "SignalType" SG_ 1078 HMII1P_IPCDispStsAuth "ENM";
BA_ "SignalLongName" SG_ 1078 HMII1P_IPCDispStsAuth "HMI Indications 1 Protected : IPC Display Status Authenticated";
BA_ "SignalLongName" SG_ 1078 HMII1P_ARC "HMI Indications 1 Protected : Alive Rolling Count";
BA_ "SignalLongName" SG_ 1064 HMIReqs1_PCSM "HMI Requests 1 Protected Counter Sync Message";
BA_ "SignalLongName" SG_ 1059 HMIR1P_MAC "HMI Requests 1 Protected : MAC";
BA_ "SignalLongName" SG_ 1059 HMIR1P_Fcnt "HMI Requests 1 Protected : Freshness Counter";
BA_ "SignalType" SG_ 1059 HMIR1P_MCRLDAnmProfReqAuth "ENM";
BA_ "SignalLongName" SG_ 1059 HMIR1P_MCRLDAnmProfReqAuth "HMI Requests 1 Protected : Multi Color Reflective Light Display Animation Profile Request Authenticated";
BA_ "SignalType" SG_ 1059 HMIR1P_LnFllwgRHSChEvntStatAuth "ENM";
BA_ "SignalLongName" SG_ 1059 HMIR1P_LnFllwgRHSChEvntStatAuth "HMI Requests 1 Protected : Lane Following Right Hand Side Chime Event State Authenticated";
BA_ "SignalType" SG_ 1059 HMIR1P_MCRLDAnmProfReqAuth_Inv "ENM";
BA_ "SignalLongName" SG_ 1059 HMIR1P_MCRLDAnmProfReqAuth_Inv "HMI Requests 1 Protected : Multi Color Reflective Light Display Animation Profile Request Authenticated Invalid";
BA_ "SignalType" SG_ 1059 HMIR1P_MCRLDAnmProfReqAuth_DuD "ENM";
BA_ "SignalLongName" SG_ 1059 HMIR1P_MCRLDAnmProfReqAuth_DuD "HMI Requests 1 Protected : Multi Color Reflective Light Display Animation Profile Request Authenticated Don't Use Data";
BA_ "SignalLongName" SG_ 1059 HMIR1P_ARC "HMI Requests 1 Protected : Alive Rolling Count";
BA_ "SignalType" SG_ 1059 HMIR1P_LnFllwgLHSChEvntStatAuth "ENM";
BA_ "SignalLongName" SG_ 1059 HMIR1P_LnFllwgLHSChEvntStatAuth "HMI Requests 1 Protected : Lane Following Left Hand Side Chime Event State Authenticated";
BA_ "SignalType" SG_ 1059 HMIR1P_LnFllwgGenChEvntStatAuth "ENM";
BA_ "SignalLongName" SG_ 1059 HMIR1P_LnFllwgGenChEvntStatAuth "HMI Requests 1 Protected : Lane Following General Chime Event State Authenticated";
BA_ "SignalLongName" SG_ 1364 HVACFCRBLF_RwVltg "HVAC Front Controls Request Blower Level Front : Raw Voltage";
BA_ "SignalType" SG_ 1364 HVACFCRBLF_LvlActv "ENM";
BA_ "SignalLongName" SG_ 1364 HVACFCRBLF_LvlActv "HVAC Front Controls Request Blower Level Front : Level Active";
BA_ "SignalLongName" SG_ 1364 HVACFCRBLF_Lvl "HVAC Front Controls Request Blower Level Front : Level";
BA_ "SignalLongName" SG_ 1364 HVACFCRBLF_CS "HVAC Front Controls Request Blower Level Front : Checksum";
BA_ "SignalLongName" SG_ 1364 HVACFCRBLF_ARC "HVAC Front Controls Request Blower Level Front : Alive Rolling Count";
BA_ "SignalLongName" SG_ 185 HVACFCRTLCFLI2_ORX4 "HVAC Front Controls Request Temperature Level Change Front Left Information 2 : Out of Range X4";
BA_ "SignalType" SG_ 185 HVACFCRTLCFLI2_ORL4 "ENM";
BA_ "SignalLongName" SG_ 185 HVACFCRTLCFLI2_ORL4 "HVAC Front Controls Request Temperature Level Change Front Left Information 2 : Out of Range Low 4";
BA_ "SignalType" SG_ 185 HVACFCRTLCFLI2_ORH4 "ENM";
BA_ "SignalLongName" SG_ 185 HVACFCRTLCFLI2_ORH4 "HVAC Front Controls Request Temperature Level Change Front Left Information 2 : Out of Range High 4";
BA_ "SignalLongName" SG_ 185 HVACFCRTLCFLI2_ORY4 "HVAC Front Controls Request Temperature Level Change Front Left Information 2 : Out of Range Y4";
BA_ "SignalLongName" SG_ 185 HVACFCRTLCFLI2_RwVltg4 "HVAC Front Controls Request Temperature Level Change Front Left Information 2 : Raw Voltage 4";
BA_ "SignalLongName" SG_ 185 HVACFCRTLCFLI2_CS "HVAC Front Controls Request Temperature Level Change Front Left Information 2 : Checksum";
BA_ "SignalLongName" SG_ 185 HVACFCRTLCFLI2_ARC "HVAC Front Controls Request Temperature Level Change Front Left Information 2 : Alive Rolling Count";
BA_ "SignalLongName" SG_ 186 HVACFCRTLCFRI2_ORX4 "HVAC Front Controls Request Temperature Level Change Front Right Information 2 : Out of Range X4";
BA_ "SignalType" SG_ 186 HVACFCRTLCFRI2_ORL4 "ENM";
BA_ "SignalLongName" SG_ 186 HVACFCRTLCFRI2_ORL4 "HVAC Front Controls Request Temperature Level Change Front Right Information 2 : Out of Range Low 4";
BA_ "SignalType" SG_ 186 HVACFCRTLCFRI2_ORH4 "ENM";
BA_ "SignalLongName" SG_ 186 HVACFCRTLCFRI2_ORH4 "HVAC Front Controls Request Temperature Level Change Front Right Information 2 : Out of Range High 4";
BA_ "SignalLongName" SG_ 186 HVACFCRTLCFRI2_ORY4 "HVAC Front Controls Request Temperature Level Change Front Right Information 2 : Out of Range Y4";
BA_ "SignalLongName" SG_ 186 HVACFCRTLCFRI2_RwVltg4 "HVAC Front Controls Request Temperature Level Change Front Right Information 2 : Raw Voltage 4";
BA_ "SignalLongName" SG_ 186 HVACFCRTLCFRI2_CS "HVAC Front Controls Request Temperature Level Change Front Right Information 2 : Checksum";
BA_ "SignalLongName" SG_ 186 HVACFCRTLCFRI2_ARC "HVAC Front Controls Request Temperature Level Change Front Right Information 2 : Alive Rolling Count";
BA_ "SignalType" SG_ 1358 HVACICR1_IntrnlFltSts "ENM";
BA_ "SignalLongName" SG_ 1358 HVACICR1_IntrnlFltSts "HVAC Infotainment Controls Request 1 : Internal Fault Status";
BA_ "SignalType" SG_ 1358 HVACICR1_FrtAutoSetChg "ENM";
BA_ "SignalLongName" SG_ 1358 HVACICR1_FrtAutoSetChg "HVAC Infotainment Controls Request 1 : Front Auto Setting Change";
BA_ "SignalType" SG_ 1358 HVACICR1_FrtPwrSetChg "ENM";
BA_ "SignalLongName" SG_ 1358 HVACICR1_FrtPwrSetChg "HVAC Infotainment Controls Request 1 : Front Power Setting Change";
BA_ "SignalType" SG_ 1358 HVACICR1_HtrSet "ENM";
BA_ "SignalLongName" SG_ 1358 HVACICR1_HtrSet "HVAC Infotainment Controls Request 1 : Heater Setting";
BA_ "SignalType" SG_ 1358 HVACICR1_CompSetChg "ENM";
BA_ "SignalLongName" SG_ 1358 HVACICR1_CompSetChg "HVAC Infotainment Controls Request 1 : Compressor Setting Change";
BA_ "SignalType" SG_ 1358 HVACICR1_CompSet "ENM";
BA_ "SignalLongName" SG_ 1358 HVACICR1_CompSet "HVAC Infotainment Controls Request 1 : Compressor Setting";
BA_ "SignalLongName" SG_ 1358 HVACICR1_BlwLvlChgFrt "HVAC Infotainment Controls Request 1 : Blower Level Change Front";
BA_ "SignalLongName" SG_ 1358 HVACICR1_BlwLvlFrt "HVAC Infotainment Controls Request 1 : Blower Level Front";
BA_ "SignalType" SG_ 1358 HVACICR1_MaxDefrSetChg "ENM";
BA_ "SignalLongName" SG_ 1358 HVACICR1_MaxDefrSetChg "HVAC Infotainment Controls Request 1 : Max Defrost Setting Change";
BA_ "SignalType" SG_ 1358 HVACICR1_MaxDefrSet "ENM";
BA_ "SignalLongName" SG_ 1358 HVACICR1_MaxDefrSet "HVAC Infotainment Controls Request 1 : Max Defrost Setting";
BA_ "SignalType" SG_ 1358 HVACICR1_HtrSetChg "ENM";
BA_ "SignalLongName" SG_ 1358 HVACICR1_HtrSetChg "HVAC Infotainment Controls Request 1 : Heater Setting Change";
BA_ "SignalType" SG_ 1358 HVACICR1_FrtRrPwrSet "ENM";
BA_ "SignalLongName" SG_ 1358 HVACICR1_FrtRrPwrSet "HVAC Infotainment Controls Request 1 : Front and Rear Power Setting";
BA_ "SignalType" SG_ 1358 HVACICR1_BlwLvlFrtActv "ENM";
BA_ "SignalLongName" SG_ 1358 HVACICR1_BlwLvlFrtActv "HVAC Infotainment Controls Request 1 : Blower Level Front Active";
BA_ "SignalLongName" SG_ 1358 HVACICR1_CS "HVAC Infotainment Controls Request 1 : Checksum";
BA_ "SignalLongName" SG_ 1358 HVACICR1_ARC "HVAC Infotainment Controls Request 1 : Alive Rolling Count";
BA_ "SignalLongName" SG_ 1359 HVACICR2_TempLtLvl "HVAC Infotainment Controls Request 2 : Temperature Left Level";
BA_ "SignalLongName" SG_ 1359 HVACICR2_TempLtLvlChg "HVAC Infotainment Controls Request 2 : Temperature Left Level Change";
BA_ "SignalType" SG_ 1359 HVACICR2_AirDstRtSet "ENM";
BA_ "SignalLongName" SG_ 1359 HVACICR2_AirDstRtSet "HVAC Infotainment Controls Request 2 : Air Distribution Right Setting";
BA_ "SignalLongName" SG_ 1359 HVACICR2_TempRtLvl "HVAC Infotainment Controls Request 2 : Temperature Right Level";
BA_ "SignalType" SG_ 1359 HVACICR2_AirDstLtSet "ENM";
BA_ "SignalLongName" SG_ 1359 HVACICR2_AirDstLtSet "HVAC Infotainment Controls Request 2 : Air Distribution Left Setting";
BA_ "SignalType" SG_ 1359 HVACICR2_RecircSet "ENM";
BA_ "SignalLongName" SG_ 1359 HVACICR2_RecircSet "HVAC Infotainment Controls Request 2 : Recirculation Setting";
BA_ "SignalType" SG_ 1359 HVACICR2_AirDstLtChgPrev "ENM";
BA_ "SignalLongName" SG_ 1359 HVACICR2_AirDstLtChgPrev "HVAC Infotainment Controls Request 2 : Air Distribution Left Change Previous";
BA_ "SignalType" SG_ 1359 HVACICR2_AirDstLtChgNext "ENM";
BA_ "SignalLongName" SG_ 1359 HVACICR2_AirDstLtChgNext "HVAC Infotainment Controls Request 2 : Air Distribution Left Change Next";
BA_ "SignalType" SG_ 1359 HVACICR2_TempLtLvlActv "ENM";
BA_ "SignalLongName" SG_ 1359 HVACICR2_TempLtLvlActv "HVAC Infotainment Controls Request 2 : Temperature Left Level Active";
BA_ "SignalType" SG_ 1359 HVACICR2_AirDstRtChgNext "ENM";
BA_ "SignalLongName" SG_ 1359 HVACICR2_AirDstRtChgNext "HVAC Infotainment Controls Request 2 : Air Distribution Right Change Next";
BA_ "SignalType" SG_ 1359 HVACICR2_TempRtLvlActv "ENM";
BA_ "SignalLongName" SG_ 1359 HVACICR2_TempRtLvlActv "HVAC Infotainment Controls Request 2 : Temperature Right Level Active";
BA_ "SignalType" SG_ 1359 HVACICR2_RecircSetChg "ENM";
BA_ "SignalLongName" SG_ 1359 HVACICR2_RecircSetChg "HVAC Infotainment Controls Request 2 : Recirculation Setting Change";
BA_ "SignalLongName" SG_ 1359 HVACICR2_TempRtLvlChg "HVAC Infotainment Controls Request 2 : Temperature Right Level Change";
BA_ "SignalType" SG_ 1359 HVACICR2_AirDstRtChgPrev "ENM";
BA_ "SignalLongName" SG_ 1359 HVACICR2_AirDstRtChgPrev "HVAC Infotainment Controls Request 2 : Air Distribution Right Change Previous";
BA_ "SignalLongName" SG_ 1359 HVACICR2_CS "HVAC Infotainment Controls Request 2 : Checksum";
BA_ "SignalLongName" SG_ 1359 HVACICR2_ARC "HVAC Infotainment Controls Request 2 : Alive Rolling Count";
BA_ "SignalLongName" SG_ 1303 HVACFCRADR_RwVltg1 "HVAC Front Controls Request Air Distribution Rear : Raw Voltage 1";
BA_ "SignalType" SG_ 1303 ReqRrClmtApp "ENM";
BA_ "SignalLongName" SG_ 1303 ReqRrClmtApp "Request Rear Climate App";
BA_ "SignalType" SG_ 1303 ReqFrtClmtApp "ENM";
BA_ "SignalLongName" SG_ 1303 ReqFrtClmtApp "Request Front Climate App";
BA_ "SignalType" SG_ 1303 HVACFCRADR_LtChgNext "ENM";
BA_ "SignalLongName" SG_ 1303 HVACFCRADR_LtChgNext "HVAC Front Controls Request Air Distribution Rear : Left Change Next";
BA_ "SignalType" SG_ 1303 HVACFCRADR_RtSet "ENM";
BA_ "SignalLongName" SG_ 1303 HVACFCRADR_RtSet "HVAC Front Controls Request Air Distribution Rear : Right Setting";
BA_ "SignalLongName" SG_ 1303 HVACFCRADR_RwVltg2 "HVAC Front Controls Request Air Distribution Rear : Raw Voltage 2";
BA_ "SignalType" SG_ 1303 HVACFCRADR_RtChgNext "ENM";
BA_ "SignalLongName" SG_ 1303 HVACFCRADR_RtChgNext "HVAC Front Controls Request Air Distribution Rear : Right Change Next";
BA_ "SignalLongName" SG_ 1303 HVACFCRRA_RwVltg "HVAC Front Controls Request Rear Auto : Raw Voltage";
BA_ "SignalType" SG_ 1303 HVACFCRRA_SetChg "ENM";
BA_ "SignalLongName" SG_ 1303 HVACFCRRA_SetChg "HVAC Front Controls Request Rear Auto : Setting Change";
BA_ "SignalType" SG_ 1303 HVACFCRADR_LtSet "ENM";
BA_ "SignalLongName" SG_ 1303 HVACFCRADR_LtSet "HVAC Front Controls Request Air Distribution Rear : Left Setting";
BA_ "SignalLongName" SG_ 1303 HVACFCRRD_RwVltg "HVAC Front Controls Request Rear Defog : Raw Voltage";
BA_ "SignalType" SG_ 1303 HVACFCRRD_SetChg "ENM";
BA_ "SignalLongName" SG_ 1303 HVACFCRRD_SetChg "HVAC Front Controls Request Rear Defog : Setting Change";
BA_ "SignalLongName" SG_ 1303 HVACFCRRP_RwVltg "HVAC Front Controls Request Rear Power : Raw Voltage";
BA_ "SignalType" SG_ 1303 HVACFCRRP_SetChg "ENM";
BA_ "SignalLongName" SG_ 1303 HVACFCRRP_SetChg "HVAC Front Controls Request Rear Power : Setting Change";
BA_ "SignalLongName" SG_ 1354 HVACFCRSA_RwVltg "HVAC Front Controls Request Sync All : Raw Voltage";
BA_ "SignalType" SG_ 1354 HVACFCRSA_SetChg "ENM";
BA_ "SignalLongName" SG_ 1354 HVACFCRSA_SetChg "HVAC Front Controls Request Sync All : Setting Change";
BA_ "SignalType" SG_ 1352 HtdStrgWhlSwActv_HVAC_FP_F "ENM";
BA_ "SignalLongName" SG_ 1352 HtdStrgWhlSwActv_HVAC_FP_F "Heated Steering Wheel Switch Active HVAC Front Faceplate";
BA_ "SignalType" SG_ 1352 ManHtdStrgWhlReqd_HVAC_FP_F "ENM";
BA_ "SignalLongName" SG_ 1352 ManHtdStrgWhlReqd_HVAC_FP_F "Manual Heated Steering Wheel Requested HVAC Front Faceplate";
BA_ "SignalType" SG_ 1352 ManHtdStrgWhlReqd_HVAC_FP_F_Inv "ENM";
BA_ "SignalLongName" SG_ 1352 ManHtdStrgWhlReqd_HVAC_FP_F_Inv "Manual Heated Steering Wheel Requested HVAC Front Faceplate Invalid";
BA_ "SignalType" SG_ 1352 HtdStrgWhlStkSw_HVAC_FP_F "ENM";
BA_ "SignalLongName" SG_ 1352 HtdStrgWhlStkSw_HVAC_FP_F "Heated Steering Wheel Stuck Switch HVAC Front Faceplate";
BA_ "SignalType" SG_ 1352 HtdStrgWhlStkSw_HVAC_FP_F_Inv "ENM";
BA_ "SignalLongName" SG_ 1352 HtdStrgWhlStkSw_HVAC_FP_F_Inv "Heated Steering Wheel Stuck Switch HVAC Front Faceplate Invalid";
BA_ "SignalType" SG_ 1397 RHVSRR_HtdBckLvlChgUp "ENM";
BA_ "SignalLongName" SG_ 1397 RHVSRR_HtdBckLvlChgUp "Request Heated Vented Seat Right Rear : Heated Back Level Change Up";
BA_ "SignalType" SG_ 1397 RHVSRR_HtdBckLvlChgDn "ENM";
BA_ "SignalLongName" SG_ 1397 RHVSRR_HtdBckLvlChgDn "Request Heated Vented Seat Right Rear : Heated Back Level Change Down";
BA_ "SignalType" SG_ 1397 RHVSLR_VntLvlChgUp "ENM";
BA_ "SignalLongName" SG_ 1397 RHVSLR_VntLvlChgUp "Request Heated Vented Seat Left Rear : Vented Level Change Up";
BA_ "SignalType" SG_ 1397 RHVSLR_VntLvlChgDn "ENM";
BA_ "SignalLongName" SG_ 1397 RHVSLR_VntLvlChgDn "Request Heated Vented Seat Left Rear : Vented Level Change Down";
BA_ "SignalType" SG_ 1397 RHVSLR_HtdCushBckLvlChgUp "ENM";
BA_ "SignalLongName" SG_ 1397 RHVSLR_HtdCushBckLvlChgUp "Request Heated Vented Seat Left Rear : Heated Cushion and Back Level Change Up";
BA_ "SignalType" SG_ 1397 RHVSLR_HtdCushBckLvlChgDn "ENM";
BA_ "SignalLongName" SG_ 1397 RHVSLR_HtdCushBckLvlChgDn "Request Heated Vented Seat Left Rear : Heated Cushion and Back Level Change Down";
BA_ "SignalType" SG_ 1397 RHVSLR_HtdBckLvlChgUp "ENM";
BA_ "SignalLongName" SG_ 1397 RHVSLR_HtdBckLvlChgUp "Request Heated Vented Seat Left Rear : Heated Back Level Change Up";
BA_ "SignalType" SG_ 1397 RHVSLR_HtdBckLvlChgDn "ENM";
BA_ "SignalLongName" SG_ 1397 RHVSLR_HtdBckLvlChgDn "Request Heated Vented Seat Left Rear : Heated Back Level Change Down";
BA_ "SignalType" SG_ 1397 HtdStBckStckSwRR "ENM";
BA_ "SignalLongName" SG_ 1397 HtdStBckStckSwRR "Heated Seat Back Stuck Switch Right Rear";
BA_ "SignalType" SG_ 1397 HtdStBckStckSwLR "ENM";
BA_ "SignalLongName" SG_ 1397 HtdStBckStckSwLR "Heated Seat Back Stuck Switch Left Rear";
BA_ "SignalType" SG_ 1397 HtdStBckCushStckSwRR "ENM";
BA_ "SignalLongName" SG_ 1397 HtdStBckCushStckSwRR "Heated Seat Back and Cushion Stuck Switch Right Rear";
BA_ "SignalType" SG_ 1397 HtdStBckCushStckSwLR "ENM";
BA_ "SignalLongName" SG_ 1397 HtdStBckCushStckSwLR "Heated Seat Back and Cushion Stuck Switch Left Rear";
BA_ "SignalType" SG_ 1397 RHVSRR_VntLvlChgUp "ENM";
BA_ "SignalLongName" SG_ 1397 RHVSRR_VntLvlChgUp "Request Heated Vented Seat Right Rear : Vented Level Change Up";
BA_ "SignalType" SG_ 1397 RHVSRR_VntLvlChgDn "ENM";
BA_ "SignalLongName" SG_ 1397 RHVSRR_VntLvlChgDn "Request Heated Vented Seat Right Rear : Vented Level Change Down";
BA_ "SignalType" SG_ 1397 RHVSRR_HtdCushBckLvlChgUp "ENM";
BA_ "SignalLongName" SG_ 1397 RHVSRR_HtdCushBckLvlChgUp "Request Heated Vented Seat Right Rear : Heated Cushion and Back Level Change Up";
BA_ "SignalType" SG_ 1397 RHVSRR_HtdCushBckLvlChgDn "ENM";
BA_ "SignalLongName" SG_ 1397 RHVSRR_HtdCushBckLvlChgDn "Request Heated Vented Seat Right Rear : Heated Cushion and Back Level Change Down";
BA_ "SignalType" SG_ 1397 VntStStckSwRR "ENM";
BA_ "SignalLongName" SG_ 1397 VntStStckSwRR "Vented Seat Stuck Switch Right Rear";
BA_ "SignalType" SG_ 1397 VntStStckSwLR "ENM";
BA_ "SignalLongName" SG_ 1397 VntStStckSwLR "Vented Seat Stuck Switch Left Rear";
BA_ "SignalType" SG_ 1397 HtdVntStSwActvRR "ENM";
BA_ "SignalLongName" SG_ 1397 HtdVntStSwActvRR "Heated Vented Seat Switch Active Right Rear";
BA_ "SignalType" SG_ 1397 HtdVntStSwActvLR "ENM";
BA_ "SignalLongName" SG_ 1397 HtdVntStSwActvLR "Heated Vented Seat Switch Active Left Rear";
BA_ "SignalLongName" SG_ 1310 FCSS1_FrtCntrStckSldr1Pos "Front Center Stack Slider 1 : Front Center Stack Slider 1 Position";
BA_ "SignalType" SG_ 1310 FCSS1_FrtCntrStckSldr1Prxmty "ENM";
BA_ "SignalLongName" SG_ 1310 FCSS1_FrtCntrStckSldr1Prxmty "Front Center Stack Slider 1 : Front Center Stack Slider 1 Proximity";
BA_ "SignalLongName" SG_ 1310 FCSS2_FrtCntrStckSldr2Pos "Front Center Stack Slider 2 : Front Center Stack Slider 2 Position";
BA_ "SignalType" SG_ 1310 FCSS2_FrtCntrStckSldr2Prxmty "ENM";
BA_ "SignalLongName" SG_ 1310 FCSS2_FrtCntrStckSldr2Prxmty "Front Center Stack Slider 2 : Front Center Stack Slider 2 Proximity";
BA_ "SignalType" SG_ 1310 FCSS3_FrtCntrStckSldr3Prxmty "ENM";
BA_ "SignalLongName" SG_ 1310 FCSS3_FrtCntrStckSldr3Prxmty "Front Center Stack Slider 3 : Front Center Stack Slider 3 Proximity";
BA_ "SignalLongName" SG_ 1310 FCSS3_FrtCntrStckSldr3Pos "Front Center Stack Slider 3 : Front Center Stack Slider 3 Position";
BA_ "SignalLongName" SG_ 1311 FCSTP34_FrtCntrStckTmStmp34 "Front Center Stack Touch Position 34 : Front Center Stack Time Stamp 34";
BA_ "SignalLongName" SG_ 1311 FCSTP34_FrtCntrStckTchPosY4 "Front Center Stack Touch Position 34 : Front Center Stack Touch Position Y4";
BA_ "SignalLongName" SG_ 1311 FCSTP34_FrtCntrStckTchPosY3 "Front Center Stack Touch Position 34 : Front Center Stack Touch Position Y3";
BA_ "SignalLongName" SG_ 1311 FCSTP34_FrtCntrStckTchPosX4 "Front Center Stack Touch Position 34 : Front Center Stack Touch Position X4";
BA_ "SignalType" SG_ 1311 FCSTP34_FrtCntrStckTchFlg3 "ENM";
BA_ "SignalLongName" SG_ 1311 FCSTP34_FrtCntrStckTchFlg3 "Front Center Stack Touch Position 34 : Front Center Stack Touch Flag 3";
BA_ "SignalLongName" SG_ 1311 FCSTP34_FrtCntrStckTchPosX3 "Front Center Stack Touch Position 34 : Front Center Stack Touch Position X3";
BA_ "SignalType" SG_ 1311 FCSTP34_FrtCntrStckTchFlg4 "ENM";
BA_ "SignalLongName" SG_ 1311 FCSTP34_FrtCntrStckTchFlg4 "Front Center Stack Touch Position 34 : Front Center Stack Touch Flag 4";
BA_ "SignalLongName" SG_ 1312 FCSTP12_FrtCntrStckTchPosY2 "Front Center Stack Touch Position 12 : Front Center Stack Touch Position Y2";
BA_ "SignalLongName" SG_ 1312 FCSTP12_FrtCntrStckTchPosX2 "Front Center Stack Touch Position 12 : Front Center Stack Touch Position X2";
BA_ "SignalLongName" SG_ 1312 FCSTP12_FrtCntrStckTmStmp12 "Front Center Stack Touch Position 12 : Front Center Stack Time Stamp 12";
BA_ "SignalLongName" SG_ 1312 FCSTP12_FrtCntrStckTchPosY1 "Front Center Stack Touch Position 12 : Front Center Stack Touch Position Y1";
BA_ "SignalType" SG_ 1312 FCSTP12_FrtCntrStckTchFlg2 "ENM";
BA_ "SignalLongName" SG_ 1312 FCSTP12_FrtCntrStckTchFlg2 "Front Center Stack Touch Position 12 : Front Center Stack Touch Flag 2";
BA_ "SignalType" SG_ 1312 FCSTP12_FrtCntrStckTchFlg1 "ENM";
BA_ "SignalLongName" SG_ 1312 FCSTP12_FrtCntrStckTchFlg1 "Front Center Stack Touch Position 12 : Front Center Stack Touch Flag 1";
BA_ "SignalLongName" SG_ 1312 FCSTP12_FrtCntrStckTchPosX1 "Front Center Stack Touch Position 12 : Front Center Stack Touch Position X1";
BA_ "SignalType" SG_ 1312 StrgeOpn "ENM";
BA_ "SignalLongName" SG_ 1312 StrgeOpn "Storage Open";
BA_ "SignalType" SG_ 1313 FrtCntrStckPriVidInLckd "ENM";
BA_ "SignalLongName" SG_ 1313 FrtCntrStckPriVidInLckd "Front Center Stack Primary Video Input Locked";
BA_ "SignalType" SG_ 1313 FrtCntrStckLVMVidInLckd "ENM";
BA_ "SignalLongName" SG_ 1313 FrtCntrStckLVMVidInLckd "Front Center Stack Low Volume Module Video Input Locked";
BA_ "SignalLongName" SG_ 1418 SD88_PV "Serial Data 88 : Protected Value";
BA_ "SignalLongName" SG_ 1418 SD88_ARC "Serial Data 88 : Alive Rolling Count";
BA_ "SignalType" SG_ 1418 PwrtrnExhPrtclFiltManRegnReq "ENM";
BA_ "SignalLongName" SG_ 1418 PwrtrnExhPrtclFiltManRegnReq "Serial Data 88 : Powertrain Exhaust Particle Filter Manual Regeneration Request";
BA_ "SignalLongName" SG_ 1316 VehFlRngCalc "VehicleFuelRangeCalculated";
BA_ "SignalType" SG_ 1316 VehFlRngCalc_Inv "ENM";
BA_ "SignalLongName" SG_ 1316 VehFlRngCalc_Inv "Vehicle Fuel Range Calculated Invalid";
BA_ "SignalLongName" SG_ 1316 FuelEconShrtTrmAvg "Fuel Economy Short Term Average";
BA_ "SignalType" SG_ 1316 FuelLvlLoIndOn "ENM";
BA_ "SignalLongName" SG_ 1316 FuelLvlLoIndOn "Fuel Level Low Indication On";
BA_ "SignalType" SG_ 1316 PTExPrtclFltrMnlRgnDispPrsnt "ENM";
BA_ "SignalLongName" SG_ 1316 PTExPrtclFltrMnlRgnDispPrsnt "Powertrain Exhaust Particle Filter Manual Regeneration Display Present";
BA_ "SignalType" SG_ 1317 FllwgDstIndTmDstSel "ENM";
BA_ "SignalLongName" SG_ 1317 FllwgDstIndTmDstSel "Following Distance Indicator Time Distance Selected";
BA_ "SignalLongName" SG_ 1318 ChmMngrStat "Chime Manager Status";
BA_ "SignalType" SG_ 1318 ChmMngrSoH "ENM";
BA_ "SignalLongName" SG_ 1318 ChmMngrSoH "Chime Manager State of Health";
BA_ "SignalType" SG_ 1318 StrWhlCtlVolUpSw "ENM";
BA_ "SignalLongName" SG_ 1318 StrWhlCtlVolUpSw "Steering Wheel Control Volume Up Switch";
BA_ "SignalType" SG_ 1318 StrWhlCtlVolDnSw "ENM";
BA_ "SignalLongName" SG_ 1318 StrWhlCtlVolDnSw "Steering Wheel Control Volume Down Switch";
BA_ "SignalType" SG_ 1318 StrWhlCtlPshToTlkSw "ENM";
BA_ "SignalLongName" SG_ 1318 StrWhlCtlPshToTlkSw "Steering Wheel Control Push To Talk Switch";
BA_ "SignalType" SG_ 1318 StrWhlCtlFvrtUpSw "ENM";
BA_ "SignalLongName" SG_ 1318 StrWhlCtlFvrtUpSw "Steering Wheel Control Favorites Up Switch";
BA_ "SignalType" SG_ 1318 StrWhlCtlFvrtDnSw "ENM";
BA_ "SignalLongName" SG_ 1318 StrWhlCtlFvrtDnSw "Steering Wheel Control Favorites Down Switch";
BA_ "SignalType" SG_ 1318 StrWhlCtlEndSw "ENM";
BA_ "SignalLongName" SG_ 1318 StrWhlCtlEndSw "Steering Wheel Control End Switch";
BA_ "SignalType" SG_ 1319 VehFlRngLwIO "ENM";
BA_ "SignalLongName" SG_ 1319 VehFlRngLwIO "Vehicle Fuel Range Low Indication On";
BA_ "SignalType" SG_ 1319 TrnsOilLfRstRq "ENM";
BA_ "SignalLongName" SG_ 1319 TrnsOilLfRstRq "Transmission Oil Life Reset Request";
BA_ "SignalType" SG_ 1319 TPSnsrProgEvReq "ENM";
BA_ "SignalLongName" SG_ 1319 TPSnsrProgEvReq "Tire Pressure Sensor Programming Event Requested";
BA_ "SignalType" SG_ 1319 FobProgEvntRqd "ENM";
BA_ "SignalLongName" SG_ 1319 FobProgEvntRqd "Fob Programming Event Requested";
BA_ "SignalType" SG_ 1319 EngOilLifeRstReq "ENM";
BA_ "SignalLongName" SG_ 1319 EngOilLifeRstReq "Engine Oil Life Reset Request";
BA_ "SignalType" SG_ 1319 LnchCtlWhlSlReq "ENM";
BA_ "SignalLongName" SG_ 1319 LnchCtlWhlSlReq "Launch Control Wheel Slip Request";
BA_ "SignalType" SG_ 1319 LnchCtlEngRPMReq "ENM";
BA_ "SignalLongName" SG_ 1319 LnchCtlEngRPMReq "Launch Control Engine RPM Request";
BA_ "SignalType" SG_ 1319 AutoTransGrDispdVal "ENM";
BA_ "SignalLongName" SG_ 1319 AutoTransGrDispdVal "Automatic Transmission Gear Displayed Value";
BA_ "SignalType" SG_ 1319 AutoTransGrDispdVal_Inv "ENM";
BA_ "SignalLongName" SG_ 1319 AutoTransGrDispdVal_Inv "Automatic Transmission Gear Displayed Value Invalid";
BA_ "SignalType" SG_ 1319 LnchCtlRelLineLckReqd "ENM";
BA_ "SignalLongName" SG_ 1319 LnchCtlRelLineLckReqd "Launch Control Release Line Lock Requested";
BA_ "SignalType" SG_ 1319 LnchCtlModeReq "ENM";
BA_ "SignalLongName" SG_ 1319 LnchCtlModeReq "Launch Control Mode Request";
BA_ "SignalLongName" SG_ 1320 Trip1Odo "Trip 1 Odometer";
BA_ "SignalType" SG_ 1320 Trip1Odo_Inv "ENM";
BA_ "SignalLongName" SG_ 1320 Trip1Odo_Inv "Trip 1 Odometer Invalid";
BA_ "SignalLongName" SG_ 1320 Trip2Odo "Trip 2 Odometer";
BA_ "SignalType" SG_ 1320 Trip2Odo_Inv "ENM";
BA_ "SignalLongName" SG_ 1320 Trip2Odo_Inv "Trip 2 Odometer Invalid";
BA_ "SignalType" SG_ 1320 RdHgtAtLocStorConf "ENM";
BA_ "SignalLongName" SG_ 1320 RdHgtAtLocStorConf "Ride Height Auto Location Store Confirmation";
BA_ "SignalType" SG_ 1320 BrkPadLifeSysDrvrReq "ENM";
BA_ "SignalLongName" SG_ 1320 BrkPadLifeSysDrvrReq "Brake Pad Life System Driver Request";
BA_ "SignalType" SG_ 1320 TransOilFiltLifeRstReq "ENM";
BA_ "SignalLongName" SG_ 1320 TransOilFiltLifeRstReq "Transmission Oil Filter Life Reset Request";
BA_ "SignalType" SG_ 1320 TPMTrLdnRstReq "ENM";
BA_ "SignalLongName" SG_ 1320 TPMTrLdnRstReq "Tire Pressure Monitoring Tire Loading Reset Requested";
BA_ "SignalType" SG_ 1320 EngAirFiltMonDrvrReq "ENM";
BA_ "SignalLongName" SG_ 1320 EngAirFiltMonDrvrReq "Engine Air Filter Monitor Driver Request";
BA_ "SignalType" SG_ 1321 IPC_RunCrnkInpActv_Inv "ENM";
BA_ "SignalLongName" SG_ 1321 IPC_RunCrnkInpActv_Inv "IPC Run Crank Input Active Invalidity";
BA_ "SignalType" SG_ 1321 HUD_RclCmpt "ENM";
BA_ "SignalLongName" SG_ 1321 HUD_RclCmpt "Head Up Display Recall Complete";
BA_ "SignalType" SG_ 1321 DispMeasSysExtnd "ENM";
BA_ "SignalLongName" SG_ 1321 DispMeasSysExtnd "Display Measurement System Extended";
BA_ "SignalType" SG_ 1321 ClstrAnmStat "ENM";
BA_ "SignalLongName" SG_ 1321 ClstrAnmStat "Cluster Animation State";
BA_ "SignalType" SG_ 1321 DispMeasSys "ENM";
BA_ "SignalLongName" SG_ 1321 DispMeasSys "Display Measurement System";
BA_ "SignalType" SG_ 1321 ClstrHMI_Rdy "ENM";
BA_ "SignalLongName" SG_ 1321 ClstrHMI_Rdy "Cluster HMI Ready";
BA_ "SignalType" SG_ 1321 APARghtSftBtnStatIPC "ENM";
BA_ "SignalLongName" SG_ 1321 APARghtSftBtnStatIPC "Advanced Park Assist Right Soft Button Status IPC";
BA_ "SignalType" SG_ 1321 APALftSftBtnStatIPC "ENM";
BA_ "SignalLongName" SG_ 1321 APALftSftBtnStatIPC "Advanced Park Assist Left Soft Button Status IPC";
BA_ "SignalType" SG_ 1321 APAFcStatIPC "ENM";
BA_ "SignalLongName" SG_ 1321 APAFcStatIPC "Advanced Park Assist Focus Status IPC";
BA_ "SignalType" SG_ 1321 IPC_RunCrnkInpActv "ENM";
BA_ "SignalLongName" SG_ 1321 IPC_RunCrnkInpActv "IPC Run Crank Input Active";
BA_ "SignalType" SG_ 1321 PAMutDrvrReq "ENM";
BA_ "SignalLongName" SG_ 1321 PAMutDrvrReq "Park Assist Mute Driver Request";
BA_ "SignalType" SG_ 1321 HUD_CustSelActvStat_Inv "ENM";
BA_ "SignalLongName" SG_ 1321 HUD_CustSelActvStat_Inv "Head Up Display Customer Selection Active Status Invalid";
BA_ "SignalType" SG_ 1321 TSMWrngPopUpSts "ENM";
BA_ "SignalLongName" SG_ 1321 TSMWrngPopUpSts "Traffic Sign Memory Warning Pop Up Status";
BA_ "SignalType" SG_ 1321 TSMSgnNtfnWrnDispd "ENM";
BA_ "SignalLongName" SG_ 1321 TSMSgnNtfnWrnDispd "Traffic Sign Memory Sign Notification Warning Displayed";
BA_ "SignalType" SG_ 1321 TSMPageDispActv "ENM";
BA_ "SignalLongName" SG_ 1321 TSMPageDispActv "Traffic Sign Memory Page Display Active";
BA_ "SignalType" SG_ 1321 TSMCustRstReq "ENM";
BA_ "SignalLongName" SG_ 1321 TSMCustRstReq "Traffic Sign Memory Customer Reset Request";
BA_ "SignalType" SG_ 1321 StkHUD_CustSelStat "ENM";
BA_ "SignalLongName" SG_ 1321 StkHUD_CustSelStat "Stuck Head Up Display Customer Selection Status";
BA_ "SignalType" SG_ 1321 HUD_CustSelActvStat "ENM";
BA_ "SignalLongName" SG_ 1321 HUD_CustSelActvStat "Head Up Display Customer Selection Active Status";
BA_ "SignalType" SG_ 1321 StrgWhlCtlInCarVcCommCtlSw "ENM";
BA_ "SignalLongName" SG_ 1321 StrgWhlCtlInCarVcCommCtlSw "Steering Wheel Control In Car Voice Communication Control Switch";
BA_ "SignalType" SG_ 1321 NtVsnVidCntrstUserReq "ENM";
BA_ "SignalLongName" SG_ 1321 NtVsnVidCntrstUserReq "Night Vision Video Contrast User Request";
BA_ "SignalType" SG_ 1321 NtVsnVidBrghtnsUserReq "ENM";
BA_ "SignalLongName" SG_ 1321 NtVsnVidBrghtnsUserReq "Night Vision Video Brightness User Request";
BA_ "SignalType" SG_ 1321 FuelFiltLifeRstReqd "ENM";
BA_ "SignalLongName" SG_ 1321 FuelFiltLifeRstReqd "Fuel Filter Life Reset Requested";
BA_ "SignalType" SG_ 613 JmpStrtReqd "ENM";
BA_ "SignalLongName" SG_ 613 JmpStrtReqd "Jump Start Requested";
BA_ "SignalLongName" SG_ 1273 CldrDay "Calendar Day";
BA_ "SignalType" SG_ 1273 BklghtngCnfg "ENM";
BA_ "SignalLongName" SG_ 1273 BklghtngCnfg "Backlighting Configuration";
BA_ "SignalType" SG_ 1275 HVACICRADSR_LtSet "ENM";
BA_ "SignalLongName" SG_ 1275 HVACICRADSR_LtSet "HVAC Infotainment Controls Request Air Distribution Setting Rear : Left Setting";
BA_ "SignalType" SG_ 1275 HVACICRADSR_RtSet "ENM";
BA_ "SignalLongName" SG_ 1275 HVACICRADSR_RtSet "HVAC Infotainment Controls Request Air Distribution Setting Rear : Right Setting";
BA_ "SignalLongName" SG_ 1275 HVACInfoCtlReqBlwLvlChgRr "HVAC Infotainment Controls Request Blower Level Change Rear";
BA_ "SignalLongName" SG_ 1275 HVACICRTLCR_RtLvlChg "HVAC Infotainment Controls Request Temperature Level Change Rear : Right Level Change";
BA_ "SignalLongName" SG_ 1275 HVACICRTLCR_LtLvlChg "HVAC Infotainment Controls Request Temperature Level Change Rear : Left Level Change";
BA_ "SignalLongName" SG_ 1275 HVACICRBLR_Lvl "HVAC Infotainment Controls Request Blower Level Rear : Level";
BA_ "SignalType" SG_ 1275 HVACICRBLR_LvlActv "ENM";
BA_ "SignalLongName" SG_ 1275 HVACICRBLR_LvlActv "HVAC Infotainment Controls Request Blower Level Rear : Level Active";
BA_ "SignalType" SG_ 1275 HVACInfoCtlReqRrLckSetChg "ENM";
BA_ "SignalLongName" SG_ 1275 HVACInfoCtlReqRrLckSetChg "HVAC Infotainment Controls Request Rear Lock Setting Change";
BA_ "SignalType" SG_ 1275 HVACInfoCtlReqRrDfgSetChg "ENM";
BA_ "SignalLongName" SG_ 1275 HVACInfoCtlReqRrDfgSetChg "HVAC Infotainment Controls Request Rear Defog Setting Change";
BA_ "SignalType" SG_ 1275 HVACInfoCtlReqRrAutoSetChg "ENM";
BA_ "SignalLongName" SG_ 1275 HVACInfoCtlReqRrAutoSetChg "HVAC Infotainment Controls Request Rear Auto Setting Change";
BA_ "SignalType" SG_ 1275 HVACInfoCtlReqRrDfgSet "ENM";
BA_ "SignalLongName" SG_ 1275 HVACInfoCtlReqRrDfgSet "HVAC Infotainment Controls Request Rear Defog Setting";
BA_ "SignalType" SG_ 1275 HVACInfoCtlReqSyncSet "ENM";
BA_ "SignalLongName" SG_ 1275 HVACInfoCtlReqSyncSet "HVAC Infotainment Controls Request Sync Setting";
BA_ "SignalType" SG_ 1275 HVACInfoCtlReqSyncRrSetChg "ENM";
BA_ "SignalLongName" SG_ 1275 HVACInfoCtlReqSyncRrSetChg "HVAC Infotainment Controls Request Sync Rear Setting Change";
BA_ "SignalType" SG_ 1275 HVACInfoCtlReqSyncAllSetChg "ENM";
BA_ "SignalLongName" SG_ 1275 HVACInfoCtlReqSyncAllSetChg "HVAC Infotainment Controls Request Sync All Setting Change";
BA_ "SignalType" SG_ 1275 HVACInfoCtlReqRrPwrSetChg "ENM";
BA_ "SignalLongName" SG_ 1275 HVACInfoCtlReqRrPwrSetChg "HVAC Infotainment Controls Request Rear Power Setting Change";
BA_ "SignalLongName" SG_ 1276 HVACICRTLR_LtLvl "HVAC Infotainment Controls Request Temperature Level Rear : Left Level";
BA_ "SignalType" SG_ 1276 HVACICRTLR_LtLvlActv "ENM";
BA_ "SignalLongName" SG_ 1276 HVACICRTLR_LtLvlActv "HVAC Infotainment Controls Request Temperature Level Rear : Left Level Active";
BA_ "SignalLongName" SG_ 1276 HVACICRTLR_RtLvl "HVAC Infotainment Controls Request Temperature Level Rear : Right Level";
BA_ "SignalType" SG_ 1276 HVACICRTLR_RtLvlActv "ENM";
BA_ "SignalLongName" SG_ 1276 HVACICRTLR_RtLvlActv "HVAC Infotainment Controls Request Temperature Level Rear : Right Level Active";
BA_ "SignalType" SG_ 1276 HVACInfoCtlReqBlwSpdRdct "ENM";
BA_ "SignalLongName" SG_ 1276 HVACInfoCtlReqBlwSpdRdct "HVAC Infotainment Controls Request Blower Speed Reduction";
BA_ "SignalLongName" SG_ 1276 CSI_PV "Chime Status Information : Protection Value";
BA_ "SignalLongName" SG_ 1276 CSI_ARC "Chime Status Information : Alive Rolling Count";
BA_ "SignalType" SG_ 1276 CSI_ChmPrdcrSOH "ENM";
BA_ "SignalLongName" SG_ 1276 CSI_ChmPrdcrSOH "Chime Status Information : Chime Producer State of Health";
BA_ "SignalLongName" SG_ 1277 ChmPrdcrStat "Chime Producer Status";
BA_ "SignalType" SG_ 1277 HVACICRADSCR_LtChgNext "ENM";
BA_ "SignalLongName" SG_ 1277 HVACICRADSCR_LtChgNext "HVAC Infotainment Controls Request Air Distribution Setting Change Rear : Left Change Next";
BA_ "SignalType" SG_ 1277 HVACICRADSCR_RtChgNext "ENM";
BA_ "SignalLongName" SG_ 1277 HVACICRADSCR_RtChgNext "HVAC Infotainment Controls Request Air Distribution Setting Change Rear : Right Change Next";
BA_ "SignalLongName" SG_ 1278 CurrRadioAMFreq "Current Radio AM Frequency";
BA_ "SignalType" SG_ 1278 TeenDrvReq "ENM";
BA_ "SignalLongName" SG_ 1278 TeenDrvReq "Teen Driver Request";
BA_ "SignalType" SG_ 1278 Ftr6AlrmReq "ENM";
BA_ "SignalLongName" SG_ 1278 Ftr6AlrmReq "Feature 6 Alarm Request";
BA_ "SignalType" SG_ 1278 LnChgAlrtCstChngSetReq "ENM";
BA_ "SignalLongName" SG_ 1278 LnChgAlrtCstChngSetReq "Lane Change Alert Customization Change Setting Request";
BA_ "SignalType" SG_ 1278 TCP_LCMFileTrans "ENM";
BA_ "SignalLongName" SG_ 1278 TCP_LCMFileTrans "Telematics - License Compliance Material File Transfer";
BA_ "SignalType" SG_ 1278 TCP_LCMDataMsgStat "ENM";
BA_ "SignalLongName" SG_ 1278 TCP_LCMDataMsgStat "Telematics - License Compliance Material Data Message Status";
BA_ "SignalType" SG_ 1278 IPC_LCMDataMsgStat "ENM";
BA_ "SignalLongName" SG_ 1278 IPC_LCMDataMsgStat "IPC_LCMDataMessageStatus";
BA_ "SignalType" SG_ 1278 CamVidICS_DispAct "ENM";
BA_ "SignalLongName" SG_ 1278 CamVidICS_DispAct "Camera Video ICS Display Active";
BA_ "SignalType" SG_ 1278 ValetMdReq "ENM";
BA_ "SignalLongName" SG_ 1278 ValetMdReq "Valet Mode Request";
BA_ "SignalLongName" SG_ 1279 Ftr6AlrmTm "Feature 6 Alarm Time";
BA_ "SignalLongName" SG_ 1279 TeenDrvPinCd "Teen Driver PIN Code";
BA_ "SignalLongName" SG_ 1279 ValetPIN "Valet PIN";
BA_ "SignalType" SG_ 1279 LngSelExt "ENM";
BA_ "SignalLongName" SG_ 1279 LngSelExt "Language Selection Extended";
BA_ "SignalType" SG_ 1279 IPC_LCMFileTrans "ENM";
BA_ "SignalLongName" SG_ 1279 IPC_LCMFileTrans "IPC_LCMFileTransfer";
BA_ "SignalType" SG_ 1280 VehLctrLtsCstChgSetReq "ENM";
BA_ "SignalLongName" SG_ 1280 VehLctrLtsCstChgSetReq "Vehicle Locator Lights Customization Change Setting Request";
BA_ "SignalType" SG_ 1280 TrlrMirVidGdlnsCstChgSetReq "ENM";
BA_ "SignalLongName" SG_ 1280 TrlrMirVidGdlnsCstChgSetReq "Trailering Mirror Video Guidelines Customization Change Setting Request";
BA_ "SignalType" SG_ 1280 TrlrMirVidEnblCstChgSetReq "ENM";
BA_ "SignalLongName" SG_ 1280 TrlrMirVidEnblCstChgSetReq "Trailering Mirror Video Enable Customization Change Setting Request";
BA_ "SignalType" SG_ 1280 APARghtSftBtnStat "ENM";
BA_ "SignalLongName" SG_ 1280 APARghtSftBtnStat "Advanced Park Assist Right Soft Button Status";
BA_ "SignalType" SG_ 1280 APAPrllPrkSftBtnStat "ENM";
BA_ "SignalLongName" SG_ 1280 APAPrllPrkSftBtnStat "Advanced Park Assist Parallel Parking Soft Button Status";
BA_ "SignalType" SG_ 1280 ElvtdIdlCstChgSetReq "ENM";
BA_ "SignalLongName" SG_ 1280 ElvtdIdlCstChgSetReq "Elevated Idle Customization Change Setting Request";
BA_ "SignalType" SG_ 1280 WlkAwyLckCstChgSetReq "ENM";
BA_ "SignalLongName" SG_ 1280 WlkAwyLckCstChgSetReq "Walk Away Locking Customization Change Setting Request";
BA_ "SignalType" SG_ 1280 StBltShfIntlkCstChgSetReq "ENM";
BA_ "SignalLongName" SG_ 1280 StBltShfIntlkCstChgSetReq "Seat Belt Shift Interlock Customization Change Setting Request";
BA_ "SignalType" SG_ 1280 TimeDispFormat "ENM";
BA_ "SignalLongName" SG_ 1280 TimeDispFormat "Time Display Format";
BA_ "SignalType" SG_ 1280 RstrCstDfltReq "ENM";
BA_ "SignalLongName" SG_ 1280 RstrCstDfltReq "Restore Customization Defaults Request";
BA_ "SignalType" SG_ 1280 RFStStsDispActv "ENM";
BA_ "SignalLongName" SG_ 1280 RFStStsDispActv "Right Front Seat Status Display Active";
BA_ "SignalType" SG_ 1280 LFStStsDispActv "ENM";
BA_ "SignalLongName" SG_ 1280 LFStStsDispActv "Left Front Seat Status Display Active";
BA_ "SignalType" SG_ 1280 APASrchSftBtnStat "ENM";
BA_ "SignalLongName" SG_ 1280 APASrchSftBtnStat "Advanced Park Assist Searching Soft Button Status";
BA_ "SignalType" SG_ 1280 TnDrvStBltShfIntlkCstChgSetReq "ENM";
BA_ "SignalLongName" SG_ 1280 TnDrvStBltShfIntlkCstChgSetReq "Teen Driver Seat Belt Shift Interlock Customization Change Setting Request";
BA_ "SignalType" SG_ 1281 RlkRtUlkDrCstChSetReq "ENM";
BA_ "SignalLongName" SG_ 1281 RlkRtUlkDrCstChSetReq "Relock Remote Unlocked Door Customization Change Setting Request";
BA_ "SignalType" SG_ 1281 RevTltMrCstChgSetReq "ENM";
BA_ "SignalLongName" SG_ 1281 RevTltMrCstChgSetReq "Reverse Tilt Mirror Customization Change Setting Request";
BA_ "SignalType" SG_ 1281 RemWndOpCstChgSetReq "ENM";
BA_ "SignalLongName" SG_ 1281 RemWndOpCstChgSetReq "Remote Window Operation Customization Change Setting Request";
BA_ "SignalType" SG_ 1281 RnSnsCstChgSetReq "ENM";
BA_ "SignalLongName" SG_ 1281 RnSnsCstChgSetReq "Rain Sense Customization Change Setting Request";
BA_ "SignalType" SG_ 1281 RmtStrtHtdStCstChgSetReq "ENM";
BA_ "SignalLongName" SG_ 1281 RmtStrtHtdStCstChgSetReq "Remote Start Heated Seat Customization Change Setting Request";
BA_ "SignalType" SG_ 1281 RmtStrtCoolStCstChgSetReq "ENM";
BA_ "SignalLongName" SG_ 1281 RmtStrtCoolStCstChgSetReq "Remote Start Cooled Seat Customization Change Setting Request";
BA_ "SignalType" SG_ 1281 RnngBrdManDplyCstChgSetReq "ENM";
BA_ "SignalLongName" SG_ 1281 RnngBrdManDplyCstChgSetReq "Running Boards Manual Deployment Customization Change Setting Request";
BA_ "SignalType" SG_ 1281 RnngBrdAutoDplyCstChgSetReq "ENM";
BA_ "SignalLongName" SG_ 1281 RnngBrdAutoDplyCstChgSetReq "Running Boards Automatic Deployment Customization Change Setting Request";
BA_ "SignalType" SG_ 1281 RrPCMRspTypCstChgSetReq "ENM";
BA_ "SignalLongName" SG_ 1281 RrPCMRspTypCstChgSetReq "Rear PCM Response Type Customization Change Setting Request";
BA_ "SignalType" SG_ 1281 RrDfgStUpCstChgSetReq "ENM";
BA_ "SignalLongName" SG_ 1281 RrDfgStUpCstChgSetReq "Rear Defog Startup Customization Change Setting Request";
BA_ "SignalType" SG_ 1281 RrCrsTrfcAlrtCstChngSetReq "ENM";
BA_ "SignalLongName" SG_ 1281 RrCrsTrfcAlrtCstChngSetReq "Rear Cross Traffic Alert Customization Change Setting Request";
BA_ "SignalType" SG_ 1281 RtLkFdbkCstChgSetReq "ENM";
BA_ "SignalLongName" SG_ 1281 RtLkFdbkCstChgSetReq "Remote Locking Feedback Customization Change Setting Request";
BA_ "SignalType" SG_ 1281 RrVwPrkAstSymCstChgSetReq "ENM";
BA_ "SignalLongName" SG_ 1281 RrVwPrkAstSymCstChgSetReq "Rear View Park Assist Symbol Customization Change Setting Request";
BA_ "SignalType" SG_ 1281 RrStRmndrEnblDsblCstChgSetReq "ENM";
BA_ "SignalLongName" SG_ 1281 RrStRmndrEnblDsblCstChgSetReq "Rear Seat Reminder Enable Disable Customization Change Setting Request";
BA_ "SignalType" SG_ 1281 SBZAlrtCstChngSetReq "ENM";
BA_ "SignalLongName" SG_ 1281 SBZAlrtCstChngSetReq "Side Blind Zone Alert Customization Change Setting Request";
BA_ "SignalType" SG_ 1281 RtUlkLtFbCstChgSetReq "ENM";
BA_ "SignalLongName" SG_ 1281 RtUlkLtFbCstChgSetReq "Remote Unlock Lighting Feedback Customization Change Setting Request";
BA_ "SignalType" SG_ 1281 StBltTghtngCstChgSetReq "ENM";
BA_ "SignalLongName" SG_ 1281 StBltTghtngCstChgSetReq "Seat Belt Tightening Customization Change Setting Request";
BA_ "SignalType" SG_ 1281 SrrndVwLghtCstChgSetReq "ENM";
BA_ "SignalLongName" SG_ 1281 SrrndVwLghtCstChgSetReq "Surround View Lighting Customization Change Setting Request";
BA_ "SignalType" SG_ 1281 SelUlkCstChgSetReq "ENM";
BA_ "SignalLongName" SG_ 1281 SelUlkCstChgSetReq "Selective Unlocking Customization Change Setting Request";
BA_ "SignalType" SG_ 1281 APALftSftBtnStat "ENM";
BA_ "SignalLongName" SG_ 1281 APALftSftBtnStat "Advanced Park Assist Left Soft Button Status";
BA_ "SignalType" SG_ 1281 TrffcLgtAsstCstChgSetReq "ENM";
BA_ "SignalLongName" SG_ 1281 TrffcLgtAsstCstChgSetReq "Traffic Light Assist Customization Change Setting Request";
BA_ "SignalType" SG_ 1281 TnDrvSpdLmtCstChgStReq "ENM";
BA_ "SignalLongName" SG_ 1281 TnDrvSpdLmtCstChgStReq "Teen Driver Speed Limit Customization Change Setting Request";
BA_ "SignalType" SG_ 1282 LvlgSysAlgnMdCstChgSetReq "ENM";
BA_ "SignalLongName" SG_ 1282 LvlgSysAlgnMdCstChgSetReq "Leveling System Alignment Mode Customization Change Setting Request";
BA_ "SignalType" SG_ 1282 LtRtHnTrCstChgSetReq "ENM";
BA_ "SignalLongName" SG_ 1282 LtRtHnTrCstChgSetReq "Left Right Hand Traffic Customization Change Setting Request";
BA_ "SignalType" SG_ 1282 LDCLCstChgSetReq "ENM";
BA_ "SignalLongName" SG_ 1282 LDCLCstChgSetReq "Last Door Closed Locking Customization Change Setting Request";
BA_ "SignalType" SG_ 1282 OpDrAtLOCstChgSetReq "ENM";
BA_ "SignalLongName" SG_ 1282 OpDrAtLOCstChgSetReq "Open Door Anti Lock Out Customization Change Setting Request";
BA_ "SignalType" SG_ 1282 LvlgSysServMdCstChgSetReq "ENM";
BA_ "SignalLongName" SG_ 1282 LvlgSysServMdCstChgSetReq "Leveling System Service Mode Customization Change Setting Request";
BA_ "SignalType" SG_ 1282 LvlgSysEntEgrsMdCstChgSetReq "ENM";
BA_ "SignalLongName" SG_ 1282 LvlgSysEntEgrsMdCstChgSetReq "Leveling System Entry Egress Mode Customization Change Setting Request";
BA_ "SignalType" SG_ 1282 PlltnCtrlCstChgSetReq "ENM";
BA_ "SignalLongName" SG_ 1282 PlltnCtrlCstChgSetReq "Pollution Control Customization Change Setting Request";
BA_ "SignalType" SG_ 1282 PhnLtInVehCstChgSetReq "ENM";
BA_ "SignalLongName" SG_ 1282 PhnLtInVehCstChgSetReq "Phone Left In Vehicle Customization Change Setting Request";
BA_ "SignalType" SG_ 1282 PrsnlMdActAeroCstChngSetReq "ENM";
BA_ "SignalLongName" SG_ 1282 PrsnlMdActAeroCstChngSetReq "Personal Mode Active Aero Customization Change Setting Request";
BA_ "SignalType" SG_ 1282 PrkAsstTrHtchPsntCstChgSetReq "ENM";
BA_ "SignalLongName" SG_ 1282 PrkAsstTrHtchPsntCstChgSetReq "Park Assist Trailer Hitch Present Customization Change Setting Request";
BA_ "SignalType" SG_ 1282 PrkAsstOnOffCstChgSetReq "ENM";
BA_ "SignalLongName" SG_ 1282 PrkAsstOnOffCstChgSetReq "Park Assist On Off Customization Change Setting Request";
BA_ "SignalType" SG_ 1282 PrsnlMdRideHghtCstChngSetReq "ENM";
BA_ "SignalLongName" SG_ 1282 PrsnlMdRideHghtCstChngSetReq "Personal Mode Ride Height Customization Change Setting Request";
BA_ "SignalType" SG_ 1282 PrsnlMdDrvlCstChngSetReq "ENM";
BA_ "SignalLongName" SG_ 1282 PrsnlMdDrvlCstChngSetReq "Personal Mode Driveline Customization Change Setting Request";
BA_ "SignalType" SG_ 1282 PrsnlMdBrkPdlCstChngSetReq "ENM";
BA_ "SignalLongName" SG_ 1282 PrsnlMdBrkPdlCstChngSetReq "Personal Mode Brake Pedal Customization Change Setting Request";
BA_ "SignalType" SG_ 1282 PrsnlMdSpnCstChngSetReq "ENM";
BA_ "SignalLongName" SG_ 1282 PrsnlMdSpnCstChngSetReq "Personal Mode Suspension Customization Change Setting Request";
BA_ "SignalType" SG_ 1282 PrsnlMdSndCstChngSetReq "ENM";
BA_ "SignalLongName" SG_ 1282 PrsnlMdSndCstChngSetReq "Personal Mode Sound Customization Change Setting Request";
BA_ "SignalType" SG_ 1282 PsvUnlckCstChgSetReq "ENM";
BA_ "SignalLongName" SG_ 1282 PsvUnlckCstChgSetReq "Passive Unlocking Customization Change Setting Request";
BA_ "SignalType" SG_ 1282 PrsnlMdStrCstChngSetReq "ENM";
BA_ "SignalLongName" SG_ 1282 PrsnlMdStrCstChngSetReq "Personal Mode Steering Customization Change Setting Request";
BA_ "SignalType" SG_ 1282 APAFcStatCSM "ENM";
BA_ "SignalLongName" SG_ 1282 APAFcStatCSM "Advanced Park Assist Focus Status CSM";
BA_ "SignalType" SG_ 1282 RemLftVehRmCstChgSetReq "ENM";
BA_ "SignalLongName" SG_ 1282 RemLftVehRmCstChgSetReq "Remote Left Vehcile Reminder Customization Change Setting Request";
BA_ "SignalType" SG_ 1282 RemInVehRmCstChgSetReq "ENM";
BA_ "SignalLongName" SG_ 1282 RemInVehRmCstChgSetReq "Remote In Vehicle Reminder Customization Change Setting Request";
BA_ "SignalType" SG_ 1283 CustMdDrvlCstChngSetReq "ENM";
BA_ "SignalLongName" SG_ 1283 CustMdDrvlCstChngSetReq "Custom Mode Driveline Customization Change Setting Request";
BA_ "SignalType" SG_ 1283 CustMdSpnCstChngSetReq "ENM";
BA_ "SignalLongName" SG_ 1283 CustMdSpnCstChngSetReq "Custom Mode Suspension Customization Change Setting Request";
BA_ "SignalType" SG_ 1283 CustMdSndCstChngSetReq "ENM";
BA_ "SignalLongName" SG_ 1283 CustMdSndCstChngSetReq "Custom Mode Sound Customization Change Setting Request";
BA_ "SignalType" SG_ 1283 CustMdRideHghtCstChngSetReq "ENM";
BA_ "SignalLongName" SG_ 1283 CustMdRideHghtCstChngSetReq "Custom Mode Ride Height Customization Change Setting Request";
BA_ "SignalType" SG_ 1283 CustMdStrCstChngSetReq "ENM";
BA_ "SignalLongName" SG_ 1283 CustMdStrCstChngSetReq "Custom Mode Steering Customization Change Setting Request";
BA_ "SignalType" SG_ 1283 EsyExtCstChgSetReq "ENM";
BA_ "SignalLongName" SG_ 1283 EsyExtCstChgSetReq "Easy Exit Customization Change Setting Request";
BA_ "SignalType" SG_ 1283 DrvrAlrtTypCstChgStReq "ENM";
BA_ "SignalLongName" SG_ 1283 DrvrAlrtTypCstChgStReq "Driver Alert Type Customization Change Setting Request";
BA_ "SignalType" SG_ 1283 DayTmTlLtsCstChgSetReq "ENM";
BA_ "SignalLongName" SG_ 1283 DayTmTlLtsCstChgSetReq "Day Time Taillight Customization Change Setting Request";
BA_ "SignalType" SG_ 1283 FrntPCMRspTypCstChgSetReq "ENM";
BA_ "SignalLongName" SG_ 1283 FrntPCMRspTypCstChgSetReq "Front PCM Response Type Customization Change Setting Request";
BA_ "SignalType" SG_ 1283 ExitLghtngCstChgSetReq "ENM";
BA_ "SignalLongName" SG_ 1283 ExitLghtngCstChgSetReq "Exit Lighting Customization Change Setting Request";
BA_ "SignalType" SG_ 1283 FrwdImpMtgnOpSlctCstChgSetReq "ENM";
BA_ "SignalLongName" SG_ 1283 FrwdImpMtgnOpSlctCstChgSetReq "Forward Impact Mitigation Operation Select Customization Change Setting Request";
BA_ "SignalType" SG_ 1283 FrtRdHgtGPSCstChngSetReq "ENM";
BA_ "SignalLongName" SG_ 1283 FrtRdHgtGPSCstChngSetReq "Front Ride Height GPS Customization Change Setting Request";
BA_ "SignalType" SG_ 1283 HFRCCstChgSetReq "ENM";
BA_ "SignalLongName" SG_ 1283 HFRCCstChgSetReq "Hands Free Rear Closure Customization Change Setting Request";
BA_ "SignalType" SG_ 1283 GoNotfrCstChgSetReq "ENM";
BA_ "SignalLongName" SG_ 1283 GoNotfrCstChgSetReq "Go Notifier Customization Change Setting Request";
BA_ "SignalType" SG_ 1283 GlrFrHgBmRspTypCstChgSetReq "ENM";
BA_ "SignalLongName" SG_ 1283 GlrFrHgBmRspTypCstChgSetReq "Glare Free High Beam Response Type Customization Change Setting Request";
BA_ "SignalType" SG_ 1283 APAExtPrkSftBtnStat "ENM";
BA_ "SignalLongName" SG_ 1283 APAExtPrkSftBtnStat "Advanced Park Assist Exit Park Soft Button Status";
BA_ "SignalType" SG_ 1283 JckKnfDtnCstChgSetReq "ENM";
BA_ "SignalLongName" SG_ 1283 JckKnfDtnCstChgSetReq "Jack Knife Detection Customization Change Setting Request";
BA_ "SignalType" SG_ 1283 IonzrCtrlCstChgSetReq "ENM";
BA_ "SignalLongName" SG_ 1283 IonzrCtrlCstChgSetReq "Ionizer Control Customization Change Setting Request";
BA_ "SignalType" SG_ 1284 TAC_AudConctOutcm "ENM";
BA_ "SignalLongName" SG_ 1284 TAC_AudConctOutcm "Telematics Audio Control : Audio Connection Outcome";
BA_ "SignalType" SG_ 1284 TAC_AudChConctStat "ENM";
BA_ "SignalLongName" SG_ 1284 TAC_AudChConctStat "Telematics Audio Control : Audio Channel Connection State";
BA_ "SignalType" SG_ 1284 TDOSWCCSR_ChgSetReq "ENM";
BA_ "SignalLongName" SG_ 1284 TDOSWCCSR_ChgSetReq "Teen Driver Overspeed Warning Customization Change Setting Request : Change Setting Request";
BA_ "SignalType" SG_ 1284 TDOSWCCSR_DecSwAct "ENM";
BA_ "SignalLongName" SG_ 1284 TDOSWCCSR_DecSwAct "Teen Driver Overspeed Warning Customization Change Setting Request : Decrement Switch Active";
BA_ "SignalType" SG_ 1284 TDOSWCCSR_IncSwAct "ENM";
BA_ "SignalLongName" SG_ 1284 TDOSWCCSR_IncSwAct "Teen Driver Overspeed Warning Customization Change Setting Request : Increment Switch Active";
BA_ "SignalType" SG_ 1284 InfoSysStat "ENM";
BA_ "SignalLongName" SG_ 1284 InfoSysStat "Infotainment System State";
BA_ "SignalType" SG_ 1284 AirQltySensCstChgSetReq "ENM";
BA_ "SignalLongName" SG_ 1284 AirQltySensCstChgSetReq "Air Quality Sensor Customization Change Setting Request";
BA_ "SignalType" SG_ 1284 AdpLghtRspTypCstChgSetReq "ENM";
BA_ "SignalLongName" SG_ 1284 AdpLghtRspTypCstChgSetReq "Adaptive Lighting Response Type Customization Change Setting Request";
BA_ "SignalType" SG_ 1284 AutoAirDstCstChgSetReq "ENM";
BA_ "SignalLongName" SG_ 1284 AutoAirDstCstChgSetReq "Auto Air Distribution Customization Change Setting Request";
BA_ "SignalType" SG_ 1284 AutUnlckCstChgSetReq "ENM";
BA_ "SignalLongName" SG_ 1284 AutUnlckCstChgSetReq "AutomaticUnlockingCustomizationChangeSettingRequest";
BA_ "SignalType" SG_ 1284 AutDrvLckCstChgSetReq "ENM";
BA_ "SignalLongName" SG_ 1284 AutDrvLckCstChgSetReq "Automatic Drive Locking Customization Change Setting Request";
BA_ "SignalType" SG_ 1284 AutoFanCstChgSetReq "ENM";
BA_ "SignalLongName" SG_ 1284 AutoFanCstChgSetReq "Automatic Fan Customization Change Setting Request";
BA_ "SignalType" SG_ 1284 AutoDfgCstChgSetReq "ENM";
BA_ "SignalLongName" SG_ 1284 AutoDfgCstChgSetReq "Automatic Defog Customization Change Setting Request";
BA_ "SignalType" SG_ 1284 AutoCoolStCstChgSetReq "ENM";
BA_ "SignalLongName" SG_ 1284 AutoCoolStCstChgSetReq "Automatic Cooled Seat Customization Change Setting Request";
BA_ "SignalType" SG_ 1284 AutoMemRclCstChgSetReq "ENM";
BA_ "SignalLongName" SG_ 1284 AutoMemRclCstChgSetReq "Auto Memory Recall Customization Change Setting Request";
BA_ "SignalType" SG_ 1284 AutoHtdStCstChgSetReq "ENM";
BA_ "SignalLongName" SG_ 1284 AutoHtdStCstChgSetReq "Automatic Heated Seat Customization Change Setting Request";
BA_ "SignalType" SG_ 1284 ClstrDspAnmReq "ENM";
BA_ "SignalLongName" SG_ 1284 ClstrDspAnmReq "Cluster Display Animation Request";
BA_ "SignalType" SG_ 1284 AutoRrWpCstChgSetReq "ENM";
BA_ "SignalLongName" SG_ 1284 AutoRrWpCstChgSetReq "Auto Rear Wipe Customization Change Setting Request";
BA_ "SignalType" SG_ 1284 AutoMrFldCstChgSetReq "ENM";
BA_ "SignalLongName" SG_ 1284 AutoMrFldCstChgSetReq "Auto Mirror Fold Customization Change Setting Request";
BA_ "SignalType" SG_ 1284 APACrssBckInSftBtnStat "ENM";
BA_ "SignalLongName" SG_ 1284 APACrssBckInSftBtnStat "Advanced Park Assist Cross Back-In Soft Button Status";
BA_ "SignalType" SG_ 1284 CrgBedVwAutoLgtCstChgSetReq "ENM";
BA_ "SignalLongName" SG_ 1284 CrgBedVwAutoLgtCstChgSetReq "Cargo Bed View Auto Lighting Customization Change Setting Request";
BA_ "SignalLongName" SG_ 615 InfoAuxBrightnessLvl "Infotainment Auxiliary Brightness Level";
BA_ "SignalLongName" SG_ 615 InfoBklghtBrightnessLvl "Infotainment Backlight Brightness Level";
BA_ "SignalLongName" SG_ 615 InfoDispBrightnessLvl "Infotainment Display Brightness Level";
BA_ "SignalType" SG_ 615 IntAmbBrghtnsCtrlSetReq "ENM";
BA_ "SignalLongName" SG_ 615 IntAmbBrghtnsCtrlSetReq "Interior Ambient Brightness Control Setting Request";
BA_ "SignalLongName" SG_ 1332 LclTmYrVal "Local Time Year Value";
BA_ "SignalType" SG_ 1332 LclTmYrVal_Inv "ENM";
BA_ "SignalLongName" SG_ 1332 LclTmYrVal_Inv "Local Time Year Value Invalid";
BA_ "SignalLongName" SG_ 1332 LclTmMinVal "Local Time Minutes Value";
BA_ "SignalType" SG_ 1332 LclTmMinVal_Inv "ENM";
BA_ "SignalLongName" SG_ 1332 LclTmMinVal_Inv "Local Time Minutes Value Invalid";
BA_ "SignalType" SG_ 1332 LclTmDayVal_Inv "ENM";
BA_ "SignalLongName" SG_ 1332 LclTmDayVal_Inv "Local Time Day Value Invalid";
BA_ "SignalLongName" SG_ 1332 LclTmSecVal "Local Time Seconds Value";
BA_ "SignalType" SG_ 1332 LclTmSecVal_Inv "ENM";
BA_ "SignalLongName" SG_ 1332 LclTmSecVal_Inv "Local Time Seconds Value Invalid";
BA_ "SignalLongName" SG_ 1332 LclTmHrVal "Local Time Hours Value";
BA_ "SignalType" SG_ 1332 LclTmHrVal_Inv "ENM";
BA_ "SignalLongName" SG_ 1332 LclTmHrVal_Inv "Local Time Hours Value Invalid";
BA_ "SignalLongName" SG_ 1332 LclTmDayVal "Local Time Day Value";
BA_ "SignalType" SG_ 1332 LclTmMthVal "ENM";
BA_ "SignalLongName" SG_ 1332 LclTmMthVal "Local Time Month Value";
BA_ "SignalType" SG_ 1332 LclTmMthVal_Inv "ENM";
BA_ "SignalLongName" SG_ 1332 LclTmMthVal_Inv "Local Time Month Value Invalid";
BA_ "SignalLongName" SG_ 1308 FrtCntrStckEncdr4 "Front Center Stack Encoder 4";
BA_ "SignalLongName" SG_ 1308 FrtCntrStckEncdr5 "Front Center Stack Encoder 5";
BA_ "SignalLongName" SG_ 1308 FrtCntrStckMenuEncdr "Front Center Stack Menu Encoder";
BA_ "SignalLongName" SG_ 1308 FrtCntrStckTuneEncdr "Front Center Stack Tune Encoder";
BA_ "SignalLongName" SG_ 1308 FrtCntrStckVolEncdr "Front Center Stack Volume Encoder";
BA_ "SignalType" SG_ 1308 FrtCntrStckFvrtUpSw "ENM";
BA_ "SignalLongName" SG_ 1308 FrtCntrStckFvrtUpSw "Front Center Stack Favorites Up Switch";
BA_ "SignalType" SG_ 1308 FrtCntrStckFvrtDnSw "ENM";
BA_ "SignalLongName" SG_ 1308 FrtCntrStckFvrtDnSw "Front Center Stack Favorites Down Switch";
BA_ "SignalType" SG_ 1308 FrtCntrStckEjectSw "ENM";
BA_ "SignalLongName" SG_ 1308 FrtCntrStckEjectSw "Front Center Stack Eject Switch";
BA_ "SignalType" SG_ 1308 FrtCntrStckDiscAuxSw "ENM";
BA_ "SignalLongName" SG_ 1308 FrtCntrStckDiscAuxSw "Front Center Stack Disc Auxiliary Switch";
BA_ "SignalType" SG_ 1308 FrtCntrStckBndSw "ENM";
BA_ "SignalLongName" SG_ 1308 FrtCntrStckBndSw "Front Center Stack Band Switch";
BA_ "SignalType" SG_ 1308 FrtCntrStckBnchBtnID_VirtSw "ENM";
BA_ "SignalLongName" SG_ 1308 FrtCntrStckBnchBtnID_VirtSw "Front Center Stack Bench Button ID Virtual Switch";
BA_ "SignalType" SG_ 1308 FrtCntrStckBackSw "ENM";
BA_ "SignalLongName" SG_ 1308 FrtCntrStckBackSw "Front Center Stack Back Switch";
BA_ "SignalType" SG_ 1308 FrtCntrStckAllRelSw "ENM";
BA_ "SignalLongName" SG_ 1308 FrtCntrStckAllRelSw "Front Center Stack All Release Switch";
BA_ "SignalType" SG_ 1308 FrtCntrStckSw24 "ENM";
BA_ "SignalLongName" SG_ 1308 FrtCntrStckSw24 "Front Center Stack Switch 24";
BA_ "SignalType" SG_ 1308 FrtCntrStckSw23 "ENM";
BA_ "SignalLongName" SG_ 1308 FrtCntrStckSw23 "Front Center Stack Switch 23";
BA_ "SignalType" SG_ 1308 FrtCntrStckStrgeUnlckSw "ENM";
BA_ "SignalLongName" SG_ 1308 FrtCntrStckStrgeUnlckSw "Front Center Stack Storage Unlock Switch";
BA_ "SignalType" SG_ 1308 FrtCntrStckPwrSw "ENM";
BA_ "SignalLongName" SG_ 1308 FrtCntrStckPwrSw "Front Center Stack Power Switch";
BA_ "SignalType" SG_ 1308 FrtCntrStckPrevSw "ENM";
BA_ "SignalLongName" SG_ 1308 FrtCntrStckPrevSw "Front Center Stack Previous Switch";
BA_ "SignalType" SG_ 1308 FrtCntrStckNextSw "ENM";
BA_ "SignalLongName" SG_ 1308 FrtCntrStckNextSw "Front Center Stack Next Switch";
BA_ "SignalType" SG_ 1308 FrtCntrStckMenuSw "ENM";
BA_ "SignalLongName" SG_ 1308 FrtCntrStckMenuSw "Front Center Stack Menu Switch";
BA_ "SignalType" SG_ 1308 FrtCntrStckHomeSw "ENM";
BA_ "SignalLongName" SG_ 1308 FrtCntrStckHomeSw "Front Center Stack Home Switch";
BA_ "SignalType" SG_ 1308 FrtCntrStckSw32 "ENM";
BA_ "SignalLongName" SG_ 1308 FrtCntrStckSw32 "Front Center Stack Switch 32";
BA_ "SignalType" SG_ 1308 FrtCntrStckSw31 "ENM";
BA_ "SignalLongName" SG_ 1308 FrtCntrStckSw31 "Front Center Stack Switch 31";
BA_ "SignalType" SG_ 1308 FrtCntrStckSw30 "ENM";
BA_ "SignalLongName" SG_ 1308 FrtCntrStckSw30 "Front Center Stack Switch 30";
BA_ "SignalType" SG_ 1308 FrtCntrStckSw29 "ENM";
BA_ "SignalLongName" SG_ 1308 FrtCntrStckSw29 "Front Center Stack Switch 29";
BA_ "SignalType" SG_ 1308 FrtCntrStckSw28 "ENM";
BA_ "SignalLongName" SG_ 1308 FrtCntrStckSw28 "Front Center Stack Switch 28";
BA_ "SignalType" SG_ 1308 FrtCntrStckSw27 "ENM";
BA_ "SignalLongName" SG_ 1308 FrtCntrStckSw27 "Front Center Stack Switch 27";
BA_ "SignalType" SG_ 1308 FrtCntrStckSw26 "ENM";
BA_ "SignalLongName" SG_ 1308 FrtCntrStckSw26 "Front Center Stack Switch 26";
BA_ "SignalType" SG_ 1308 FrtCntrStckSw25 "ENM";
BA_ "SignalLongName" SG_ 1308 FrtCntrStckSw25 "Front Center Stack Switch 25";
VAL_ 1182 TrlrTireRtMdlPres_Inv 0 "FALSE" 1 "TRUE" ;
VAL_ 1182 TrlrTireRtMdlTemp_Inv 0 "FALSE" 1 "TRUE" ;
VAL_ 1182 TrlrTireRtMdlPresSts 0 "Unknown" 1 "Normal" 2 "Low Pressure" 3 "Malfunction" 4 "Learning in Progress" 5 "Learn Tire" 6 "Tire Learning Complete" 7 "High Pressure" 8 "High Temperature" ;
VAL_ 1182 TrlrTireRtMdlPresSts_Inv 0 "FALSE" 1 "TRUE" ;
VAL_ 1183 TrlrTireRFPres_Inv 0 "FALSE" 1 "TRUE" ;
VAL_ 1183 TrlrTireRFTemp_Inv 0 "FALSE" 1 "TRUE" ;
VAL_ 1183 TrlrTirePresSysFaild 0 "FALSE" 1 "TRUE" ;
VAL_ 1183 TrlrTirePresFtrEnbld 0 "FALSE" 1 "TRUE" ;
VAL_ 1183 TrlrTireRFPresSts 0 "Unknown" 1 "Normal" 2 "Low Pressure" 3 "Malfunction" 4 "Learning in Progress" 5 "Learn Tire" 6 "Tire Learning Complete" 7 "High Pressure" 8 "High Temperature" ;
VAL_ 1183 TrlrTireRFPresSts_Inv 0 "FALSE" 1 "TRUE" ;
VAL_ 1184 TrlrTireLRPres_Inv 0 "FALSE" 1 "TRUE" ;
VAL_ 1184 TrlrTireLRTemp_Inv 0 "FALSE" 1 "TRUE" ;
VAL_ 1184 TnDrvOvSpdWrnCstAvlFlg2 0 "FALSE" 1 "TRUE" ;
VAL_ 1184 TnDrvOvSpdWrnCstAvlFlg1 0 "FALSE" 1 "TRUE" ;
VAL_ 1184 TrlrTireLRPresSts 0 "Unknown" 1 "Normal" 2 "Low Pressure" 3 "Malfunction" 4 "Learning in Progress" 5 "Learn Tire" 6 "Tire Learning Complete" 7 "High Pressure" 8 "High Temperature" ;
VAL_ 1184 TrlrTireLRPresSts_Inv 0 "FALSE" 1 "TRUE" ;
VAL_ 1184 TnDrvOvSpdWrnCstAvlFlg7 0 "FALSE" 1 "TRUE" ;
VAL_ 1184 TnDrvOvSpdWrnCstAvlFlg6 0 "FALSE" 1 "TRUE" ;
VAL_ 1184 TnDrvOvSpdWrnCstAvlFlg5 0 "FALSE" 1 "TRUE" ;
VAL_ 1184 TnDrvOvSpdWrnCstAvlFlg4 0 "FALSE" 1 "TRUE" ;
VAL_ 1184 TnDrvOvSpdWrnCstAvlFlg3 0 "FALSE" 1 "TRUE" ;
VAL_ 1185 TrlrTireLtMdlPres_Inv 0 "FALSE" 1 "TRUE" ;
VAL_ 1185 TrlrTireLtMdlTemp_Inv 0 "FALSE" 1 "TRUE" ;
VAL_ 1185 TnDrvSpdLmtCstAvlFlg2 0 "FALSE" 1 "TRUE" ;
VAL_ 1185 TnDrvSpdLmtCstAvlFlg1 0 "FALSE" 1 "TRUE" ;
VAL_ 1185 TrlrTireLtMdlPresSts 0 "Unknown" 1 "Normal" 2 "Low Pressure" 3 "Malfunction" 4 "Learning in Progress" 5 "Learn Tire" 6 "Tire Learning Complete" 7 "High Pressure" 8 "High Temperature" ;
VAL_ 1185 TrlrTireLtMdlPresSts_Inv 0 "FALSE" 1 "TRUE" ;
VAL_ 1185 TnDrvSpdLmtCstAvlFlg7 0 "FALSE" 1 "TRUE" ;
VAL_ 1185 TnDrvSpdLmtCstAvlFlg6 0 "FALSE" 1 "TRUE" ;
VAL_ 1185 TnDrvSpdLmtCstAvlFlg5 0 "FALSE" 1 "TRUE" ;
VAL_ 1185 TnDrvSpdLmtCstAvlFlg4 0 "FALSE" 1 "TRUE" ;
VAL_ 1185 TnDrvSpdLmtCstAvlFlg3 0 "FALSE" 1 "TRUE" ;
VAL_ 1186 TrlrTireLFPres_Inv 0 "FALSE" 1 "TRUE" ;
VAL_ 1186 TrlrTireLFTemp_Inv 0 "FALSE" 1 "TRUE" ;
VAL_ 1186 TrlrTireLFPresSts 0 "Unknown" 1 "Normal" 2 "Low Pressure" 3 "Malfunction" 4 "Learning in Progress" 5 "Learn Tire" 6 "Tire Learning Complete" 7 "High Pressure" 8 "High Temperature" ;
VAL_ 1186 TrlrTireLFPresSts_Inv 0 "FALSE" 1 "TRUE" ;
VAL_ 1186 TrlrProfSeltnResp 0 "No Action" 1 "Default Profile" 2 "Profile1" 3 "Profile2" 4 "Profile3" 5 "Profile4" 6 "Profile5" 7 "Profile6" 8 "Profile7" 9 "Profile8" 10 "Profile9" 11 "Profile10" 12 "Profile11" 13 "Profile12" 14 "Profile13" 15 "Profile14" 16 "Profile15" 17 "Profile16" 18 "Profile17" 19 "Profile18" 20 "Profile19" 21 "Profile20" ;
VAL_ 1186 TrlrTireLrnSts 0 "Unknown" 1 "Learn Completed" 2 "Learn Progressing" 3 "Learn Failed" 4 "Tires not Learned" ;
VAL_ 1187 TireTmpLF_Inv 0 "FALSE" 1 "TRUE" ;
VAL_ 1187 TireTmpLR_Inv 0 "FALSE" 1 "TRUE" ;
VAL_ 1187 TireTmpRF_Inv 0 "FALSE" 1 "TRUE" ;
VAL_ 1187 TireTmpRR_Inv 0 "FALSE" 1 "TRUE" ;
VAL_ 1361 HVACFCRADSF_LtSet 0 "NoAction" 1 "Auto" 2 "Floor" 3 "FloorAndVent" 4 "Vent" 5 "VentAndWindshield" 6 "Windshield" 7 "FloorAndWindshield" 8 "FloorAndVentAndWindshield" ;
VAL_ 1361 HVACFCRADSF_RtSet 0 "NoAction" 1 "Auto" 2 "Floor" 3 "FloorAndVent" 4 "Vent" 5 "VentAndWindshield" 6 "Windshield" 7 "FloorAndWindshield" 8 "FloorAndVentAndWindshield" ;
VAL_ 1367 HVACFCRRFA_FrshAirSetChg 0 "FALSE" 1 "TRUE" ;
VAL_ 1367 HVACFCRRFA_FrtAutoSetChg 0 "FALSE" 1 "TRUE" ;
VAL_ 1367 HVACFCRRFA_RecircSetChg 0 "FALSE" 1 "TRUE" ;
VAL_ 1372 HVACFCRTLCFR_ORL2 0 "FALSE" 1 "TRUE" ;
VAL_ 1372 HVACFCRTLCFR_ORL1 0 "FALSE" 1 "TRUE" ;
VAL_ 1372 HVACFCRTLCFR_ORH2 0 "FALSE" 1 "TRUE" ;
VAL_ 1372 HVACFCRTLCFR_ORL3 0 "FALSE" 1 "TRUE" ;
VAL_ 1372 HVACFCRTLCFR_ORH1 0 "FALSE" 1 "TRUE" ;
VAL_ 1372 HVACFCRTLCFR_ORH3 0 "FALSE" 1 "TRUE" ;
VAL_ 1372 HVACFCRTLCFR_CktCorr 0 "Indeterminate" 1 "Pass Criteria Met" 2 "Fail Criteria Met" ;
VAL_ 1295 HVACFCRACH_CompSetChg 0 "FALSE" 1 "TRUE" ;
VAL_ 1295 HVACFCRACH_HtrSetChg 0 "FALSE" 1 "TRUE" ;
VAL_ 1295 HVACFCRACH_HtrSet 0 "NoAction" 1 "HEAT_OFF" 2 "HEAT_ON" ;
VAL_ 1295 RHVSLF_HtdCushBckLvlChgDn 0 "FALSE" 1 "TRUE" ;
VAL_ 1295 RHVSLF_HtdBckLvlChgDn 0 "FALSE" 1 "TRUE" ;
VAL_ 1295 RHVSLF_VntLvlChgUp 0 "FALSE" 1 "TRUE" ;
VAL_ 1295 RHVSLF_VntLvlChgDn 0 "FALSE" 1 "TRUE" ;
VAL_ 1295 RHVSLF_HtdCushBckLvlChgUp 0 "FALSE" 1 "TRUE" ;
VAL_ 1295 RHVSLF_HtdBckLvlChgUp 0 "FALSE" 1 "TRUE" ;
VAL_ 1295 HVACFCRL_SetChg 0 "FALSE" 1 "TRUE" ;
VAL_ 1295 HtdStBckCushStckSwLF 0 "FALSE" 1 "TRUE" ;
VAL_ 1295 HVACFrtCtlReqSyncRrSetChg 0 "FALSE" 1 "TRUE" ;
VAL_ 1295 RHVSRF_VntLvlChgUp 0 "FALSE" 1 "TRUE" ;
VAL_ 1295 RHVSRF_HtdCushBckLvlChgUp 0 "FALSE" 1 "TRUE" ;
VAL_ 1295 RHVSRF_HtdCushBckLvlChgDn 0 "FALSE" 1 "TRUE" ;
VAL_ 1295 RHVSRF_VntLvlChgDn 0 "FALSE" 1 "TRUE" ;
VAL_ 1295 RHVSRF_HtdBckLvlChgUp 0 "FALSE" 1 "TRUE" ;
VAL_ 1295 RHVSRF_HtdBckLvlChgDn 0 "FALSE" 1 "TRUE" ;
VAL_ 1295 VntStStckSwRF 0 "FALSE" 1 "TRUE" ;
VAL_ 1295 VntStStckSwLF 0 "FALSE" 1 "TRUE" ;
VAL_ 1295 HtdVntStSwActvRF 0 "FALSE" 1 "TRUE" ;
VAL_ 1295 HtdVntStSwActvLF 0 "FALSE" 1 "TRUE" ;
VAL_ 1295 HtdStBckStckSwRF 0 "FALSE" 1 "TRUE" ;
VAL_ 1295 HtdStBckStckSwLF 0 "FALSE" 1 "TRUE" ;
VAL_ 1295 HtdStBckCushStckSwRF 0 "FALSE" 1 "TRUE" ;
VAL_ 1363 HVACFCRBLCF_ORL1 0 "FALSE" 1 "TRUE" ;
VAL_ 1363 HVACFCRBLCF_ORH2 0 "FALSE" 1 "TRUE" ;
VAL_ 1363 HVACFCRBLCF_ORH1 0 "FALSE" 1 "TRUE" ;
VAL_ 1363 HVACFCRBLCF_ORL2 0 "FALSE" 1 "TRUE" ;
VAL_ 1363 HVACFCRBLCF_CktCorr 0 "Indeterminate" 1 "Pass Criteria Met" 2 "Fail Criteria Met" ;
VAL_ 1365 HVACFCRDP_FrtPwrSetChg_Inv 0 "FALSE" 1 "TRUE" ;
VAL_ 1365 HVACFCRDP_FrtPwrSetChg 0 "FALSE" 1 "TRUE" ;
VAL_ 1365 HVACFCRDP_IntrnlFltSts 0 "Fault1" 1 "Fault2" 2 "Fault3" 3 "Fault4" 4 "Fault5" 5 "Fault6" 6 "Fault7" 7 "Fault8" 8 "Fault9" 9 "Fault10" 10 "Fault11" 11 "Fault12" 12 "Fault13" 13 "Fault14" 14 "Fault15" 15 "Fault16" ;
VAL_ 1365 HVACFCRDP_InitFin 0 "FALSE" 1 "TRUE" ;
VAL_ 1365 HVACFCRDP_HtdFrtWshldSetChgd 0 "FALSE" 1 "TRUE" ;
VAL_ 1365 HVACFCRDP_MaxDefrSetChg 0 "FALSE" 1 "TRUE" ;
VAL_ 1360 HVACFCRADSCF_LtChgNext 0 "FALSE" 1 "TRUE" ;
VAL_ 1360 HVACFCRADSCF_RtChgNext 0 "FALSE" 1 "TRUE" ;
VAL_ 1299 HVACFCRBLR_LvlActv 0 "FALSE" 1 "TRUE" ;
VAL_ 1369 HVACFCRTLCFL_ORL2 0 "FALSE" 1 "TRUE" ;
VAL_ 1369 HVACFCRTLCFL_ORL1 0 "FALSE" 1 "TRUE" ;
VAL_ 1369 HVACFCRTLCFL_ORH3 0 "FALSE" 1 "TRUE" ;
VAL_ 1369 HVACFCRTLCFL_ORH2 0 "FALSE" 1 "TRUE" ;
VAL_ 1369 HVACFCRTLCFL_ORH1 0 "FALSE" 1 "TRUE" ;
VAL_ 1369 HVACFCRTLCFL_ORL3 0 "FALSE" 1 "TRUE" ;
VAL_ 1369 HVACFCRTLCFL_CktCorr 0 "Indeterminate" 1 "Pass Criteria Met" 2 "Fail Criteria Met" ;
VAL_ 1373 HVACFCRTLF_RtLvlActv 0 "FALSE" 1 "TRUE" ;
VAL_ 1373 HVACFCRTLF_LtLvlActv 0 "FALSE" 1 "TRUE" ;
VAL_ 1302 HVACFCRTLR_RtLvlActv 0 "FALSE" 1 "TRUE" ;
VAL_ 1302 HVACFCRTLR_LtLvlActv 0 "FALSE" 1 "TRUE" ;
VAL_ 1271 ADASIS_NAVILINK_FncRdClss 0 "LOCAL" 1 "SFREEWAY" 2 "FREEWAY" 3 "PED-MALL" 4 "HIGHWAY" 5 "ARTERIAL" 6 "ALLEY" 7 "COLLECTOR" ;
VAL_ 1271 ADASIS_NAVILINK_DigMpVerYr 0 "2000" 1 "2001" 2 "2002" 3 "2003" 4 "2004" 5 "2005" 6 "2006" 7 "2007" 8 "2008" 9 "2009" 10 "2010" 11 "2011" 12 "2012" 13 "2013" 14 "2014" 15 "2015" 16 "2016" 17 "2017" 18 "2018" 19 "2019" 20 "2020" 21 "2021" 22 "2022" 23 "2023" 24 "2024" 25 "2025" 26 "2026" 27 "2027" 28 "2028" 29 "2029" 30 "2030" 31 "2031" 32 "2032" 33 "2033" 34 "2034" 35 "2035" 36 "2036" 37 "2037" 38 "2038" 39 "2039" 40 "2040" 41 "2041" 42 "2042" 43 "2043" 44 "2044" 45 "2045" 46 "2046" 47 "2047" 48 "2048" 49 "2049" 50 "2050" 51 "2051" 52 "2052" 53 "2053" 54 "2054" 55 "2055" 56 "2056" 57 "2057" 58 "2058" 59 "2059" 60 "2060" 61 "2061" 62 "2062" 63 "NOT APPLICABLE" ;
VAL_ 1271 ADASIS_NAVILINK_SpdLmtUnt 0 "MILES/H" 1 "KM/H" ;
VAL_ 1271 ADASIS_NAVILINK_SpdLmtPsdSpd_DuD 0 "FALSE" 1 "TRUE" ;
VAL_ 1271 ADASIS_NAVILINK_MpDtAv 0 "NOT VALID" 1 "VALID" ;
VAL_ 1271 ADASIS_NAVILINK_LnCtgry 0 "NO INFO AVAILABLE" 1 "ONE LANE" 2 "TWO OR THREE LANES" 3 "FOUR OR MORE LANES" ;
VAL_ 1271 ADASIS_NAVILINK_DigMpVerQtr 0 "QUARTER 1" 1 "QUARTER 2" 2 "QUARTER 3" 3 "QUARTER 4" ;
VAL_ 1271 ADASIS_NAVILINK_SprtdLnRd 0 "ROAD IS NOT CONTROLLED ACCESS ROAD" 1 "ROAD IS CONTROLLED ACCESS ROAD" ;
VAL_ 1399 VehStbEnhCurrStReq 0 "No action" 1 "OFF" 2 "ON" ;
VAL_ 1399 VehStbCompMdCurrStReq 0 "No action" 1 "OFF" 2 "ON" ;
VAL_ 1399 TCStmpDsblReqConf 0 "No action" 1 "NO" 2 "YES" ;
VAL_ 1399 TCSCurrStReq 0 "No action" 1 "OFF" 2 "ON" ;
VAL_ 1398 CustMdActAeroCstChngSetReq 0 "NO_ACTION" 1 "CUSTOM_MODE_1" 2 "CUSTOM_MODE_2" 3 "CUSTOM_MODE_3" 4 "CUSTOM_MODE_4" 5 "CUSTOM_MODE_5" 6 "CUSTOM_MODE_6" 7 "CUSTOM_MODE_7" ;
VAL_ 1398 CustmPT_CfgPgAct 0 "FALSE" 1 "TRUE" ;
VAL_ 1398 ExtdHillStrtAsstCstChgSetReq 0 "NO_ACTION" 1 "EXTENDED_HOLD" 2 "STANDARD_HOLD" 3 "RESERVED_3" 4 "RESERVED_4" 5 "RESERVED_5" 6 "RESERVED_6" 7 "RESERVED_7" ;
VAL_ 1398 DrvrSeltdConf 0 "NO_ACTION" 1 "SETTINGS_ACCEPTED" 2 "SETTINGS_CANCELED" 3 "MENU_ERROR_EVENT" ;
VAL_ 1398 CustMdTrcStbCstChngSetReq 0 "NO_ACTION" 1 "CUSTOM_MODE_1" 2 "CUSTOM_MODE_2" 3 "CUSTOM_MODE_3" 4 "CUSTOM_MODE_4" 5 "CUSTOM_MODE_5" 6 "CUSTOM_MODE_6" 7 "CUSTOM_MODE_7" ;
VAL_ 1398 CustMdPTCstChngSetReq 0 "NO ACTION" 1 "CUSTOM_MODE_1" 2 "CUSTOM_MODE_2" 3 "CUSTOM_MODE_3" 4 "CUSTOM_MODE_4" 5 "CUSTOM_MODE_5" 6 "CUSTOM_MODE_6" 7 "CUSTOM_MODE_7" ;
VAL_ 1398 CustMdBrkPdlCstChngSetReq 0 "NO_ACTION" 1 "CUSTOM_MODE_1" 2 "CUSTOM_MODE_2" 3 "CUSTOM_MODE_3" 4 "CUSTOM_MODE_4" 5 "CUSTOM_MODE_5" 6 "CUSTOM_MODE_6" 7 "CUSTOM_MODE_7" ;
VAL_ 1375 BatVltOBD_Inv 0 "FALSE" 1 "TRUE" ;
VAL_ 1400 PTExPrtclFltrMnlRgnRq 0 "FALSE" 1 "TRUE" ;
VAL_ 1400 CustmStbCtlRdctReqConf 0 "No Action" 1 "No" 2 "Yes" ;
VAL_ 1383 OTARC_RejCrdntnECP_MC 0 "FALSE" 1 "TRUE" ;
VAL_ 1383 OTARC_RejCrdntnBSM_MH 0 "FALSE" 1 "TRUE" ;
VAL_ 1383 OTARC_RejCrdntnECP_X2 0 "FALSE" 1 "TRUE" ;
VAL_ 1383 OTARC_RejCrdntnECP_X1 0 "FALSE" 1 "TRUE" ;
VAL_ 1383 OTARC_RejCrdntnECM 0 "FALSE" 1 "TRUE" ;
VAL_ 1383 OTARC_RejCrdntnEBCM 0 "FALSE" 1 "TRUE" ;
VAL_ 1383 OTARC_RejCrdntnBSM 0 "FALSE" 1 "TRUE" ;
VAL_ 1383 OTARC_RejCrdntnBCM 0 "FALSE" 1 "TRUE" ;
VAL_ 1383 OTARC_RejCrdntnECU_19 0 "FALSE" 1 "TRUE" ;
VAL_ 1383 OTARC_RejCrdntnECU_18 0 "FALSE" 1 "TRUE" ;
VAL_ 1383 OTARC_RejCrdntnECU_17 0 "FALSE" 1 "TRUE" ;
VAL_ 1383 OTARC_RejCrdntnECU_16 0 "FALSE" 1 "TRUE" ;
VAL_ 1383 OTARC_RejCrdntnECU_15 0 "FALSE" 1 "TRUE" ;
VAL_ 1383 OTARC_RejCrdntnECU_14 0 "FALSE" 1 "TRUE" ;
VAL_ 1383 OTARC_RejCrdntnECU_13 0 "FALSE" 1 "TRUE" ;
VAL_ 1383 OTARC_RejCrdntnECP_S 0 "FALSE" 1 "TRUE" ;
VAL_ 1383 OTARC_RejCrdntnECU_27 0 "FALSE" 1 "TRUE" ;
VAL_ 1383 OTARC_RejCrdntnECU_26 0 "FALSE" 1 "TRUE" ;
VAL_ 1383 OTARC_RejCrdntnECU_25 0 "FALSE" 1 "TRUE" ;
VAL_ 1383 OTARC_RejCrdntnECU_24 0 "FALSE" 1 "TRUE" ;
VAL_ 1383 OTARC_RejCrdntnECU_23 0 "FALSE" 1 "TRUE" ;
VAL_ 1383 OTARC_RejCrdntnECU_22 0 "FALSE" 1 "TRUE" ;
VAL_ 1383 OTARC_RejCrdntnECU_21 0 "FALSE" 1 "TRUE" ;
VAL_ 1383 OTARC_RejCrdntnECU_20 0 "FALSE" 1 "TRUE" ;
VAL_ 1383 OTARC_RejCrdntnTCM 0 "FALSE" 1 "TRUE" ;
VAL_ 1383 OTARC_RejCrdntnICCM 0 "FALSE" 1 "TRUE" ;
VAL_ 1383 OTARC_RejCrdntnFICM 0 "FALSE" 1 "TRUE" ;
VAL_ 1383 OTARC_RejCrdntnECU_32 0 "FALSE" 1 "TRUE" ;
VAL_ 1383 OTARC_RejCrdntnECU_31 0 "FALSE" 1 "TRUE" ;
VAL_ 1383 OTARC_RejCrdntnECU_30 0 "FALSE" 1 "TRUE" ;
VAL_ 1383 OTARC_RejCrdntnECU_29 0 "FALSE" 1 "TRUE" ;
VAL_ 1383 OTARC_RejCrdntnECU_28 0 "FALSE" 1 "TRUE" ;
VAL_ 1077 HMIGI1P_TrlrBrkDispActvAuth 0 "FALSE" 1 "TRUE" ;
VAL_ 1077 HMIGI1P_TrlrBrkDispActvAuth_DuD 0 "FALSE" 1 "TRUE" ;
VAL_ 1077 HMIGI1P_EnvModPrsntRspdr4Auth 0 "FALSE" 1 "TRUE" ;
VAL_ 623 HMIGI2P_LnFllwgInterFltDtdAuth 0 "FALSE" 1 "TRUE" ;
VAL_ 623 HMIGI2P_IPCFlrIndOnAuth 0 "FALSE" 1 "TRUE" ;
VAL_ 1078 HMII1P_ACCSetTypAuth 0 "Manual" 1 "Auto" ;
VAL_ 1078 HMII1P_AutoModeSpdLimCnfrmdAuth 0 "FALSE" 1 "TRUE" ;
VAL_ 1078 HMII1P_ChmSysSOHAuth 0 "Unknown" 1 "Healthy" 2 "Faulted" ;
VAL_ 1078 HMII1P_LnFllwgChInterFltDtdAuth 0 "FALSE" 1 "TRUE" ;
VAL_ 1078 HMII1P_MCRLDOprtlStsAuth 0 "Working as Intended" 1 "Not Working as Intended" 2 "Unknown" ;
VAL_ 1078 HMII1P_IPCDispStsAuth 0 "Unknown" 1 "Normal" 2 "Fault" ;
VAL_ 1059 HMIR1P_MCRLDAnmProfReqAuth 0 "Animation Profile Off" 1 "Animation Profile bulb check" 2 "Animation Profile 1" 3 "Animation Profile 2" 4 "Animation Profile 3" 5 "Animation Profile 4" 6 "Animation Profile 5" 7 "Animation Profile 6" 8 "Animation Profile 7" 9 "Animation Profile 8" 10 "Animation Profile 9" 11 "Animation Profile 10" 12 "Animation Profile 11" 13 "Animation Profile 12" 14 "Animation Profile 13" 15 "Animation Profile 14" 16 "Animation Profile 15" 17 "Animation Profile 16" 18 "Animation Profile 17" 19 "Animation Profile 18" 20 "Animation Profile 19" 21 "Animation Profile 20" 22 "Animation Profile 21" 23 "Animation Profile 22" 24 "Animation Profile 23" 25 "Animation Profile 24" 26 "Animation Profile 25" 27 "Animation Profile 26" 28 "Animation Profile 27" 29 "Animation Profile 28" 30 "Animation Profile 29" 31 "Animation Profile 30" ;
VAL_ 1059 HMIR1P_LnFllwgRHSChEvntStatAuth 0 "No Action" 1 "Active" 2 "Cancel Chime" ;
VAL_ 1059 HMIR1P_MCRLDAnmProfReqAuth_Inv 0 "FALSE" 1 "TRUE" ;
VAL_ 1059 HMIR1P_MCRLDAnmProfReqAuth_DuD 0 "FALSE" 1 "TRUE" ;
VAL_ 1059 HMIR1P_LnFllwgLHSChEvntStatAuth 0 "No Action" 1 "Active" 2 "Cancel Chime" ;
VAL_ 1059 HMIR1P_LnFllwgGenChEvntStatAuth 0 "No Action" 1 "Active" 2 "Cancel Chime" ;
VAL_ 1364 HVACFCRBLF_LvlActv 0 "FALSE" 1 "TRUE" ;
VAL_ 185 HVACFCRTLCFLI2_ORL4 0 "FALSE" 1 "TRUE" ;
VAL_ 185 HVACFCRTLCFLI2_ORH4 0 "FALSE" 1 "TRUE" ;
VAL_ 186 HVACFCRTLCFRI2_ORL4 0 "FALSE" 1 "TRUE" ;
VAL_ 186 HVACFCRTLCFRI2_ORH4 0 "FALSE" 1 "TRUE" ;
VAL_ 1358 HVACICR1_IntrnlFltSts 0 "Fault1" 1 "Fault2" 2 "Fault3" 3 "Fault4" 4 "Fault5" 5 "Fault6" 6 "Fault7" 7 "Fault8" 8 "Fault9" 9 "Fault10" 10 "Fault11" 11 "Fault12" 12 "Fault13" 13 "Fault14" 14 "Fault15" 15 "Fault16" ;
VAL_ 1358 HVACICR1_FrtAutoSetChg 0 "FALSE" 1 "TRUE" ;
VAL_ 1358 HVACICR1_FrtPwrSetChg 0 "FALSE" 1 "TRUE" ;
VAL_ 1358 HVACICR1_HtrSet 0 "NoAction" 1 "HEAT_OFF" 2 "HEAT_ON" ;
VAL_ 1358 HVACICR1_CompSetChg 0 "FALSE" 1 "TRUE" ;
VAL_ 1358 HVACICR1_CompSet 0 "NoAction" 1 "COMP_OFF" 2 "COMP_ON" 3 "COMP_ECON" ;
VAL_ 1358 HVACICR1_MaxDefrSetChg 0 "FALSE" 1 "TRUE" ;
VAL_ 1358 HVACICR1_MaxDefrSet 0 "NoAction" 1 "MaxDefrostOff" 2 "MaxDefrostOn" ;
VAL_ 1358 HVACICR1_HtrSetChg 0 "FALSE" 1 "TRUE" ;
VAL_ 1358 HVACICR1_FrtRrPwrSet 0 "NoAction" 1 "FrontOFF_RearOFF" 2 "FrontON_RearON" 3 "FrontON_RearOFF" 4 "FrontOFF_RearON" ;
VAL_ 1358 HVACICR1_BlwLvlFrtActv 0 "FALSE" 1 "TRUE" ;
VAL_ 1359 HVACICR2_AirDstRtSet 0 "NoAction" 1 "Auto" 2 "Floor" 3 "FloorAndVent" 4 "Vent" 5 "VentAndWindshield" 6 "Windshield" 7 "FloorAndWindshield" 8 "FloorAndVentAndWindshield" ;
VAL_ 1359 HVACICR2_AirDstLtSet 0 "NoAction" 1 "Auto" 2 "Floor" 3 "FloorAndVent" 4 "Vent" 5 "VentAndWindshield" 6 "Windshield" 7 "FloorAndWindshield" 8 "FloorAndVentAndWindshield" ;
VAL_ 1359 HVACICR2_RecircSet 0 "NoAction" 1 "FreshAir" 2 "Recirc" ;
VAL_ 1359 HVACICR2_AirDstLtChgPrev 0 "FALSE" 1 "TRUE" ;
VAL_ 1359 HVACICR2_AirDstLtChgNext 0 "FALSE" 1 "TRUE" ;
VAL_ 1359 HVACICR2_TempLtLvlActv 0 "FALSE" 1 "TRUE" ;
VAL_ 1359 HVACICR2_AirDstRtChgNext 0 "FALSE" 1 "TRUE" ;
VAL_ 1359 HVACICR2_TempRtLvlActv 0 "FALSE" 1 "TRUE" ;
VAL_ 1359 HVACICR2_RecircSetChg 0 "FALSE" 1 "TRUE" ;
VAL_ 1359 HVACICR2_AirDstRtChgPrev 0 "FALSE" 1 "TRUE" ;
VAL_ 1303 ReqRrClmtApp 0 "FALSE" 1 "TRUE" ;
VAL_ 1303 ReqFrtClmtApp 0 "FALSE" 1 "TRUE" ;
VAL_ 1303 HVACFCRADR_LtChgNext 0 "FALSE" 1 "TRUE" ;
VAL_ 1303 HVACFCRADR_RtSet 0 "NoAction" 1 "Auto" 2 "Floor" 3 "FloorAndVent" 4 "Vent" 5 "VentAndRoof" 6 "Roof" 7 "RoofAndFloor" 8 "FloorAndVentAndRoof" ;
VAL_ 1303 HVACFCRADR_RtChgNext 0 "FALSE" 1 "TRUE" ;
VAL_ 1303 HVACFCRRA_SetChg 0 "FALSE" 1 "TRUE" ;
VAL_ 1303 HVACFCRADR_LtSet 0 "NoAction" 1 "Auto" 2 "Floor" 3 "FloorAndVent" 4 "Vent" 5 "VentAndRoof" 6 "Roof" 7 "RoofAndFloor" 8 "FloorAndVentAndRoof" ;
VAL_ 1303 HVACFCRRD_SetChg 0 "FALSE" 1 "TRUE" ;
VAL_ 1303 HVACFCRRP_SetChg 0 "FALSE" 1 "TRUE" ;
VAL_ 1354 HVACFCRSA_SetChg 0 "FALSE" 1 "TRUE" ;
VAL_ 1352 HtdStrgWhlSwActv_HVAC_FP_F 0 "FALSE" 1 "TRUE" ;
VAL_ 1352 ManHtdStrgWhlReqd_HVAC_FP_F 0 "FALSE" 1 "TRUE" ;
VAL_ 1352 ManHtdStrgWhlReqd_HVAC_FP_F_Inv 0 "FALSE" 1 "TRUE" ;
VAL_ 1352 HtdStrgWhlStkSw_HVAC_FP_F 0 "FALSE" 1 "TRUE" ;
VAL_ 1352 HtdStrgWhlStkSw_HVAC_FP_F_Inv 0 "FALSE" 1 "TRUE" ;
VAL_ 1397 RHVSRR_HtdBckLvlChgUp 0 "FALSE" 1 "TRUE" ;
VAL_ 1397 RHVSRR_HtdBckLvlChgDn 0 "FALSE" 1 "TRUE" ;
VAL_ 1397 RHVSLR_VntLvlChgUp 0 "FALSE" 1 "TRUE" ;
VAL_ 1397 RHVSLR_VntLvlChgDn 0 "FALSE" 1 "TRUE" ;
VAL_ 1397 RHVSLR_HtdCushBckLvlChgUp 0 "FALSE" 1 "TRUE" ;
VAL_ 1397 RHVSLR_HtdCushBckLvlChgDn 0 "FALSE" 1 "TRUE" ;
VAL_ 1397 RHVSLR_HtdBckLvlChgUp 0 "FALSE" 1 "TRUE" ;
VAL_ 1397 RHVSLR_HtdBckLvlChgDn 0 "FALSE" 1 "TRUE" ;
VAL_ 1397 HtdStBckStckSwRR 0 "FALSE" 1 "TRUE" ;
VAL_ 1397 HtdStBckStckSwLR 0 "FALSE" 1 "TRUE" ;
VAL_ 1397 HtdStBckCushStckSwRR 0 "FALSE" 1 "TRUE" ;
VAL_ 1397 HtdStBckCushStckSwLR 0 "FALSE" 1 "TRUE" ;
VAL_ 1397 RHVSRR_VntLvlChgUp 0 "FALSE" 1 "TRUE" ;
VAL_ 1397 RHVSRR_VntLvlChgDn 0 "FALSE" 1 "TRUE" ;
VAL_ 1397 RHVSRR_HtdCushBckLvlChgUp 0 "FALSE" 1 "TRUE" ;
VAL_ 1397 RHVSRR_HtdCushBckLvlChgDn 0 "FALSE" 1 "TRUE" ;
VAL_ 1397 VntStStckSwRR 0 "FALSE" 1 "TRUE" ;
VAL_ 1397 VntStStckSwLR 0 "FALSE" 1 "TRUE" ;
VAL_ 1397 HtdVntStSwActvRR 0 "FALSE" 1 "TRUE" ;
VAL_ 1397 HtdVntStSwActvLR 0 "FALSE" 1 "TRUE" ;
VAL_ 1310 FCSS1_FrtCntrStckSldr1Prxmty 0 "NOPROXIMITY_NOTOUCH" 1 "PROXIMITY_DETECTED" 2 "TOUCH_DETECTED" 3 "RESERVED" ;
VAL_ 1310 FCSS2_FrtCntrStckSldr2Prxmty 0 "NOPROXIMITY_NOTOUCH" 1 "PROXIMITY_DETECTED" 2 "TOUCH_DETECTED" 3 "RESERVED" ;
VAL_ 1310 FCSS3_FrtCntrStckSldr3Prxmty 0 "NOPROXIMITY_NOTOUCH" 1 "PROXIMITY_DETECTED" 2 "TOUCH_DETECTED" 3 "RESERVED" ;
VAL_ 1311 FCSTP34_FrtCntrStckTchFlg3 0 "FALSE" 1 "TRUE" ;
VAL_ 1311 FCSTP34_FrtCntrStckTchFlg4 0 "FALSE" 1 "TRUE" ;
VAL_ 1312 FCSTP12_FrtCntrStckTchFlg2 0 "FALSE" 1 "TRUE" ;
VAL_ 1312 FCSTP12_FrtCntrStckTchFlg1 0 "FALSE" 1 "TRUE" ;
VAL_ 1312 StrgeOpn 0 "FALSE" 1 "TRUE" ;
VAL_ 1313 FrtCntrStckPriVidInLckd 0 "Not_Locked" 1 "Locked" ;
VAL_ 1313 FrtCntrStckLVMVidInLckd 0 "Not_Locked" 1 "Locked" ;
VAL_ 1418 PwrtrnExhPrtclFiltManRegnReq 0 "FALSE" 1 "TRUE" ;
VAL_ 1316 VehFlRngCalc_Inv 0 "FALSE" 1 "TRUE" ;
VAL_ 1316 FuelLvlLoIndOn 0 "FALSE" 1 "TRUE" ;
VAL_ 1316 PTExPrtclFltrMnlRgnDispPrsnt 0 "FALSE" 1 "TRUE" ;
VAL_ 1317 FllwgDstIndTmDstSel 0 "TIME" 1 "DISTANCE" ;
VAL_ 1318 ChmMngrSoH 0 "UNKNOWN" 1 "INITIALIZED" 2 "RESERVED_2" 3 "RESERVED_3" 4 "RESERVED_4" 5 "RESERVED_5" 6 "RESERVED_6" 7 "RESERVED_7" ;
VAL_ 1318 StrWhlCtlVolUpSw 0 "Released" 1 "Pressed" ;
VAL_ 1318 StrWhlCtlVolDnSw 0 "Released" 1 "Pressed" ;
VAL_ 1318 StrWhlCtlPshToTlkSw 0 "Released" 1 "Pressed" ;
VAL_ 1318 StrWhlCtlFvrtUpSw 0 "Released" 1 "Pressed" ;
VAL_ 1318 StrWhlCtlFvrtDnSw 0 "Released" 1 "Pressed" ;
VAL_ 1318 StrWhlCtlEndSw 0 "Released" 1 "Pressed" ;
VAL_ 1319 VehFlRngLwIO 0 "FALSE" 1 "TRUE" ;
VAL_ 1319 TrnsOilLfRstRq 0 "No Request" 1 "Reset Request Active" ;
VAL_ 1319 TPSnsrProgEvReq 0 "FALSE" 1 "TRUE" ;
VAL_ 1319 FobProgEvntRqd 0 "FALSE" 1 "TRUE" ;
VAL_ 1319 EngOilLifeRstReq 0 "FALSE" 1 "TRUE" ;
VAL_ 1319 LnchCtlWhlSlReq 0 "No Action" 1 "Five Percent" 2 "Five And A Half Percent" 3 "Six Percent" 4 "Six And A Half Percent" 5 "Seven Percent" 6 "Seven And A Half Percent" 7 "Eight Percent" 8 "Eight And A Half Percent" 9 "Nine Percent" 10 "Nine And A Half Percent" 11 "Ten Percent" 12 "Ten And A Half Percent" 13 "Eleven Percent" 14 "Eleven And a Half Percent" 15 "Twelve Percent" 16 "Twelve And A Half Percent" 17 "Thirteen Percent" 18 "Thirteen And A Half Percent" 19 "Fourteen Percent" 20 "Fourteen And A Half Percent" 21 "Fifteen Percent" ;
VAL_ 1319 LnchCtlEngRPMReq 0 "No Action" 1 "800" 2 "900" 3 "1000" 4 "1100" 5 "1200" 6 "1300" 7 "1400" 8 "1500" 9 "1600" 10 "1700" 11 "1800" 12 "1900" 13 "2000" 14 "2100" 15 "2200" 16 "2300" 17 "2400" 18 "2500" 19 "2600" 20 "2700" 21 "2800" 22 "2900" 23 "3000" 24 "3100" 25 "3200" 26 "3300" 27 "3400" 28 "3500" 29 "3600" 30 "3700" 31 "3800" 32 "3900" 33 "4000" 34 "FlexibleRPM 1" 35 "FlexibleRPM 2" 36 "FlexibleRPM 3" 37 "FlexibleRPM 4" 38 "FlexibleRPM 5" ;
VAL_ 1319 AutoTransGrDispdVal 0 "None" 1 "P" 2 "R" 3 "N" 4 "D" 5 "D1" 6 "D2" 7 "D3" 8 "D4" 9 "D5" 10 "D6" 11 "D7" 12 "D8" 13 "D9" 14 "D10" 15 "First(1)" 16 "Second(2)" 17 "Third(3)" 18 "Fourth(4)" 19 "Fifth(5)" 20 "Sixth(6)" 21 "Seventh(7)" 22 "Eighth(8)" 23 "Ninth(9)" 24 "M" 25 "M1" 26 "M2" 27 "M3" 28 "M4" 29 "M5" 30 "M6" 31 "M7" 32 "M8" 33 "M9" 34 "M10" 35 "L" 36 "L1" 37 "L2" 38 "L3" 39 "L4" 40 "L5" 41 "L6" 42 "L7" 43 "L8" 44 "L9" 45 "L10" 46 "I" 47 "Park In Progress" 48 "Reverse In Progress" 49 "Neutral In Progress" 50 "Drive In Progress" 51 "Dbar1" 52 "Dbar2" 53 "Dbar3" 54 "Dbar4" 55 "Dbar5" 56 "Dbar6" 57 "Dbar7" 58 "Dbar8" 59 "Dbar9" 60 "Dbar10" 61 "Manual In Progress" ;
VAL_ 1319 AutoTransGrDispdVal_Inv 0 "FALSE" 1 "TRUE" ;
VAL_ 1319 LnchCtlRelLineLckReqd 0 "FALSE" 1 "TRUE" ;
VAL_ 1319 LnchCtlModeReq 0 "No Action" 1 "Automatic" 2 "Custom" 3 "Line Lock" ;
VAL_ 1320 Trip1Odo_Inv 0 "FALSE" 1 "TRUE" ;
VAL_ 1320 Trip2Odo_Inv 0 "FALSE" 1 "TRUE" ;
VAL_ 1320 RdHgtAtLocStorConf 0 "No Action" 1 "Store" 2 "Clear" 3 "All Clear" 4 "Undo Delete" ;
VAL_ 1320 BrkPadLifeSysDrvrReq 0 "No Action" 1 "Disable" 2 "Enable" 3 "Reset Front" 4 "Reset Rear" ;
VAL_ 1320 TransOilFiltLifeRstReq 0 "No Request" 1 "Reset Request Active" ;
VAL_ 1320 TPMTrLdnRstReq 0 "UNKNOWN" 1 "LIGHT LOAD" 2 "BEST ECONOMY LOAD" 3 "MAX LOAD" ;
VAL_ 1320 EngAirFiltMonDrvrReq 0 "No Action" 1 "Enable" 2 "Disable" 3 "Reset" ;
VAL_ 1321 IPC_RunCrnkInpActv_Inv 0 "FALSE" 1 "TRUE" ;
VAL_ 1321 HUD_RclCmpt 0 "No Recall Requested" 1 "Recall In Process" 2 "Recall Complete" ;
VAL_ 1321 DispMeasSysExtnd 0 "US" 1 "IMPERIAL" 2 "Metric KM/L" 3 "Metric L/100KM" ;
VAL_ 1321 ClstrAnmStat 0 "Uninitialized" 1 "Ready" 2 "WelcomePlay" 3 "StartPlay" 4 "ShutdownPlay" ;
VAL_ 1321 DispMeasSys 0 "Metric" 1 "English" ;
VAL_ 1321 ClstrHMI_Rdy 0 "FALSE" 1 "TRUE" ;
VAL_ 1321 APARghtSftBtnStatIPC 0 "NOT_PRESSED" 1 "PRESSED" ;
VAL_ 1321 APALftSftBtnStatIPC 0 "NOT_PRESSED" 1 "PRESSED" ;
VAL_ 1321 APAFcStatIPC 0 "NO_FOCUS" 1 "FOCUS" ;
VAL_ 1321 IPC_RunCrnkInpActv 0 "FALSE" 1 "TRUE" ;
VAL_ 1321 PAMutDrvrReq 0 "No Action" 1 "Mute Requested" 2 "Unmute Requested" ;
VAL_ 1321 HUD_CustSelActvStat_Inv 0 "FALSE" 1 "TRUE" ;
VAL_ 1321 TSMWrngPopUpSts 0 "TSM Warning Off" 1 "TSM Warning On" ;
VAL_ 1321 TSMSgnNtfnWrnDispd 0 "FALSE" 1 "TRUE" ;
VAL_ 1321 TSMPageDispActv 0 "FALSE" 1 "TRUE" ;
VAL_ 1321 TSMCustRstReq 0 "FALSE" 1 "TRUE" ;
VAL_ 1321 StkHUD_CustSelStat 0 "FALSE" 1 "TRUE" ;
VAL_ 1321 HUD_CustSelActvStat 0 "FALSE" 1 "TRUE" ;
VAL_ 1321 StrgWhlCtlInCarVcCommCtlSw 0 "Released" 1 "Pressed" ;
VAL_ 1321 NtVsnVidCntrstUserReq 0 "No Action" 1 "Increase" 2 "Decrease" 3 "Set to default" ;
VAL_ 1321 NtVsnVidBrghtnsUserReq 0 "No Action" 1 "Increase" 2 "Decrease" 3 "Set to default" ;
VAL_ 1321 FuelFiltLifeRstReqd 0 "FALSE" 1 "TRUE" ;
VAL_ 613 JmpStrtReqd 0 "FALSE" 1 "TRUE" ;
VAL_ 1273 BklghtngCnfg 0 "Off" 1 "On" 2 "Local" ;
VAL_ 1275 HVACICRADSR_LtSet 0 "NoAction" 1 "Auto" 2 "Floor" 3 "FloorAndVent" 4 "Vent" 5 "VentAndRoof" 6 "Roof" 7 "RoofAndFloor" 8 "FloorAndVentAndRoof" ;
VAL_ 1275 HVACICRADSR_RtSet 0 "NoAction" 1 "Auto" 2 "Floor" 3 "FloorAndVent" 4 "Vent" 5 "VentAndRoof" 6 "Roof" 7 "RoofAndFloor" 8 "FloorAndVentAndRoof" ;
VAL_ 1275 HVACICRBLR_LvlActv 0 "FALSE" 1 "TRUE" ;
VAL_ 1275 HVACInfoCtlReqRrLckSetChg 0 "FALSE" 1 "TRUE" ;
VAL_ 1275 HVACInfoCtlReqRrDfgSetChg 0 "FALSE" 1 "TRUE" ;
VAL_ 1275 HVACInfoCtlReqRrAutoSetChg 0 "FALSE" 1 "TRUE" ;
VAL_ 1275 HVACInfoCtlReqRrDfgSet 0 "NoAction" 1 "RearDefogOFF" 2 "RearDefogON" ;
VAL_ 1275 HVACInfoCtlReqSyncSet 0 "NoAction" 1 "SYNC_all" 2 "UnSYNC_all" 3 "SYNC_Rear_to_Driver" 4 "UnSYNC_Rear_to_Driver" ;
VAL_ 1275 HVACInfoCtlReqSyncRrSetChg 0 "FALSE" 1 "TRUE" ;
VAL_ 1275 HVACInfoCtlReqSyncAllSetChg 0 "FALSE" 1 "TRUE" ;
VAL_ 1275 HVACInfoCtlReqRrPwrSetChg 0 "FALSE" 1 "TRUE" ;
VAL_ 1276 HVACICRTLR_LtLvlActv 0 "FALSE" 1 "TRUE" ;
VAL_ 1276 HVACICRTLR_RtLvlActv 0 "FALSE" 1 "TRUE" ;
VAL_ 1276 HVACInfoCtlReqBlwSpdRdct 0 "FALSE" 1 "TRUE" ;
VAL_ 1276 CSI_ChmPrdcrSOH 0 "Unknown" 1 "Healthy" 2 "Faulted" ;
VAL_ 1277 HVACICRADSCR_LtChgNext 0 "FALSE" 1 "TRUE" ;
VAL_ 1277 HVACICRADSCR_RtChgNext 0 "FALSE" 1 "TRUE" ;
VAL_ 1278 TeenDrvReq 0 "No Action" 1 "Verify Teen PIN" 2 "Update Teen PIN" 3 "Set Teen Key" 4 "Clear Teen Key" 5 "Check for Teen Key" 6 "Clear Teen Keys and PIN" 7 "Reset Report Card" 8 "Request Report Card Data" ;
VAL_ 1278 Ftr6AlrmReq 0 "No Action" 1 "Set Request" 2 "Cancel Request" ;
VAL_ 1278 LnChgAlrtCstChngSetReq 0 "NO_ACTION" 1 "OFF" 2 "ON" 3 "RESERVED_3" 4 "RESERVED_4" 5 "RESERVED_5" 6 "RESERVED_6" 7 "RESERVED_7" ;
VAL_ 1278 TCP_LCMFileTrans 0 "No Action" 1 "Begin Transfer" 2 "Successful Block Transfer" 3 "Cancel Transfer" 4 "Retry Last Block" ;
VAL_ 1278 TCP_LCMDataMsgStat 0 "No Action" 1 "Acknowledge" ;
VAL_ 1278 IPC_LCMDataMsgStat 0 "No Action" 1 "Acknowledge" ;
VAL_ 1278 CamVidICS_DispAct 0 "FALSE" 1 "TRUE" ;
VAL_ 1278 ValetMdReq 0 "NoAction" 1 "SetPIN" 2 "ClearPIN" ;
VAL_ 1279 LngSelExt 0 "NA English" 1 "German" 2 "Italian" 3 "Swedish" 4 "French" 5 "Spanish" 6 "Dutch" 7 "Portuguese" 8 "Norwegian" 9 "Finnish" 10 "Danish" 11 "Greek" 12 "Japanese" 13 "Arabic" 14 "Standard Chinese" 15 "Polish" 16 "Turkish" 17 "Korean" 18 "Traditional Chinese" 19 "UK English" 20 "Hungarian" 21 "Czech" 22 "Slovak" 23 "Russian" 24 "Brazilian Portuguese" 25 "Thai" 26 "Bulgarian" 27 "Romanian" 28 "Slovenian" 29 "Croatian" 30 "Ukrainian" 31 "NA French" 32 "NA Spanish" 33 "Cantonese" 34 "Uzbek" 35 "Serbian" 36 "Lithuanian" 37 "Estonian" 38 "Latvian" 39 "Macedonian" 40 "AU English" 41 "ZA English" ;
VAL_ 1279 IPC_LCMFileTrans 0 "No Action" 1 "Begin Transfer" 2 "Successful Block Transfer" 3 "Cancel Transfer" 4 "Retry Last Block" ;
VAL_ 1280 VehLctrLtsCstChgSetReq 0 "NO_ACTION" 1 "OFF" 2 "ON" 3 "RESERVED_3" 4 "RESERVED_4" 5 "RESERVED_5" 6 "RESERVED_6" 7 "RESERVED_7" ;
VAL_ 1280 TrlrMirVidGdlnsCstChgSetReq 0 "No_Action" 1 "Off" 2 "On" ;
VAL_ 1280 TrlrMirVidEnblCstChgSetReq 0 "No_Action" 1 "Off" 2 "On" ;
VAL_ 1280 APARghtSftBtnStat 0 "NOT_PRESSED" 1 "PRESSED" ;
VAL_ 1280 APAPrllPrkSftBtnStat 0 "NOT_PRESSED" 1 "PRESSED" ;
VAL_ 1280 ElvtdIdlCstChgSetReq 0 "No Action" 1 "Off" 2 "On" ;
VAL_ 1280 WlkAwyLckCstChgSetReq 0 "NO_ACTION" 1 "OFF" 2 "ON" 3 "ON_WITH_CHIRP" 4 "RESERVED_4" 5 "RESERVED_5" 6 "RESERVED_6" 7 "RESERVED_7" ;
VAL_ 1280 StBltShfIntlkCstChgSetReq 0 "NO ACTION" 1 "OFF" 2 "ON" 3 "RESERVED 3" 4 "RESERVED 4" 5 "RESERVED 5" 6 "RESERVED 6" 7 "RESERVED 7" ;
VAL_ 1280 TimeDispFormat 0 "12 Hour Mode" 1 "24 Hour Mode" ;
VAL_ 1280 RstrCstDfltReq 0 "FALSE" 1 "TRUE" ;
VAL_ 1280 RFStStsDispActv 0 "FALSE" 1 "TRUE" ;
VAL_ 1280 LFStStsDispActv 0 "FALSE" 1 "TRUE" ;
VAL_ 1280 APASrchSftBtnStat 0 "NOT_PRESSED" 1 "PRESSED" ;
VAL_ 1280 TnDrvStBltShfIntlkCstChgSetReq 0 "NO_ACTION" 1 "OFF" 2 "ON" 3 "RESERVED_3" 4 "RESERVED_4" 5 "RESERVED_5" 6 "RESERVED_6" 7 "RESERVED_7" ;
VAL_ 1281 RlkRtUlkDrCstChSetReq 0 "NO_ACTION" 1 "OFF" 2 "ON" 3 "RESERVED_3" 4 "RESERVED_4" 5 "RESERVED_5" 6 "RESERVED_6" 7 "RESERVED_7" ;
VAL_ 1281 RevTltMrCstChgSetReq 0 "NO_ACTION" 1 "OFF" 2 "DRIVER" 3 "PASSENGER" 4 "DRIVER_AND_PASSENGER" 5 "RESERVED_5" 6 "RESERVED_6" 7 "RESERVED_7" ;
VAL_ 1281 RemWndOpCstChgSetReq 0 "NO_ACTION" 1 "OFF" 2 "ON" 3 "RESERVED_3" 4 "RESERVED_4" 5 "RESERVED_5" 6 "RESERVED_6" 7 "RESERVED_7" ;
VAL_ 1281 RnSnsCstChgSetReq 0 "NO_ACTION" 1 "OFF" 2 "ON" 3 "RESERVED_3" 4 "RESERVED_4" 5 "RESERVED_5" 6 "RESERVED_6" 7 "RESERVED_7" ;
VAL_ 1281 RmtStrtHtdStCstChgSetReq 0 "NO_ACTION" 1 "OFF" 2 "ON" 3 "RESERVED_3" 4 "RESERVED_4" 5 "RESERVED_5" 6 "RESERVED_6" 7 "RESERVED_7" ;
VAL_ 1281 RmtStrtCoolStCstChgSetReq 0 "NO_ACTION" 1 "OFF" 2 "ON" 3 "RESERVED_3" 4 "RESERVED_4" 5 "RESERVED_5" 6 "RESERVED_6" 7 "RESERVED_7" ;
VAL_ 1281 RnngBrdManDplyCstChgSetReq 0 "NO_ACTION" 1 "OFF" 2 "EXTEND_DOOR" 3 "EXTEND_BED" 4 "RESERVED_4 RESERVED_5" 5 "RESERVED_6" 6 "RESERVED_7" ;
VAL_ 1281 RnngBrdAutoDplyCstChgSetReq 0 "NO_ACTION" 1 "OFF" 2 "DOOR" 3 "DOOR_PARK" 4 "RESERVED_4 RESERVED_5" 5 "RESERVED_6" 6 "RESERVED_7" ;
VAL_ 1281 RrPCMRspTypCstChgSetReq 0 "NO_ACTION" 1 "OFF" 2 "ALERT" 3 "ALERT_AND_BRAKE" 4 "ALERT_AND_BRAKE_AND_STEER" 5 "RESERVED_5" 6 "RESERVED_6" 7 "RESERVED_7" ;
VAL_ 1281 RrDfgStUpCstChgSetReq 0 "NO_ACTION" 1 "MANUAL" 2 "AUTOMATIC" 3 "RESERVED_3" 4 "RESERVED_4" 5 "RESERVED_5" 6 "RESERVED_6" 7 "RESERVED_7" ;
VAL_ 1281 RrCrsTrfcAlrtCstChngSetReq 0 "NO_ACTION" 1 "OFF" 2 "ALERT" 3 "ALERT AND BRAKE" 4 "RESERVED_4" 5 "RESERVED_5" 6 "RESERVED_6" 7 "RESERVED_7" ;
VAL_ 1281 RtLkFdbkCstChgSetReq 0 "NO_ACTION" 1 "HORN_AND_LIGHTS_OFF" 2 "HORN_AND_LIGHTS_ON" 3 "FLASH_LIGHTS_ONLY" 4 "HORN_CHIRP_ONLY" 5 "RESERVED_5" 6 "RESERVED_6" 7 "RESERVED_7" ;
VAL_ 1281 RrVwPrkAstSymCstChgSetReq 0 "NO_ACTION" 1 "OFF" 2 "ON" 3 "RESERVED_3" 4 "RESERVED_4" 5 "RESERVED_5" 6 "RESERVED_6" 7 "RESERVED_7" ;
VAL_ 1281 RrStRmndrEnblDsblCstChgSetReq 0 "No_Action" 1 "Off" 2 "On" ;
VAL_ 1281 SBZAlrtCstChngSetReq 0 "NO_ACTION" 1 "OFF" 2 "ON" 3 "RESERVED_3" 4 "RESERVED_4" 5 "RESERVED_5" 6 "RESERVED_6" 7 "RESERVED_7" ;
VAL_ 1281 RtUlkLtFbCstChgSetReq 0 "NO_ACTION" 1 "OFF" 2 "FLASH_LIGHTS_ON" 3 "RESERVED_3" 4 "RESERVED_4" 5 "RESERVED_5" 6 "RESERVED_6" 7 "RESERVED_7" ;
VAL_ 1281 StBltTghtngCstChgSetReq 0 "NO_ACTION" 1 "OFF" 2 "ON" 3 "RESERVED_3" 4 "RESERVED_4" 5 "RESERVED_5" 6 "RESERVED_6" 7 "RESERVED_7" ;
VAL_ 1281 SrrndVwLghtCstChgSetReq 0 "SETTING_UNKNOWN" 1 "ON" 2 "OFF" 3 "RESERVED_3" 4 "RESERVED_4" 5 "RESERVED_5" 6 "RESERVED_6" 7 "RESERVED_7" ;
VAL_ 1281 SelUlkCstChgSetReq 0 "NO_ACTION" 1 "DRIVER_DOOR_ONLY" 2 "ALL_DOORS" 3 "RESERVED_3" 4 "RESERVED_4" 5 "RESERVED_5" 6 "RESERVED_6" 7 "RESERVED_7" ;
VAL_ 1281 APALftSftBtnStat 0 "NOT_PRESSED" 1 "PRESSED" ;
VAL_ 1281 TrffcLgtAsstCstChgSetReq 0 "NO_ACTION" 1 "OFF" 2 "ALERT" 3 "RESERVED_3" 4 "RESERVED_4" 5 "RESERVED_5" 6 "RESERVED_6" 7 "RESERVED_7" ;
VAL_ 1281 TnDrvSpdLmtCstChgStReq 0 "NO_ACTION" 1 "OFF" 2 "ON" 3 "RESERVED_3" 4 "RESERVED_4" 5 "RESERVED_5" 6 "RESERVED_6" 7 "RESERVED_7" ;
VAL_ 1282 LvlgSysAlgnMdCstChgSetReq 0 "No Action" 1 "Off" 2 "On" ;
VAL_ 1282 LtRtHnTrCstChgSetReq 0 "NO_ACTION" 1 "LEFT_HAND_DRIVE" 2 "RIGHT_HAND_DRIVE" 3 "AUTOMATIC_WITH_GPS" 4 "RESERVED_4" 5 "RESERVED_5" 6 "RESERVED_6" 7 "RESERVED_7" ;
VAL_ 1282 LDCLCstChgSetReq 0 "NO_ACTION" 1 "OFF" 2 "ON" 3 "RESERVED_3" 4 "RESERVED_4" 5 "RESERVED_5" 6 "RESERVED_6" 7 "RESERVED_7" ;
VAL_ 1282 OpDrAtLOCstChgSetReq 0 "NO_ACTION" 1 "OFF" 2 "ON" 3 "RESERVED_3" 4 "RESERVED_4" 5 "RESERVED_5" 6 "RESERVED_6" 7 "RESERVED_7" ;
VAL_ 1282 LvlgSysServMdCstChgSetReq 0 "No Action" 1 "Off" 2 "On" ;
VAL_ 1282 LvlgSysEntEgrsMdCstChgSetReq 0 "No Action" 1 "Off" 2 "On" ;
VAL_ 1282 PlltnCtrlCstChgSetReq 0 "NO_ACTION" 1 "OFF" 2 "ON" 3 "RESERVED_3" 4 "RESERVED_4" 5 "RESERVED_5" 6 "RESERVED_6" 7 "RESERVED_7" ;
VAL_ 1282 PhnLtInVehCstChgSetReq 0 "NO_ACTION" 1 "OFF" 2 "ON" 3 "RESERVED_3" 4 "RESERVED_4" 5 "RESERVED_5" 6 "RESERVED_6" 7 "RESERVED_7" ;
VAL_ 1282 PrsnlMdActAeroCstChngSetReq 0 "NO_ACTION" 1 "PERSONAL_MODE_1" 2 "PERSONAL_MODE_2" 3 "PERSONAL_MODE_3" 4 "PERSONAL_MODE_4" 5 "PERSONAL_MODE_5" 6 "PERSONAL_MODE_6" 7 "PERSONAL_MODE_7" ;
VAL_ 1282 PrkAsstTrHtchPsntCstChgSetReq 0 "NO_ACTION" 1 "OFF_NOT_ATTACHED" 2 "ON_ATTACHED" 3 "RESERVED_3" 4 "RESERVED_4" 5 "RESERVED_5" 6 "RESERVED_6" 7 "RESERVED_7" ;
VAL_ 1282 PrkAsstOnOffCstChgSetReq 0 "No_Action" 1 "Off" 2 "Alert" 3 "Alert_Brake" ;
VAL_ 1282 PrsnlMdRideHghtCstChngSetReq 0 "NO_ACTION" 1 "PERSONAL_MODE_1" 2 "PERSONAL_MODE_2" 3 "PERSONAL_MODE_3" 4 "PERSONAL_MODE_4" 5 "PERSONAL_MODE_5" 6 "PERSONAL_MODE_6" 7 "PERSONAL_MODE_7" ;
VAL_ 1282 PrsnlMdDrvlCstChngSetReq 0 "NO_ACTION" 1 "PERSONAL_MODE_1" 2 "PERSONAL_MODE_2" 3 "PERSONAL_MODE_3" 4 "PERSONAL_MODE_4" 5 "PERSONAL_MODE_5" 6 "PERSONAL_MODE_6" 7 "PERSONAL_MODE_7" ;
VAL_ 1282 PrsnlMdBrkPdlCstChngSetReq 0 "NO_ACTION" 1 "PERSONAL_MODE_1" 2 "PERSONAL_MODE_2" 3 "PERSONAL_MODE_3" 4 "PERSONAL_MODE_4" 5 "PERSONAL_MODE_5" 6 "PERSONAL_MODE_6" 7 "PERSONAL_MODE_7" ;
VAL_ 1282 PrsnlMdSpnCstChngSetReq 0 "NO_ACTION" 1 "PERSONAL_MODE_1" 2 "PERSONAL_MODE_2" 3 "PERSONAL_MODE_3" 4 "PERSONAL_MODE_4" 5 "PERSONAL_MODE_5" 6 "PERSONAL_MODE_6" 7 "PERSONAL_MODE_7" ;
VAL_ 1282 PrsnlMdSndCstChngSetReq 0 "NO_ACTION" 1 "PERSONAL_MODE_1" 2 "PERSONAL_MODE_2" 3 "PERSONAL_MODE_3" 4 "PERSONAL_MODE_4" 5 "PERSONAL_MODE_5" 6 "PERSONAL_MODE_6" 7 "PERSONAL_MODE_7" ;
VAL_ 1282 PsvUnlckCstChgSetReq 0 "NO_ACTION" 1 "DRIVER_DOOR" 2 "ALL_DOORS" 3 "OFF" 4 "RESERVED_4" 5 "RESERVED_5" 6 "RESERVED_6" 7 "RESERVED_7" ;
VAL_ 1282 PrsnlMdStrCstChngSetReq 0 "NO_ACTION" 1 "PERSONAL_MODE_1" 2 "PERSONAL_MODE_2" 3 "PERSONAL_MODE_3" 4 "PERSONAL_MODE_4" 5 "PERSONAL_MODE_5" 6 "PERSONAL_MODE_6" 7 "PERSONAL_MODE_7" ;
VAL_ 1282 APAFcStatCSM 0 "NO_FOCUS" 1 "FOCUS" ;
VAL_ 1282 RemLftVehRmCstChgSetReq 0 "NO_ACTION" 1 "OFF" 2 "ON" 3 "RESERVED_3" 4 "RESERVED_4" 5 "RESERVED_5" 6 "RESERVED_6" 7 "RESERVED_7" ;
VAL_ 1282 RemInVehRmCstChgSetReq 0 "NO_ACTION" 1 "OFF" 2 "ON" 3 "RESERVED_3" 4 "RESERVED_4" 5 "RESERVED_5" 6 "RESERVED_6" 7 "RESERVED_7" ;
VAL_ 1283 CustMdDrvlCstChngSetReq 0 "NO ACTION" 1 "CUSTOM_MODE_1" 2 "CUSTOM_MODE_2" 3 "CUSTOM_MODE_3" 4 "CUSTOM_MODE_4" 5 "CUSTOM_MODE_5" 6 "CUSTOM_MODE_6" 7 "CUSTOM_MODE_7" ;
VAL_ 1283 CustMdSpnCstChngSetReq 0 "NO_ACTION" 1 "CUSTOM_MODE_1" 2 "CUSTOM_MODE_2" 3 "CUSTOM_MODE_3" 4 "CUSTOM_MODE_4" 5 "CUSTOM_MODE_5" 6 "CUSTOM_MODE_6" 7 "CUSTOM_MODE_7" ;
VAL_ 1283 CustMdSndCstChngSetReq 0 "NO_ACTION" 1 "CUSTOM_MODE_1" 2 "CUSTOM_MODE_2" 3 "CUSTOM_MODE_3" 4 "CUSTOM_MODE_4" 5 "CUSTOM_MODE_5" 6 "CUSTOM_MODE_6" 7 "CUSTOM_MODE_7" ;
VAL_ 1283 CustMdRideHghtCstChngSetReq 0 "NO_ACTION" 1 "CUSTOM_MODE_1" 2 "CUSTOM_MODE_2" 3 "CUSTOM_MODE_3" 4 "CUSTOM_MODE_4" 5 "CUSTOM_MODE_5" 6 "CUSTOM_MODE_6" 7 "CUSTOM_MODE_7" ;
VAL_ 1283 CustMdStrCstChngSetReq 0 "NO_ACTION" 1 "CUSTOM_MODE_1" 2 "CUSTOM_MODE_2" 3 "CUSTOM_MODE_3" 4 "CUSTOM_MODE_4" 5 "CUSTOM_MODE_5" 6 "CUSTOM_MODE_6" 7 "CUSTOM_MODE_7" ;
VAL_ 1283 EsyExtCstChgSetReq 0 "NO_ACTION" 1 "OFF" 2 "ON" 3 "RESERVED_3" 4 "RESERVED_4" 5 "RESERVED_5" 6 "RESERVED_6" 7 "RESERVED_7" ;
VAL_ 1283 DrvrAlrtTypCstChgStReq 0 "SETTING_UNKNOWN" 1 "CHIME" 2 "SEAT" 3 "RESERVED_3" 4 "RESERVED_4" 5 "RESERVED_5" 6 "RESERVED_6" 7 "RESERVED_7" ;
VAL_ 1283 DayTmTlLtsCstChgSetReq 0 "NO_ACTION" 1 "OFF" 2 "ON" 3 "RESERVED_3" 4 "RESERVED_4" 5 "RESERVED_5" 6 "RESERVED_6" 7 "RESERVED_7" ;
VAL_ 1283 FrntPCMRspTypCstChgSetReq 0 "NO_ACTION" 1 "OFF" 2 "ALERT" 3 "ALERT_AND_BRAKE" 4 "ALERT_AND_BRAKE_AND_STEER" 5 "RESERVED_5" 6 "RESERVED_6" 7 "RESERVED_7" ;
VAL_ 1283 ExitLghtngCstChgSetReq 0 "NO_ACTION" 1 "OFF" 2 "THIRTY_SECONDS_DEFAULT" 3 "ONE_MINUTE" 4 "TWO_MINUTES" 5 "RESERVED_5" 6 "RESERVED_6" 7 "RESERVED_7" ;
VAL_ 1283 FrwdImpMtgnOpSlctCstChgSetReq 0 "NO_ACTION" 1 "OFF" 2 "ALERT" 3 "ALERT_BRAKE" 4 "ALERT_BRAKE_STEER" 5 "RESERVED_5" 6 "RESERVED_6" 7 "RESERVED_7" ;
VAL_ 1283 FrtRdHgtGPSCstChngSetReq 0 "NO_ACTION" 1 "OFF" 2 "ON" 3 "RESERVED_3" 4 "RESERVED_4" 5 "RESERVED_5" 6 "RESERVED_6" 7 "RESERVED_7" ;
VAL_ 1283 HFRCCstChgSetReq 0 "NO_ACTION" 1 "OFF" 2 "OPEN_AND_CLOSE" 3 "OPEN_ONLY" 4 "RESERVED_4" 5 "RESERVED_5" 6 "RESERVED_6" 7 "RESERVED_7" ;
VAL_ 1283 GoNotfrCstChgSetReq 0 "NO_ACTION" 1 "OFF" 2 "ON" 3 "RESERVED_3" 4 "RESERVED_4" 5 "RESERVED_5" 6 "RESERVED_6" 7 "RESERVED_7" ;
VAL_ 1283 GlrFrHgBmRspTypCstChgSetReq 0 "NO_ACTION" 1 "AUTOMATIC_HIGH_BEAM" 2 "GLARE_FREE_HIGH_BEAM" 3 "RESERVED_3" 4 "RESERVED_4" 5 "RESERVED_5" 6 "RESERVED_6" 7 "RESERVED_7" ;
VAL_ 1283 APAExtPrkSftBtnStat 0 "NOT_PRESSED" 1 "PRESSED" ;
VAL_ 1283 JckKnfDtnCstChgSetReq 0 "No_Action" 1 "Off" 2 "On" ;
VAL_ 1283 IonzrCtrlCstChgSetReq 0 "NO_ACTION" 1 "OFF" 2 "ON" 3 "RESERVED_3" 4 "RESERVED_4" 5 "RESERVED_5" 6 "RESERVED_6" 7 "RESERVED_7" ;
VAL_ 1284 TAC_AudConctOutcm 0 "NO_ACTION" 1 "REQUEST_GRANTED" 2 "REQUEST_DENIED" 3 "RESERVED_1" 4 "RESERVED_2" 5 "RESERVED_3" 6 "RESERVED_4" 7 "RESERVED_5" 8 "RESERVED_6" 9 "RESERVED_7" 10 "RESERVED_8" 11 "RESERVED_9" 12 "RESERVED_10" 13 "RESERVED_11" 14 "RESERVED_12" 15 "RESERVED_13" ;
VAL_ 1284 TAC_AudChConctStat 0 "NO_ACTION" 1 "MIX_PROMPT" 2 "MUTEX_PROMPT" 3 "RING_TONE" 4 "PHONE" 5 "EMERGENCY_PHONE" 6 "RESERVED_1" 7 "RESERVED_2" 8 "RESERVED_3" 9 "RESERVED_4" 10 "RESERVED_5" 11 "RESERVED_6" 12 "RESERVED_7" 13 "RESERVED_8" 14 "RESERVED_9" 15 "RESERVED_10" ;
VAL_ 1284 TDOSWCCSR_ChgSetReq 0 "NO_ACTION" 1 "OFF" 2 "ON" 3 "RESERVED_3" 4 "RESERVED_4" 5 "RESERVED_5" 6 "RESERVED_6" 7 "RESERVED_7" ;
VAL_ 1284 TDOSWCCSR_DecSwAct 0 "FALSE" 1 "TRUE" ;
VAL_ 1284 TDOSWCCSR_IncSwAct 0 "FALSE" 1 "TRUE" ;
VAL_ 1284 InfoSysStat 0 "Sleep" 1 "AnimationInit" 2 "HMI_Init" 3 "HMI_Inactive" 4 "Start" 5 "Run" 6 "Propulsion" 7 "Accessory" 8 "LocalInfotainment" 9 "LocalPhone" 10 "LocalValet" 11 "LocalEject" 12 "ValetMode" 13 "TheftLocked" 14 "NoCalibration" 15 "NoVIN" 16 "RemoteReflashProgramming" 17 "OffMode" ;
VAL_ 1284 AirQltySensCstChgSetReq 0 "NO_ACTION" 1 "OFF" 2 "LOW_SENSITIVITY" 3 "HI_SENSITIVITY" 4 "RESERVED_4" 5 "RESERVED_5" 6 "RESERVED_6" 7 "RESERVED_7" ;
VAL_ 1284 AdpLghtRspTypCstChgSetReq 0 "NO_ACTION" 1 "OFF" 2 "CORNER_AND_CURVE_LIGHTING" 3 "INTELLIGENT_LIGHT_DISTRIBUTION" 4 "INTELLIGENT_LIGHT_DISTRIBUTION_GPS_ASSISTANCE" 5 "RESERVED_5" 6 "RESERVED_6" 7 "RESERVED_7" ;
VAL_ 1284 AutoAirDstCstChgSetReq 0 "NO_ACTION" 1 "DIFFUSE_AIRFLOW" 2 "NORMAL" 3 "DIRECT_AIRFLOW" 4 "OSCILLATING_AIRFLOW" 5 "RESERVED_5" 6 "RESERVED_6" 7 "RESERVED_7" ;
VAL_ 1284 AutUnlckCstChgSetReq 0 "NO_ACTION" 1 "OFF" 2 "ALL_DOORS" 3 "DRIVER_DOOR" 4 "RESERVED_4" 5 "RESERVED_5" 6 "RESERVED_6" 7 "RESERVED_7" ;
VAL_ 1284 AutDrvLckCstChgSetReq 0 "NO_ACTION" 1 "OFF" 2 "ON" 3 "RESERVED_3" 4 "RESERVED_4" 5 "RESERVED_5" 6 "RESERVED_6" 7 "RESERVED_7" ;
VAL_ 1284 AutoFanCstChgSetReq 0 "NO_ACTION" 1 "LOW" 2 "NORMAL" 3 "HIGH" 4 "RESERVED_4" 5 "RESERVED_5" 6 "RESERVED_6" 7 "RESERVED_7" ;
VAL_ 1284 AutoDfgCstChgSetReq 0 "NO_ACTION" 1 "OFF" 2 "ON" 3 "RESERVED_3" 4 "RESERVED_4" 5 "RESERVED_5" 6 "RESERVED_6" 7 "RESERVED_7" ;
VAL_ 1284 AutoCoolStCstChgSetReq 0 "NO_ACTION" 1 "OFF" 2 "ON" 3 "RESERVED_3" 4 "RESERVED_4" 5 "RESERVED_5" 6 "RESERVED_6" 7 "RESERVED_7" ;
VAL_ 1284 AutoMemRclCstChgSetReq 0 "NO_ACTION" 1 "OFF" 2 "ON" 3 "AUTO_MEMORY_RECALL" 4 "EASY_EXIT" 5 "AUTO_MEMORY_AND_EASY_EXIT_RECALLS" 6 "RESERVED6" 7 "RESERVED7" ;
VAL_ 1284 AutoHtdStCstChgSetReq 0 "NO_ACTION" 1 "OFF" 2 "ON" 3 "RESERVED_3" 4 "RESERVED_4" 5 "RESERVED_5" 6 "RESERVED_6" 7 "RESERVED_7" ;
VAL_ 1284 ClstrDspAnmReq 0 "NoAction" 1 "Ready" 2 "WelcomePlay" 3 "StartPlay" 4 "ShutdownPlay" ;
VAL_ 1284 AutoRrWpCstChgSetReq 0 "NO_ACTION" 1 "OFF" 2 "ON" 3 "RESERVED_3" 4 "RESERVED_4" 5 "RESERVED_5" 6 "RESERVED_6" 7 "RESERVED_7" ;
VAL_ 1284 AutoMrFldCstChgSetReq 0 "NO_ACTION" 1 "OFF" 2 "ON" 3 "RESERVED_3" 4 "RESERVED_4" 5 "RESERVED_5" 6 "RESERVED_6" 7 "RESERVED_7" ;
VAL_ 1284 APACrssBckInSftBtnStat 0 "NOT_PRESSED" 1 "PRESSED" ;
VAL_ 1284 CrgBedVwAutoLgtCstChgSetReq 0 "No_Action" 1 "Off" 2 "On" ;
VAL_ 615 IntAmbBrghtnsCtrlSetReq 0 "No Action" 1 "BrightnessLevel 1" 2 "BrightnessLevel 2" 3 "BrightnessLevel 3" 4 "BrightnessLevel 4" 5 "ReservedLevel 5" 6 "ReservedLevel 6" 7 "ReservedLevel 7" ;
VAL_ 1332 LclTmYrVal_Inv 0 "FALSE" 1 "TRUE" ;
VAL_ 1332 LclTmMinVal_Inv 0 "FALSE" 1 "TRUE" ;
VAL_ 1332 LclTmDayVal_Inv 0 "FALSE" 1 "TRUE" ;
VAL_ 1332 LclTmSecVal_Inv 0 "FALSE" 1 "TRUE" ;
VAL_ 1332 LclTmHrVal_Inv 0 "FALSE" 1 "TRUE" ;
VAL_ 1332 LclTmMthVal 0 "Unknown" 1 "January" 2 "February" 3 "March" 4 "April" 5 "May" 6 "June" 7 "July" 8 "August" 9 "September" 10 "October" 11 "November" 12 "December" ;
VAL_ 1332 LclTmMthVal_Inv 0 "FALSE" 1 "TRUE" ;
VAL_ 1308 FrtCntrStckFvrtUpSw 0 "Released" 1 "Pressed" ;
VAL_ 1308 FrtCntrStckFvrtDnSw 0 "Released" 1 "Pressed" ;
VAL_ 1308 FrtCntrStckEjectSw 0 "Released" 1 "Pressed" ;
VAL_ 1308 FrtCntrStckDiscAuxSw 0 "Released" 1 "Pressed" ;
VAL_ 1308 FrtCntrStckBndSw 0 "Released" 1 "Pressed" ;
VAL_ 1308 FrtCntrStckBnchBtnID_VirtSw 0 "Released" 1 "Pressed" ;
VAL_ 1308 FrtCntrStckBackSw 0 "Released" 1 "Pressed" ;
VAL_ 1308 FrtCntrStckAllRelSw 0 "Released" 1 "Pressed" ;
VAL_ 1308 FrtCntrStckSw24 0 "Released" 1 "Pressed" ;
VAL_ 1308 FrtCntrStckSw23 0 "Released" 1 "Pressed" ;
VAL_ 1308 FrtCntrStckStrgeUnlckSw 0 "Released" 1 "Pressed" ;
VAL_ 1308 FrtCntrStckPwrSw 0 "Released" 1 "Pressed" ;
VAL_ 1308 FrtCntrStckPrevSw 0 "Released" 1 "Pressed" ;
VAL_ 1308 FrtCntrStckNextSw 0 "Released" 1 "Pressed" ;
VAL_ 1308 FrtCntrStckMenuSw 0 "Released" 1 "Pressed" ;
VAL_ 1308 FrtCntrStckHomeSw 0 "Released" 1 "Pressed" ;
VAL_ 1308 FrtCntrStckSw32 0 "Released" 1 "Pressed" ;
VAL_ 1308 FrtCntrStckSw31 0 "Released" 1 "Pressed" ;
VAL_ 1308 FrtCntrStckSw30 0 "Released" 1 "Pressed" ;
VAL_ 1308 FrtCntrStckSw29 0 "Released" 1 "Pressed" ;
VAL_ 1308 FrtCntrStckSw28 0 "Released" 1 "Pressed" ;
VAL_ 1308 FrtCntrStckSw27 0 "Released" 1 "Pressed" ;
VAL_ 1308 FrtCntrStckSw26 0 "Released" 1 "Pressed" ;
VAL_ 1308 FrtCntrStckSw25 0 "Released" 1 "Pressed" ;
